VERSION "$Format:%h$"

NS_ :

BS_:

BU_: APB APP APS BCCEN BDY DAS DBG EAS EPAS EPAS2 EPAS3S EPB EPBM ESP GTW GTWU IBST IC MCU OCS PARK PARK3 RADAR RCM RT3000 SCCM SDM SEC TAS TAS2 TAS2DBG TOOL TPMS VCSEATD VCSEATP

BO_ 1860 VCSEATD_recallStatus: 1 VCSEATD
 SG_ VCSEATD_systemRecallStatus : 0|2@1+ (1,0) [0|3] "" GTW
 SG_ VCSEATD_seatRecallStatus : 2|2@1+ (1,0) [0|3] "" GTW

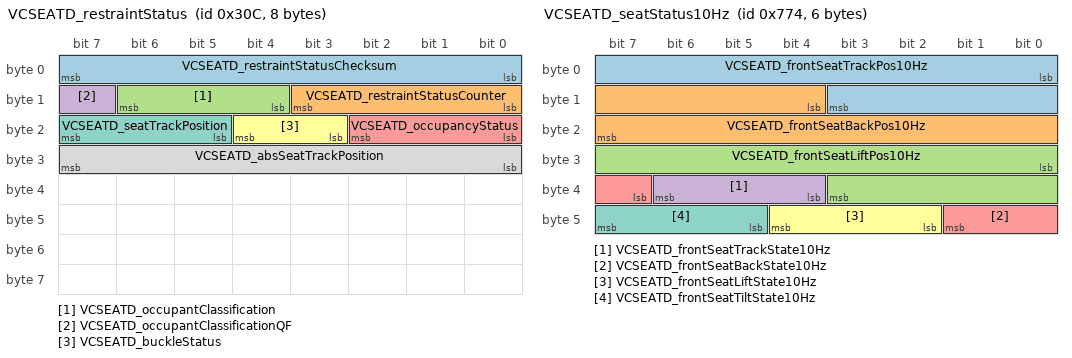
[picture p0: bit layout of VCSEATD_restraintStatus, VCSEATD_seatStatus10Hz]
BO_ 780 VCSEATD_restraintStatus: 8 VCSEATD
 SG_ VCSEATD_restraintStatusChecksum : 0|8@1+ (1,0) [0|255] "" Vector__XXX
 SG_ VCSEATD_restraintStatusCounter : 8|4@1+ (1,0) [0|15] "" Vector__XXX
 SG_ VCSEATD_occupantClassification : 12|3@1+ (1,0) [0|7] "" GTW
 SG_ VCSEATD_occupantClassificationQF : 15|1@1+ (1,0) [0|1] "" GTW
 SG_ VCSEATD_occupancyStatus : 16|3@1+ (1,0) [0|7] "" BCCEN,GTW
 SG_ VCSEATD_buckleStatus : 19|2@1+ (1,0) [0|3] "" APP,APS,GTW
 SG_ VCSEATD_seatTrackPosition : 21|3@1+ (1,0) [0|7] "" GTW
 SG_ VCSEATD_absSeatTrackPosition : 24|8@1+ (1,0) [0|254] "%" GTW

BO_ 1250 VCSEATD_seatStatus: 8 VCSEATD
 SG_ VCSEATD_seatStatusIndex M : 0|3@1+ (1,0) [0|5] "" GTW
 SG_ VCSEATD_frontSeatTrackPos m0 : 8|16@1- (1,0) [-32768|32767] "" GTW
 SG_ VCSEATD_frontSeatTrackCurrent m0 : 24|12@1- (0.01,0) [-20.48|20.47] "A" GTW
 SG_ VCSEATD_frontSeatTrackDuty m0 : 36|12@1- (0.1,0) [-204.8|204.7] "%" GTW
 SG_ VCSEATD_frontSeatTrackState m0 : 48|3@1+ (1,0) [0|5] "" GTW
 SG_ VCSEATD_frontSeatTrackCalibrated m0 : 51|1@1+ (1,0) [0|1] "" GTW
 SG_ VCSEATD_frontSeatTrackLog m0 : 52|1@1+ (1,0) [0|1] "" GTW
 SG_ VCSEATD_frontSeatBackPos m1 : 8|16@1- (1,0) [-32768|32767] "" GTW
 SG_ VCSEATD_frontSeatBackCurrent m1 : 24|12@1- (0.01,0) [-20.48|20.47] "A" GTW
 SG_ VCSEATD_frontSeatBackDuty m1 : 36|12@1- (0.1,0) [-204.8|204.7] "%" GTW
 SG_ VCSEATD_frontSeatBackState m1 : 48|3@1+ (1,0) [0|5] "" GTW
 SG_ VCSEATD_frontSeatBackCalibrated m1 : 51|1@1+ (1,0) [0|1] "" GTW
 SG_ VCSEATD_frontSeatBackLog m1 : 52|1@1+ (1,0) [0|1] "" GTW
 SG_ VCSEATD_frontSeatLiftPos m2 : 8|16@1- (1,0) [-32768|32767] "" GTW
 SG_ VCSEATD_frontSeatLiftCurrent m2 : 24|12@1- (0.01,0) [-20.48|20.47] "A" GTW
 SG_ VCSEATD_frontSeatLiftDuty m2 : 36|12@1- (0.1,0) [-204.8|204.7] "%" GTW
 SG_ VCSEATD_frontSeatLiftState m2 : 48|3@1+ (1,0) [0|5] "" GTW
 SG_ VCSEATD_frontSeatLiftCalibrated m2 : 51|1@1+ (1,0) [0|1] "" GTW
 SG_ VCSEATD_frontSeatLiftLog m2 : 52|1@1+ (1,0) [0|1] "" GTW
 SG_ VCSEATD_frontSeatTiltPos m3 : 8|16@1- (1,0) [-32768|32767] "" GTW
 SG_ VCSEATD_frontSeatTiltCurrent m3 : 24|12@1- (0.01,0) [-20.48|20.47] "A" GTW
 SG_ VCSEATD_frontSeatTiltDuty m3 : 36|12@1- (0.1,0) [-204.8|204.7] "%" GTW
 SG_ VCSEATD_frontSeatTiltState m3 : 48|3@1+ (1,0) [0|5] "" GTW
 SG_ VCSEATD_frontSeatTiltCalibrated m3 : 51|1@1+ (1,0) [0|1] "" GTW
 SG_ VCSEATD_frontSeatTiltLog m3 : 52|1@1+ (1,0) [0|1] "" GTW
 SG_ VCSEATD_lumbarAState m4 : 3|3@1+ (1,0) [0|5] "" GTW
 SG_ VCSEATD_lumbarBState m4 : 8|3@1+ (1,0) [0|5] "" GTW
 SG_ VCSEATD_lumbarAPressureHpa m4 : 16|16@1+ (1,0) [0|65535] "" GTW
 SG_ VCSEATD_lumbarBPressureHpa m4 : 32|16@1+ (1,0) [0|65535] "" GTW
 SG_ VCSEATD_lumbarActiveTooLongErr m4 : 48|1@1+ (1,0) [0|1] "" GTW
 SG_ VCSEATD_lumbarMaxPErr m4 : 49|1@1+ (1,0) [0|1] "" GTW
 SG_ VCSEATD_lumbarOvercurrentErr m4 : 50|1@1+ (1,0) [0|1] "" GTW
 SG_ VCSEATD_lumbarMaxOperatingPErr m4 : 51|1@1+ (1,0) [0|1] "" GTW
 SG_ VCSEATD_lumbarMinPErr m4 : 52|1@1+ (1,0) [0|1] "" GTW
 SG_ VCSEATD_lumbarGeneralErr m4 : 53|1@1+ (1,0) [0|1] "" GTW
 SG_ VCSEATD_lumbarDevMaxPumpPressA m4 : 54|1@1+ (1,0) [0|1] "" GTW
 SG_ VCSEATD_lumbarDevMaxPumpPressB m4 : 55|1@1+ (1,0) [0|1] "" GTW
 SG_ VCSEATD_frontSeatTrackPosReal m5 : 3|12@1- (1,0) [-2048|2047] "mm" GTW
 SG_ VCSEATD_frontSeatBackPosReal m5 : 16|12@1- (0.1,0) [-204.8|204.7] "deg" GTW
 SG_ VCSEATD_frontSeatLiftPosReal m5 : 28|12@1- (1,0) [-2048|2047] "mm" GTW
 SG_ VCSEATD_frontSeatTiltPosReal m5 : 40|12@1- (0.1,0) [-204.8|204.7] "deg" GTW

BO_ 1908 VCSEATD_seatStatus10Hz: 6 VCSEATD
 SG_ VCSEATD_frontSeatTrackPos10Hz : 0|12@1- (1,0) [-2048|2047] "" GTW
 SG_ VCSEATD_frontSeatBackPos10Hz : 12|12@1- (1,0) [-2048|2047] "" GTW
 SG_ VCSEATD_frontSeatLiftPos10Hz : 24|12@1- (1,0) [-2048|2047] "" GTW
 SG_ VCSEATD_frontSeatTrackState10Hz : 36|3@1+ (1,0) [0|5] "" GTW
 SG_ VCSEATD_frontSeatBackState10Hz : 39|3@1+ (1,0) [0|5] "" GTW
 SG_ VCSEATD_frontSeatLiftState10Hz : 42|3@1+ (1,0) [0|5] "" GTW
 SG_ VCSEATD_frontSeatTiltState10Hz : 45|3@1+ (1,0) [0|5] "" GTW

BO_ 738 VCSEATD_seatStatus2: 6 VCSEATD
 SG_ VCSEATD_seatStatus2Index M : 0|2@1+ (1,0) [0|3] "" Vector__XXX
 SG_ VCSEATD_frontSeatHeatCurrent m0 : 4|12@1+ (0.01,0) [0|40.95] "A" GTW
 SG_ VCSEATD_frontSeatHeatDuty m0 : 16|8@1+ (1,0) [0|255] "%" GTW
 SG_ VCSEATD_frontSeatHeatTmp m0 : 24|12@1- (0.05,0) [-40|80] "degC" GTW
 SG_ VCSEATD_frontSeatHeatTmpTarget m0 : 36|8@1- (0.5,0) [0|60] "degC" GTW
 SG_ VCSEATD_frontSeatHeatInhibited m0 : 44|1@1+ (1,0) [0|1] "" GTW
 SG_ VCSEATD_frontSeatHeatPowered m0 : 45|1@1+ (1,0) [0|1] "" Vector__XXX
 SG_ VCSEATD_frontSeatHeatTmpVoltage m1 : 4|10@1+ (0.01,0) [0|10.23] "V" Vector__XXX
 SG_ VCSEATD_frontOccupancyVoltage m2 : 4|10@1+ (0.01,0) [0|10.23] "V" GTW
 SG_ VCSEATD_frontBuckleVoltage m2 : 14|10@1+ (0.01,0) [0|10.23] "V" GTW
 SG_ VCSEATD_seatTrackPositionVoltage m2 : 24|10@1+ (0.01,0) [0|10.23] "V" Vector__XXX

BO_ 931 VCSEATD_status: 6 VCSEATD
 SG_ VCSEATD_statusIndex M : 0|1@1+ (1,0) [0|1] "" Vector__XXX
 SG_ VCSEATD_loadShedPriority m0 : 1|8@1+ (1,0) [0|255] "" Vector__XXX
 SG_ VCSEATD_vehiclePowerStateDBG m0 : 9|2@1+ (1,0) [0|3] "" GTW
 SG_ VCSEATD_OTAState m0 : 12|1@1+ (1,0) [0|1] "" GTW
 SG_ VCSEATD_5AVoltage m0 : 13|10@1+ (0.005443676098,0) [0|5.568880648254] "V" GTW
 SG_ VCSEATD_vbatProt m0 : 23|12@1+ (0.005443676098,0) [0|22.29185362131] "V" GTW
 SG_ VCSEATD_pcbaTemperature m0 : 35|11@1+ (0.125,-40) [-40|150] "degC" GTW

BO_ 964 VCSEATD_switchStatus: 7 VCSEATD
 SG_ VCSEATD_switchStatusIndex M : 0|2@1+ (1,0) [0|2] "" GTW
 SG_ VCSEATD_frontSeatTrackBack m0 : 8|2@1+ (1,0) [0|3] "" GTW
 SG_ VCSEATD_frontSeatTrackForward m0 : 10|2@1+ (1,0) [0|3] "" GTW
 SG_ VCSEATD_frontSeatTiltDown m0 : 12|2@1+ (1,0) [0|3] "" GTW
 SG_ VCSEATD_frontSeatTiltUp m0 : 14|2@1+ (1,0) [0|3] "" GTW
 SG_ VCSEATD_frontSeatLiftDown m0 : 16|2@1+ (1,0) [0|3] "" GTW
 SG_ VCSEATD_frontSeatLiftUp m0 : 18|2@1+ (1,0) [0|3] "" GTW
 SG_ VCSEATD_frontSeatBackrestBack m0 : 20|2@1+ (1,0) [0|3] "" GTW
 SG_ VCSEATD_frontSeatBackrestForward m0 : 22|2@1+ (1,0) [0|3] "" GTW
 SG_ VCSEATD_frontSeatLumbarDown m0 : 24|2@1+ (1,0) [0|3] "" GTW
 SG_ VCSEATD_frontSeatLumbarUp m0 : 26|2@1+ (1,0) [0|3] "" GTW
 SG_ VCSEATD_frontSeatLumbarIn m0 : 28|2@1+ (1,0) [0|3] "" GTW
 SG_ VCSEATD_frontSeatLumbarOut m0 : 30|2@1+ (1,0) [0|3] "" GTW
 SG_ VCSEATD_frontBuckleSwitch m0 : 48|2@1+ (1,0) [0|3] "" GTW
 SG_ VCSEATD_frontOccupancySwitch m0 : 50|2@1+ (1,0) [0|3] "" GTW

BO_ 1761 VCSEATD_udsResponse: 8 VCSEATD
 SG_ VCSEATD_udsResponseData_H : 7|32@0+ (1,0) [0|4294967295] "" GTW,GTWU
 SG_ VCSEATD_udsResponseData_L : 39|32@0+ (1,0) [0|4294967295] "" GTW,GTWU

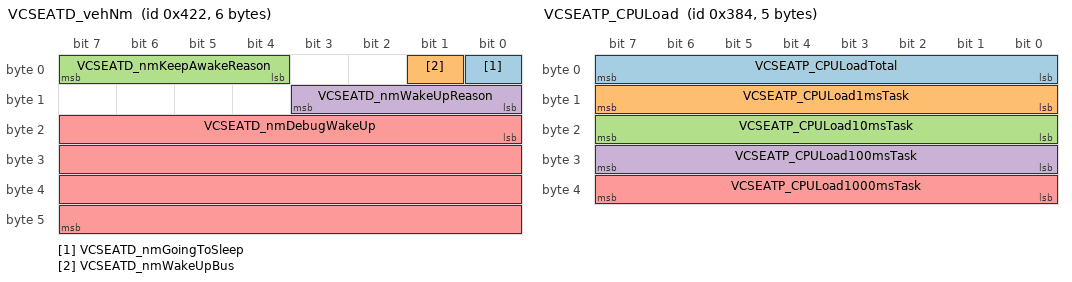
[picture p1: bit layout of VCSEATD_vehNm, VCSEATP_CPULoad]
BO_ 1058 VCSEATD_vehNm: 6 VCSEATD
 SG_ VCSEATD_nmGoingToSleep : 0|1@1+ (1,0) [0|1] "" Vector__XXX
 SG_ VCSEATD_nmWakeUpBus : 1|1@1+ (1,0) [0|1] "" Vector__XXX
 SG_ VCSEATD_nmKeepAwakeReason : 4|4@1+ (1,0) [0|15] "" GTW
 SG_ VCSEATD_nmWakeUpReason : 8|4@1+ (1,0) [0|15] "" GTW
 SG_ VCSEATD_nmDebugWakeUp : 16|32@1+ (1,0) [0|4294967295] "" GTW

BO_ 1890 VCSEATD_xcpResponse: 8 VCSEATD
 SG_ VCSEATD_xcpResponseData : 0|64@1+ (1,0) [0|1.84467440737096E+19] "" Vector__XXX

BO_ 900 VCSEATP_CPULoad: 5 VCSEATP
 SG_ VCSEATP_CPULoadTotal : 0|8@1+ (1,0) [0|255] "" Vector__XXX
 SG_ VCSEATP_CPULoad1msTask : 8|8@1+ (1,0) [0|255] "" Vector__XXX
 SG_ VCSEATP_CPULoad10msTask : 16|8@1+ (1,0) [0|255] "" Vector__XXX
 SG_ VCSEATP_CPULoad100msTask : 24|8@1+ (1,0) [0|255] "" Vector__XXX
 SG_ VCSEATP_CPULoad1000msTask : 32|8@1+ (1,0) [0|255] "" Vector__XXX

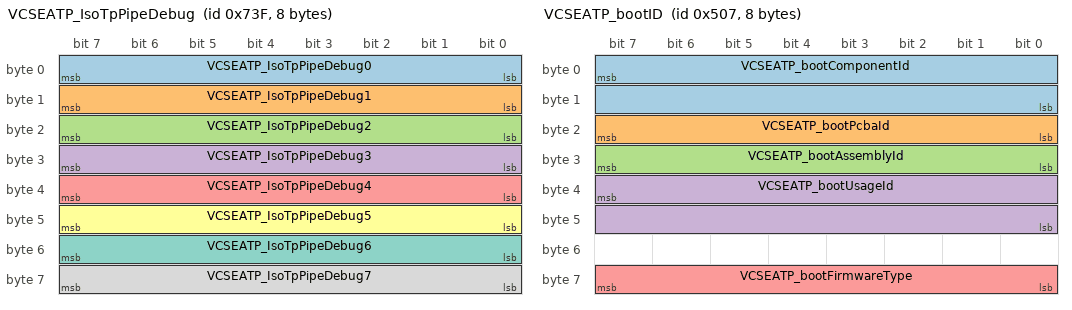
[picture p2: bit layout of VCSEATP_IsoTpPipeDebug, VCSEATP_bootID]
BO_ 1855 VCSEATP_IsoTpPipeDebug: 8 VCSEATP
 SG_ VCSEATP_IsoTpPipeDebug0 : 0|8@1+ (1,0) [0|255] "" Vector__XXX
 SG_ VCSEATP_IsoTpPipeDebug1 : 8|8@1+ (1,0) [0|255] "" Vector__XXX
 SG_ VCSEATP_IsoTpPipeDebug2 : 16|8@1+ (1,0) [0|255] "" Vector__XXX
 SG_ VCSEATP_IsoTpPipeDebug3 : 24|8@1+ (1,0) [0|255] "" Vector__XXX
 SG_ VCSEATP_IsoTpPipeDebug4 : 32|8@1+ (1,0) [0|255] "" Vector__XXX
 SG_ VCSEATP_IsoTpPipeDebug5 : 40|8@1+ (1,0) [0|255] "" Vector__XXX
 SG_ VCSEATP_IsoTpPipeDebug6 : 48|8@1+ (1,0) [0|255] "" Vector__XXX
 SG_ VCSEATP_IsoTpPipeDebug7 : 56|8@1+ (1,0) [0|255] "" Vector__XXX

BO_ 579 VCSEATP_LVPowerState: 1 VCSEATP
 SG_ VCSEATP_lumbarLVState : 0|2@1+ (1,0) [0|3] "" GTW

BO_ 1315 VCSEATP_alertCleared: 2 VCSEATP
 SG_ VCSEATP_alertClearedID : 0|15@1+ (1,0) [0|445] "" Vector__XXX

BO_ 1374 VCSEATP_alertLog: 8 VCSEATP
 SG_ VCSEATP_alertID M : 0|15@1+ (1,0) [0|445] "" GTW
 SG_ VCSEATP_alertType : 15|1@1+ (1,0) [0|1] "" GTW
 SG_ VCSEATP_a000_alertDataW0 m0 : 16|16@1+ (1,0) [0|65535] "" Vector__XXX
 SG_ VCSEATP_a000_alertDataW1 m0 : 32|16@1+ (1,0) [0|65535] "" Vector__XXX
 SG_ VCSEATP_a000_alertDataW2 m0 : 48|16@1+ (1,0) [0|65535] "" Vector__XXX
 SG_ VCSEATP_a001_InternalWatchdog m1 : 16|1@1+ (1,0) [0|1] "" GTW
 SG_ VCSEATP_a002_CPUUndervoltage m2 : 16|1@1+ (1,0) [0|1] "" GTW
 SG_ VCSEATP_a002_PowerOnReset m2 : 17|1@1+ (1,0) [0|1] "" GTW
 SG_ VCSEATP_a003_AssertID m3 : 16|16@1+ (1,0) [0|65535] "" GTW
 SG_ VCSEATP_a003_LineNumber m3 : 32|16@1+ (1,0) [0|65535] "" GTW
 SG_ VCSEATP_a003_Data m3 : 48|16@1+ (1,0) [0|65535] "" GTW
 SG_ VCSEATP_a005_busID0 m5 : 16|4@1+ (1,0) [0|15] "" GTW
 SG_ VCSEATP_a005_faults0 m5 : 20|12@1+ (1,0) [0|4095] "" GTW
 SG_ VCSEATP_a005_busID1 m5 : 32|4@1+ (1,0) [0|15] "" GTW
 SG_ VCSEATP_a005_faults1 m5 : 36|12@1+ (1,0) [0|4095] "" GTW
 SG_ VCSEATP_a010_UnderVoltDetected m10 : 16|1@1+ (1,0) [0|1] "" GTW
 SG_ VCSEATP_a010_UnderVoltTimeout m10 : 17|1@1+ (1,0) [0|1] "" GTW
 SG_ VCSEATP_a012_ClockError m12 : 16|1@1+ (1,0) [0|1] "" GTW
 SG_ VCSEATP_a012_FlashError m12 : 17|1@1+ (1,0) [0|1] "" GTW
 SG_ VCSEATP_a012_SoftwareReset m12 : 18|1@1+ (1,0) [0|1] "" GTW
 SG_ VCSEATP_a012_CheckstopReset m12 : 19|1@1+ (1,0) [0|1] "" GTW
 SG_ VCSEATP_a012_DebugReset m12 : 20|1@1+ (1,0) [0|1] "" GTW
 SG_ VCSEATP_a012_ExternalReset m12 : 21|1@1+ (1,0) [0|1] "" GTW
 SG_ VCSEATP_a013_LogQueueFull m13 : 16|1@1+ (1,0) [0|1] "" GTW
 SG_ VCSEATP_a013_ClearQueueFull m13 : 17|1@1+ (1,0) [0|1] "" GTW
 SG_ VCSEATP_a015_NVMMRecordNotFound m15 : 16|1@1+ (1,0) [0|1] "" GTW
 SG_ VCSEATP_a015_NVMMCRCMismatch m15 : 17|1@1+ (1,0) [0|1] "" GTW
 SG_ VCSEATP_a015_NVMMVersionMismatch m15 : 18|1@1+ (1,0) [0|1] "" GTW
 SG_ VCSEATP_a015_NVMMRecordUpgraded m15 : 19|1@1+ (1,0) [0|1] "" GTW
 SG_ VCSEATP_a015_NVMMMemOverflow m15 : 20|1@1+ (1,0) [0|1] "" GTW
 SG_ VCSEATP_a015_NVMMWriteFailed m15 : 21|1@1+ (1,0) [0|1] "" GTW
 SG_ VCSEATP_a021_Task1msLate m21 : 16|1@1+ (1,0) [0|1] "" GTW
 SG_ VCSEATP_a021_Task1msStarved m21 : 17|1@1+ (1,0) [0|1] "" GTW
 SG_ VCSEATP_a021_Task1msMissed m21 : 18|1@1+ (1,0) [0|1] "" GTW
 SG_ VCSEATP_a021_Task10msLate m21 : 19|1@1+ (1,0) [0|1] "" GTW
 SG_ VCSEATP_a021_Task10msStarved m21 : 20|1@1+ (1,0) [0|1] "" GTW
 SG_ VCSEATP_a021_Task10msMissed m21 : 21|1@1+ (1,0) [0|1] "" GTW
 SG_ VCSEATP_a021_Task100msLate m21 : 22|1@1+ (1,0) [0|1] "" GTW
 SG_ VCSEATP_a021_Task100msStarved m21 : 23|1@1+ (1,0) [0|1] "" GTW
 SG_ VCSEATP_a021_Task100msMissed m21 : 24|1@1+ (1,0) [0|1] "" GTW
 SG_ VCSEATP_a021_Task1000msLate m21 : 25|1@1+ (1,0) [0|1] "" GTW
 SG_ VCSEATP_a021_Task1000msStarved m21 : 26|1@1+ (1,0) [0|1] "" GTW
 SG_ VCSEATP_a021_Task1000msMissed m21 : 27|1@1+ (1,0) [0|1] "" GTW
 SG_ VCSEATP_a022_TaskInitErrorCount m22 : 16|8@1+ (1,0) [0|255] "" GTW
 SG_ VCSEATP_a022_TaskInitError0 m22 : 24|8@1+ (1,0) [0|255] "" GTW
 SG_ VCSEATP_a022_TaskInitError1 m22 : 32|8@1+ (1,0) [0|255] "" GTW
 SG_ VCSEATP_a022_TaskInitError2 m22 : 40|8@1+ (1,0) [0|255] "" GTW
 SG_ VCSEATP_a022_TaskInitError3 m22 : 48|8@1+ (1,0) [0|255] "" GTW
 SG_ VCSEATP_a022_TaskInitError4 m22 : 56|8@1+ (1,0) [0|255] "" GTW
 SG_ VCSEATP_a030_logId m30 : 16|4@1+ (1,0) [0|15] "" GTW
 SG_ VCSEATP_a031_uds_bytes_0 m31 : 16|8@1+ (1,0) [0|255] "" GTW
 SG_ VCSEATP_a031_uds_bytes_1 m31 : 24|8@1+ (1,0) [0|255] "" GTW
 SG_ VCSEATP_a031_uds_bytes_2 m31 : 32|8@1+ (1,0) [0|255] "" GTW
 SG_ VCSEATP_a031_uds_bytes_3 m31 : 40|8@1+ (1,0) [0|255] "" GTW
 SG_ VCSEATP_a031_uds_bytes_4 m31 : 48|8@1+ (1,0) [0|255] "" GTW
 SG_ VCSEATP_a031_uds_bytes_5 m31 : 56|8@1+ (1,0) [0|255] "" GTW
 SG_ VCSEATP_a041_CPULoadTotal m41 : 16|8@1+ (1,0) [0|255] "" GTW
 SG_ VCSEATP_a041_CPULoad1msTask m41 : 24|8@1+ (1,0) [0|255] "" GTW
 SG_ VCSEATP_a041_CPULoad10msTask m41 : 32|8@1+ (1,0) [0|255] "" GTW
 SG_ VCSEATP_a041_CPULoad100msTask m41 : 40|8@1+ (1,0) [0|255] "" GTW
 SG_ VCSEATP_a041_CPULoad1000msTask m41 : 48|8@1+ (1,0) [0|255] "" GTW
 SG_ VCSEATP_a041_CPULoadNVMMTask m41 : 56|8@1+ (1,0) [0|255] "" GTW
 SG_ VCSEATP_a042_Usage1msTask m42 : 16|8@1+ (1,0) [0|255] "" GTW
 SG_ VCSEATP_a042_Usage10msTask m42 : 24|8@1+ (1,0) [0|255] "" GTW
 SG_ VCSEATP_a042_Usage100msTask m42 : 32|8@1+ (1,0) [0|255] "" GTW
 SG_ VCSEATP_a042_Usage1000msTask m42 : 40|8@1+ (1,0) [0|255] "" GTW
 SG_ VCSEATP_a042_UsageUDSTask m42 : 48|8@1+ (1,0) [0|255] "" GTW
 SG_ VCSEATP_a042_UsageNVMMTask m42 : 56|8@1+ (1,0) [0|255] "" GTW
 SG_ VCSEATP_a043_CallTrace0 m43 : 16|24@1+ (1,0) [0|16777215] "" GTW
 SG_ VCSEATP_a043_CallTrace1 m43 : 40|24@1+ (1,0) [0|16777215] "" GTW
 SG_ VCSEATP_a044_CallTrace0 m44 : 16|24@1+ (1,0) [0|16777215] "" GTW
 SG_ VCSEATP_a044_CallTrace1 m44 : 40|24@1+ (1,0) [0|16777215] "" GTW
 SG_ VCSEATP_a045_CallTrace0 m45 : 16|24@1+ (1,0) [0|16777215] "" GTW
 SG_ VCSEATP_a045_CallTrace1 m45 : 40|24@1+ (1,0) [0|16777215] "" GTW
 SG_ VCSEATP_a046_CallTrace0 m46 : 16|24@1+ (1,0) [0|16777215] "" GTW
 SG_ VCSEATP_a046_CallTrace1 m46 : 40|24@1+ (1,0) [0|16777215] "" GTW
 SG_ VCSEATP_a058_voltageDrop m58 : 16|12@1+ (0.005443676098,0) [0|22.29185362131] "V" GTW
 SG_ VCSEATP_a058_current m58 : 28|11@1+ (0.1,0) [0|204.7] "A" GTW
 SG_ VCSEATP_a058_prevREstimate m58 : 39|12@1+ (0.00061,0) [0|2.49795] "Ohms" GTW
 SG_ VCSEATP_a058_newREstimate m58 : 51|12@1+ (0.00061,0) [0|2.49795] "Ohms" GTW
 SG_ VCSEATP_a058_faultReason m58 : 63|1@1+ (1,0) [0|1] "" GTW
 SG_ VCSEATP_a059_voltageDrop m59 : 16|12@1+ (0.005443676098,0) [0|22.29185362131] "V" GTW
 SG_ VCSEATP_a059_resistanceEstimate m59 : 28|12@1+ (0.00244,0) [0|9.9918] "Ohms" GTW
 SG_ VCSEATP_a059_current m59 : 40|12@1+ (0.05,0) [0|204.75] "A" GTW
 SG_ VCSEATP_a060_lockoutDisabled m60 : 16|1@1+ (1,0) [0|1] "" GTW
 SG_ VCSEATP_a060_resetUnlocked m60 : 17|1@1+ (1,0) [0|1] "" GTW
 SG_ VCSEATP_a063_switchChannel m63 : 16|8@1+ (1,0) [0|255] "" GTW
 SG_ VCSEATP_a063_switchType m63 : 24|8@1+ (1,0) [0|255] "" GTW
 SG_ VCSEATP_a063_ADCVoltage m63 : 32|8@1+ (0.025,0) [0|6.375] "V" GTW
 SG_ VCSEATP_a063_disconnected m63 : 40|1@1+ (1,0) [0|1] "" GTW
 SG_ VCSEATP_a063_indeterminate m63 : 41|1@1+ (1,0) [0|1] "" GTW
 SG_ VCSEATP_a063_stuckActive m63 : 42|1@1+ (1,0) [0|1] "" GTW
 SG_ VCSEATP_a063_faulted m63 : 43|1@1+ (1,0) [0|1] "" GTW
 SG_ VCSEATP_a064_busBitField m64 : 16|8@1+ (1,0) [0|255] "" GTW
 SG_ VCSEATP_a200_voltage m200 : 16|7@1+ (0.15,0) [0|19] "V" GTW
 SG_ VCSEATP_a200_motorChannels m200 : 23|16@1+ (1,0) [0|65535] "" GTW
 SG_ VCSEATP_a200_encoderVoltage m200 : 39|6@1+ (0.15,0) [0|9] "V" GTW
 SG_ VCSEATP_a200_encoder8vEn m200 : 45|1@1+ (1,0) [0|1] "" GTW
 SG_ VCSEATP_a200_motorPosition m200 : 46|7@1+ (20,0) [0|2540] "ticks" GTW
 SG_ VCSEATP_a200_phantomTicks m200 : 53|11@1- (1,0) [-1024|1023] "ticks" GTW
 SG_ VCSEATP_a201_voltage m201 : 16|7@1+ (0.15,0) [0|19] "V" GTW
 SG_ VCSEATP_a201_motorChannels m201 : 24|16@1+ (1,0) [0|65535] "" GTW
 SG_ VCSEATP_a218_motorChannels m218 : 16|16@1+ (1,0) [0|65535] "" GTW
 SG_ VCSEATP_a218_voltage m218 : 32|10@1+ (0.02,0) [0|19] "V" GTW
 SG_ VCSEATP_a218_motorCurrent m218 : 42|10@1- (0.04,0) [-20|20] "A" GTW
 SG_ VCSEATP_a218_motorDutyCycle m218 : 52|10@1+ (0.1,0) [0|100] "A" GTW
 SG_ VCSEATP_a219_motorChannels m219 : 16|16@1+ (1,0) [0|65535] "" GTW
 SG_ VCSEATP_a219_dropoutCount m219 : 32|12@1+ (1,0) [0|4095] "" GTW
 SG_ VCSEATP_a220_seatMotorCalibrated m220 : 16|1@1+ (1,0) [0|1] "" GTW
 SG_ VCSEATP_a220_seatMotorCurrent m220 : 17|12@1- (0.01,0) [-20.48|20.47] "A" GTW
 SG_ VCSEATP_a220_seatMotorPosReal m220 : 32|12@1- (1,0) [-2048|2047] "mm" GTW
 SG_ VCSEATP_a220_seatMotorState m220 : 44|3@1+ (1,0) [0|5] "" GTW
 SG_ VCSEATP_a220_seatSwitchBack m220 : 48|2@1+ (1,0) [0|3] "" GTW
 SG_ VCSEATP_a220_seatSwitchForward m220 : 50|2@1+ (1,0) [0|3] "" GTW
 SG_ VCSEATP_a221_seatMotorCalibrated m221 : 16|1@1+ (1,0) [0|1] "" GTW
 SG_ VCSEATP_a221_seatMotorCurrent m221 : 17|12@1- (0.01,0) [-20.48|20.47] "A" GTW
 SG_ VCSEATP_a221_seatMotorPosReal m221 : 32|12@1- (1,0) [-2048|2047] "mm" GTW
 SG_ VCSEATP_a221_seatMotorState m221 : 44|3@1+ (1,0) [0|5] "" GTW
 SG_ VCSEATP_a221_seatSwitchBack m221 : 48|2@1+ (1,0) [0|3] "" GTW
 SG_ VCSEATP_a221_seatSwitchForward m221 : 50|2@1+ (1,0) [0|3] "" GTW
 SG_ VCSEATP_a222_seatMotorCalibrated m222 : 16|1@1+ (1,0) [0|1] "" GTW
 SG_ VCSEATP_a222_seatMotorCurrent m222 : 17|12@1- (0.01,0) [-20.48|20.47] "A" GTW
 SG_ VCSEATP_a222_seatMotorPosReal m222 : 32|12@1- (1,0) [-2048|2047] "mm" GTW
 SG_ VCSEATP_a222_seatMotorState m222 : 44|3@1+ (1,0) [0|5] "" GTW
 SG_ VCSEATP_a222_seatSwitchBack m222 : 48|2@1+ (1,0) [0|3] "" GTW
 SG_ VCSEATP_a222_seatSwitchForward m222 : 50|2@1+ (1,0) [0|3] "" GTW
 SG_ VCSEATP_a223_seatMotorCalibrated m223 : 16|1@1+ (1,0) [0|1] "" GTW
 SG_ VCSEATP_a223_seatMotorCurrent m223 : 17|12@1- (0.01,0) [-20.48|20.47] "A" GTW
 SG_ VCSEATP_a223_seatMotorPosReal m223 : 32|12@1- (1,0) [-2048|2047] "mm" GTW
 SG_ VCSEATP_a223_seatMotorState m223 : 44|3@1+ (1,0) [0|5] "" GTW
 SG_ VCSEATP_a223_seatSwitchBack m223 : 48|2@1+ (1,0) [0|3] "" GTW
 SG_ VCSEATP_a223_seatSwitchForward m223 : 50|2@1+ (1,0) [0|3] "" GTW
 SG_ VCSEATP_a224_seatMotorCalibrated m224 : 16|1@1+ (1,0) [0|1] "" GTW
 SG_ VCSEATP_a224_seatMotorCurrent m224 : 17|12@1- (0.01,0) [-20.48|20.47] "A" GTW
 SG_ VCSEATP_a224_seatMotorState m224 : 29|3@1+ (1,0) [0|5] "" GTW
 SG_ VCSEATP_a224_seatSwitchBack m224 : 32|2@1+ (1,0) [0|3] "" GTW
 SG_ VCSEATP_a224_seatSwitchForward m224 : 34|2@1+ (1,0) [0|3] "" GTW
 SG_ VCSEATP_a225_seatMotorCalibrated m225 : 16|1@1+ (1,0) [0|1] "" GTW
 SG_ VCSEATP_a225_seatMotorCurrent m225 : 17|12@1- (0.01,0) [-20.48|20.47] "A" GTW
 SG_ VCSEATP_a225_seatMotorState m225 : 29|3@1+ (1,0) [0|5] "" GTW
 SG_ VCSEATP_a225_seatSwitchBack m225 : 32|2@1+ (1,0) [0|3] "" GTW
 SG_ VCSEATP_a225_seatSwitchForward m225 : 34|2@1+ (1,0) [0|3] "" GTW
 SG_ VCSEATP_a226_seatMotorCalibrated m226 : 16|1@1+ (1,0) [0|1] "" GTW
 SG_ VCSEATP_a226_seatMotorCurrent m226 : 17|12@1- (0.01,0) [-20.48|20.47] "A" GTW
 SG_ VCSEATP_a226_seatMotorState m226 : 29|3@1+ (1,0) [0|5] "" GTW
 SG_ VCSEATP_a226_seatSwitchBack m226 : 32|2@1+ (1,0) [0|3] "" GTW
 SG_ VCSEATP_a226_seatSwitchForward m226 : 34|2@1+ (1,0) [0|3] "" GTW
 SG_ VCSEATP_a227_seatMotorCalibrated m227 : 16|1@1+ (1,0) [0|1] "" GTW
 SG_ VCSEATP_a227_seatMotorCurrent m227 : 17|12@1- (0.01,0) [-20.48|20.47] "A" GTW
 SG_ VCSEATP_a227_seatMotorState m227 : 29|3@1+ (1,0) [0|5] "" GTW
 SG_ VCSEATP_a227_seatSwitchBack m227 : 32|2@1+ (1,0) [0|3] "" GTW
 SG_ VCSEATP_a227_seatSwitchForward m227 : 34|2@1+ (1,0) [0|3] "" GTW
 SG_ VCSEATP_a228_seatMotorCalibrated m228 : 16|1@1+ (1,0) [0|1] "" GTW
 SG_ VCSEATP_a228_seatMotorCurrent m228 : 17|12@1- (0.01,0) [-20.48|20.47] "A" GTW
 SG_ VCSEATP_a228_seatMotorPosReal m228 : 32|12@1- (1,0) [-2048|2047] "mm" GTW
 SG_ VCSEATP_a228_seatMotorState m228 : 44|3@1+ (1,0) [0|5] "" GTW
 SG_ VCSEATP_a228_seatSwitchBack m228 : 48|2@1+ (1,0) [0|3] "" GTW
 SG_ VCSEATP_a228_seatSwitchForward m228 : 50|2@1+ (1,0) [0|3] "" GTW
 SG_ VCSEATP_a229_seatMotorCalibrated m229 : 16|1@1+ (1,0) [0|1] "" GTW
 SG_ VCSEATP_a229_seatMotorCurrent m229 : 17|12@1- (0.01,0) [-20.48|20.47] "A" GTW
 SG_ VCSEATP_a229_seatMotorPosReal m229 : 32|12@1- (1,0) [-2048|2047] "mm" GTW
 SG_ VCSEATP_a229_seatMotorState m229 : 44|3@1+ (1,0) [0|5] "" GTW
 SG_ VCSEATP_a229_seatSwitchBack m229 : 48|2@1+ (1,0) [0|3] "" GTW
 SG_ VCSEATP_a229_seatSwitchForward m229 : 50|2@1+ (1,0) [0|3] "" GTW
 SG_ VCSEATP_a230_seatMotorCalibrated m230 : 16|1@1+ (1,0) [0|1] "" GTW
 SG_ VCSEATP_a230_seatMotorCurrent m230 : 17|12@1- (0.01,0) [-20.48|20.47] "A" GTW
 SG_ VCSEATP_a230_seatMotorPosReal m230 : 32|12@1- (1,0) [-2048|2047] "mm" GTW
 SG_ VCSEATP_a230_seatMotorState m230 : 44|3@1+ (1,0) [0|5] "" GTW
 SG_ VCSEATP_a230_seatSwitchBack m230 : 48|2@1+ (1,0) [0|3] "" GTW
 SG_ VCSEATP_a230_seatSwitchForward m230 : 50|2@1+ (1,0) [0|3] "" GTW
 SG_ VCSEATP_a231_seatMotorCalibrated m231 : 16|1@1+ (1,0) [0|1] "" GTW
 SG_ VCSEATP_a231_seatMotorCurrent m231 : 17|12@1- (0.01,0) [-20.48|20.47] "A" GTW
 SG_ VCSEATP_a231_seatMotorPosReal m231 : 32|12@1- (1,0) [-2048|2047] "mm" GTW
 SG_ VCSEATP_a231_seatMotorState m231 : 44|3@1+ (1,0) [0|5] "" GTW
 SG_ VCSEATP_a231_seatSwitchBack m231 : 48|2@1+ (1,0) [0|3] "" GTW
 SG_ VCSEATP_a231_seatSwitchForward m231 : 50|2@1+ (1,0) [0|3] "" GTW
 SG_ VCSEATP_a232_seatMotorCurrent m232 : 16|12@1- (0.01,0) [-20.48|20.47] "A" GTW
 SG_ VCSEATP_a232_seatMotorPosReal m232 : 28|12@1- (1,0) [-2048|2047] "mm" GTW
 SG_ VCSEATP_a232_seatMotorState m232 : 40|3@1+ (1,0) [0|5] "" GTW
 SG_ VCSEATP_a232_seatSwitchBack m232 : 43|2@1+ (1,0) [0|3] "" GTW
 SG_ VCSEATP_a232_seatSwitchForward m232 : 45|2@1+ (1,0) [0|3] "" GTW
 SG_ VCSEATP_a233_seatMotorCurrent m233 : 16|12@1- (0.01,0) [-20.48|20.47] "A" GTW
 SG_ VCSEATP_a233_seatMotorPosReal m233 : 28|12@1- (1,0) [-2048|2047] "mm" GTW
 SG_ VCSEATP_a233_seatMotorState m233 : 40|3@1+ (1,0) [0|5] "" GTW
 SG_ VCSEATP_a233_seatSwitchBack m233 : 43|2@1+ (1,0) [0|3] "" GTW
 SG_ VCSEATP_a233_seatSwitchForward m233 : 45|2@1+ (1,0) [0|3] "" GTW
 SG_ VCSEATP_a234_seatMotorCurrent m234 : 16|12@1- (0.01,0) [-20.48|20.47] "A" GTW
 SG_ VCSEATP_a234_seatMotorPosReal m234 : 28|12@1- (1,0) [-2048|2047] "mm" GTW
 SG_ VCSEATP_a234_seatMotorState m234 : 40|3@1+ (1,0) [0|5] "" GTW
 SG_ VCSEATP_a234_seatSwitchBack m234 : 43|2@1+ (1,0) [0|3] "" GTW
 SG_ VCSEATP_a234_seatSwitchForward m234 : 45|2@1+ (1,0) [0|3] "" GTW
 SG_ VCSEATP_a235_seatMotorCurrent m235 : 16|12@1- (0.01,0) [-20.48|20.47] "A" GTW
 SG_ VCSEATP_a235_seatMotorPosReal m235 : 28|12@1- (1,0) [-2048|2047] "mm" GTW
 SG_ VCSEATP_a235_seatMotorState m235 : 40|3@1+ (1,0) [0|5] "" GTW
 SG_ VCSEATP_a235_seatSwitchBack m235 : 43|2@1+ (1,0) [0|3] "" GTW
 SG_ VCSEATP_a235_seatSwitchForward m235 : 45|2@1+ (1,0) [0|3] "" GTW
 SG_ VCSEATP_a236_lumbarAPressureHpa m236 : 16|16@1+ (1,0) [0|65535] "" GTW
 SG_ VCSEATP_a236_lumbarBPressureHpa m236 : 32|16@1+ (1,0) [0|65535] "" GTW
 SG_ VCSEATP_a236_lumbarDiagStatus m236 : 48|1@1+ (1,0) [0|1] "" GTW
 SG_ VCSEATP_a236_lumbarAState m236 : 49|3@1+ (1,0) [0|5] "" GTW
 SG_ VCSEATP_a236_lumbarBState m236 : 52|3@1+ (1,0) [0|5] "" GTW
 SG_ VCSEATP_a237_lumbarAPressureHpa m237 : 16|16@1+ (1,0) [0|65535] "" GTW
 SG_ VCSEATP_a237_lumbarBPressureHpa m237 : 32|16@1+ (1,0) [0|65535] "" GTW
 SG_ VCSEATP_a237_lumbarDiagStatus m237 : 48|1@1+ (1,0) [0|1] "" GTW
 SG_ VCSEATP_a237_lumbarAState m237 : 49|3@1+ (1,0) [0|5] "" GTW
 SG_ VCSEATP_a237_lumbarBState m237 : 52|3@1+ (1,0) [0|5] "" GTW
 SG_ VCSEATP_a238_lumbarAPressureHpa m238 : 16|16@1+ (1,0) [0|65535] "" GTW
 SG_ VCSEATP_a238_lumbarBPressureHpa m238 : 32|16@1+ (1,0) [0|65535] "" GTW
 SG_ VCSEATP_a238_lumbarDiagStatus m238 : 48|1@1+ (1,0) [0|1] "" GTW
 SG_ VCSEATP_a238_lumbarAState m238 : 49|3@1+ (1,0) [0|5] "" GTW
 SG_ VCSEATP_a238_lumbarBState m238 : 52|3@1+ (1,0) [0|5] "" GTW
 SG_ VCSEATP_a239_seatHeatCurrent m239 : 16|12@1+ (0.01,0) [0|40.95] "A" GTW
 SG_ VCSEATP_a239_seatHeatTmp m239 : 28|12@1- (0.05,0) [-40|80] "degC" GTW
 SG_ VCSEATP_a239_seatHeatTmpTarget m239 : 40|8@1- (0.5,0) [0|60] "degC" GTW
 SG_ VCSEATP_a240_seatHeatCurrent m240 : 16|12@1+ (0.01,0) [0|40.95] "A" GTW
 SG_ VCSEATP_a240_seatHeatTmp m240 : 28|12@1- (0.05,0) [-40|80] "degC" GTW
 SG_ VCSEATP_a241_seatHeatTmp m241 : 16|12@1- (0.05,0) [-40|80] "degC" GTW
 SG_ VCSEATP_a241_seatHeatTmpTarget m241 : 32|8@1- (0.5,0) [0|60] "degC" GTW
 SG_ VCSEATP_a242_snsShortCircuit m242 : 16|1@1+ (1,0) [0|1] "" GTW
 SG_ VCSEATP_a242_snsDisconnect m242 : 17|1@1+ (1,0) [0|1] "" GTW
 SG_ VCSEATP_a242_snsRateChangeUp m242 : 18|1@1+ (1,0) [0|1] "" GTW
 SG_ VCSEATP_a242_snsRateChangeDown m242 : 19|1@1+ (1,0) [0|1] "" GTW
 SG_ VCSEATP_a251_seatMotorCurrent m251 : 16|12@1- (0.01,0) [-20.48|20.47] "A" GTW
 SG_ VCSEATP_a251_seatMotorPosReal m251 : 28|12@1- (1,0) [-2048|2047] "mm" GTW
 SG_ VCSEATP_a251_seatMotorState m251 : 40|3@1+ (1,0) [0|5] "" GTW
 SG_ VCSEATP_a251_seatSwitchBack m251 : 43|2@1+ (1,0) [0|3] "" GTW
 SG_ VCSEATP_a251_seatSwitchForward m251 : 45|2@1+ (1,0) [0|3] "" GTW
 SG_ VCSEATP_a252_seatMotorCurrent m252 : 16|12@1- (0.01,0) [-20.48|20.47] "A" GTW
 SG_ VCSEATP_a252_seatMotorPosReal m252 : 28|12@1- (1,0) [-2048|2047] "mm" GTW
 SG_ VCSEATP_a252_seatMotorState m252 : 40|3@1+ (1,0) [0|5] "" GTW
 SG_ VCSEATP_a252_seatSwitchBack m252 : 43|2@1+ (1,0) [0|3] "" GTW
 SG_ VCSEATP_a252_seatSwitchForward m252 : 45|2@1+ (1,0) [0|3] "" GTW
 SG_ VCSEATP_a253_seatMotorCurrent m253 : 16|12@1- (0.01,0) [-20.48|20.47] "A" GTW
 SG_ VCSEATP_a253_seatMotorPosReal m253 : 28|12@1- (1,0) [-2048|2047] "mm" GTW
 SG_ VCSEATP_a253_seatMotorState m253 : 40|3@1+ (1,0) [0|5] "" GTW
 SG_ VCSEATP_a253_seatSwitchBack m253 : 43|2@1+ (1,0) [0|3] "" GTW
 SG_ VCSEATP_a253_seatSwitchForward m253 : 45|2@1+ (1,0) [0|3] "" GTW
 SG_ VCSEATP_a254_seatMotorCurrent m254 : 16|12@1- (0.01,0) [-20.48|20.47] "A" GTW
 SG_ VCSEATP_a254_seatMotorPosReal m254 : 28|12@1- (1,0) [-2048|2047] "mm" GTW
 SG_ VCSEATP_a254_seatMotorState m254 : 40|3@1+ (1,0) [0|5] "" GTW
 SG_ VCSEATP_a254_seatSwitchBack m254 : 43|2@1+ (1,0) [0|3] "" GTW
 SG_ VCSEATP_a254_seatSwitchForward m254 : 45|2@1+ (1,0) [0|3] "" GTW
 SG_ VCSEATP_a263_seatMotorCurrent m263 : 16|12@1- (0.01,0) [-20.48|20.47] "A" GTW
 SG_ VCSEATP_a263_seatMotorDCurrent m263 : 28|12@1- (0.01,0) [-20.48|20.47] "A" GTW
 SG_ VCSEATP_a263_seatMotorPosReal m263 : 40|12@1- (1,0) [-2048|2047] "mm" GTW
 SG_ VCSEATP_a263_seatMotorState m263 : 52|3@1+ (1,0) [0|5] "" GTW
 SG_ VCSEATP_a264_seatMotorCurrent m264 : 16|12@1- (0.01,0) [-20.48|20.47] "A" GTW
 SG_ VCSEATP_a264_seatMotorDCurrent m264 : 28|12@1- (0.01,0) [-20.48|20.47] "A" GTW
 SG_ VCSEATP_a264_seatMotorPosReal m264 : 40|12@1- (1,0) [-2048|2047] "mm" GTW
 SG_ VCSEATP_a264_seatMotorState m264 : 52|3@1+ (1,0) [0|5] "" GTW
 SG_ VCSEATP_a265_seatMotorCurrent m265 : 16|12@1- (0.01,0) [-20.48|20.47] "A" GTW
 SG_ VCSEATP_a265_seatMotorDCurrent m265 : 28|12@1- (0.01,0) [-20.48|20.47] "A" GTW
 SG_ VCSEATP_a265_seatMotorPosReal m265 : 40|12@1- (1,0) [-2048|2047] "mm" GTW
 SG_ VCSEATP_a265_seatMotorState m265 : 52|3@1+ (1,0) [0|5] "" GTW
 SG_ VCSEATP_a266_seatMotorCurrent m266 : 16|12@1- (0.01,0) [-20.48|20.47] "A" GTW
 SG_ VCSEATP_a266_seatMotorDCurrent m266 : 28|12@1- (0.01,0) [-20.48|20.47] "A" GTW
 SG_ VCSEATP_a266_seatMotorPosReal m266 : 40|12@1- (1,0) [-2048|2047] "mm" GTW
 SG_ VCSEATP_a266_seatMotorState m266 : 52|3@1+ (1,0) [0|5] "" GTW
 SG_ VCSEATP_a267_seatMotorCurrent m267 : 16|12@1- (0.01,0) [-20.48|20.47] "A" GTW
 SG_ VCSEATP_a267_seatMotorDCurrent m267 : 28|12@1- (0.01,0) [-20.48|20.47] "A" GTW
 SG_ VCSEATP_a267_seatMotorPosReal m267 : 40|12@1- (1,0) [-2048|2047] "mm" GTW
 SG_ VCSEATP_a267_seatMotorState m267 : 52|3@1+ (1,0) [0|5] "" GTW
 SG_ VCSEATP_a268_seatMotorCurrent m268 : 16|12@1- (0.01,0) [-20.48|20.47] "A" GTW
 SG_ VCSEATP_a268_seatMotorDCurrent m268 : 28|12@1- (0.01,0) [-20.48|20.47] "A" GTW
 SG_ VCSEATP_a268_seatMotorPosReal m268 : 40|12@1- (1,0) [-2048|2047] "mm" GTW
 SG_ VCSEATP_a268_seatMotorState m268 : 52|3@1+ (1,0) [0|5] "" GTW
 SG_ VCSEATP_a269_seatMotorCurrent m269 : 16|12@1- (0.01,0) [-20.48|20.47] "A" GTW
 SG_ VCSEATP_a269_seatMotorDCurrent m269 : 28|12@1- (0.01,0) [-20.48|20.47] "A" GTW
 SG_ VCSEATP_a269_seatMotorPosReal m269 : 40|12@1- (1,0) [-2048|2047] "mm" GTW
 SG_ VCSEATP_a269_seatMotorState m269 : 52|3@1+ (1,0) [0|5] "" GTW
 SG_ VCSEATP_a270_seatMotorCurrent m270 : 16|12@1- (0.01,0) [-20.48|20.47] "A" GTW
 SG_ VCSEATP_a270_seatMotorDCurrent m270 : 28|12@1- (0.01,0) [-20.48|20.47] "A" GTW
 SG_ VCSEATP_a270_seatMotorPosReal m270 : 40|12@1- (1,0) [-2048|2047] "mm" GTW
 SG_ VCSEATP_a270_seatMotorState m270 : 52|3@1+ (1,0) [0|5] "" GTW
 SG_ VCSEATP_a290_occupancySensorV m290 : 16|12@1- (0.01,0) [-20.48|20.47] "V" GTW
 SG_ VCSEATP_a290_railVoltage m290 : 28|12@1- (0.01,0) [-20.48|20.47] "V" GTW
 SG_ VCSEATP_a291_buckleSensorVoltage m291 : 16|12@1+ (0.01,0) [0|40.95] "V" GTW
 SG_ VCSEATP_a291_railVoltage m291 : 28|12@1+ (0.01,0) [0|40.95] "V" GTW
 SG_ VCSEATP_a380_ocsCushionRaw m380 : 16|16@1+ (1,0) [0|65535] "" GTW
 SG_ VCSEATP_a380_ocsSpareRaw m380 : 32|16@1+ (1,0) [0|65535] "" GTW
 SG_ VCSEATP_a380_ocsTempRaw m380 : 48|9@1+ (0.5,-45) [-45|130] "degC" GTW
 SG_ VCSEATP_a380_ocsHumidityRaw m380 : 57|7@1+ (1,0) [0|100] "%" GTW
 SG_ VCSEATP_a381_ocsCushionRaw m381 : 16|16@1+ (1,0) [0|65535] "" GTW
 SG_ VCSEATP_a381_ocsSpareRaw m381 : 32|16@1+ (1,0) [0|65535] "" GTW
 SG_ VCSEATP_a381_ocsTempRaw m381 : 48|9@1+ (0.5,-45) [-45|130] "degC" GTW
 SG_ VCSEATP_a381_ocsHumidityRaw m381 : 57|7@1+ (1,0) [0|100] "%" GTW
 SG_ VCSEATP_a382_ocsCushionRaw m382 : 16|16@1+ (1,0) [0|65535] "" GTW
 SG_ VCSEATP_a382_ocsSpareRaw m382 : 32|16@1+ (1,0) [0|65535] "" GTW
 SG_ VCSEATP_a382_ocsTempRaw m382 : 48|9@1+ (0.5,-45) [-45|130] "degC" GTW
 SG_ VCSEATP_a382_ocsHumidityRaw m382 : 57|7@1+ (1,0) [0|100] "%" GTW
 SG_ VCSEATP_a386_ocsCushionRaw m386 : 16|16@1+ (1,0) [0|65535] "" GTW
 SG_ VCSEATP_a386_ocsSpareRaw m386 : 32|16@1+ (1,0) [0|65535] "" GTW
 SG_ VCSEATP_a386_ocsTempRaw m386 : 48|9@1+ (0.5,-45) [-45|130] "degC" GTW
 SG_ VCSEATP_a386_ocsHumidityRaw m386 : 57|7@1+ (1,0) [0|100] "%" GTW
 SG_ VCSEATP_a387_ocsCushionRaw m387 : 16|16@1+ (1,0) [0|65535] "" GTW
 SG_ VCSEATP_a387_ocsSpareRaw m387 : 32|16@1+ (1,0) [0|65535] "" GTW
 SG_ VCSEATP_a387_ocsTempRaw m387 : 48|9@1+ (0.5,-45) [-45|130] "degC" GTW
 SG_ VCSEATP_a387_ocsHumidityRaw m387 : 57|7@1+ (1,0) [0|100] "%" GTW
 SG_ VCSEATP_a388_ocsCushionRaw m388 : 16|16@1+ (1,0) [0|65535] "" GTW
 SG_ VCSEATP_a388_ocsSpareRaw m388 : 32|16@1+ (1,0) [0|65535] "" GTW
 SG_ VCSEATP_a388_ocsTempRaw m388 : 48|9@1+ (0.5,-45) [-45|130] "degC" GTW
 SG_ VCSEATP_a388_ocsHumidityRaw m388 : 57|7@1+ (1,0) [0|100] "%" GTW
 SG_ VCSEATP_a389_ocsTempRaw m389 : 16|16@1+ (0.002670328832,-45) [-45|130] "degC" GTW
 SG_ VCSEATP_a389_ocsHumidityRaw m389 : 32|16@1+ (0.00152590219,0) [0|100] "%" GTW
 SG_ VCSEATP_a394_ocsCushionCalib m394 : 16|16@1+ (1,0) [0|65535] "" GTW
 SG_ VCSEATP_a396_ocsSpareCalib m396 : 16|16@1+ (1,0) [0|65535] "" GTW
 SG_ VCSEATP_a397_ocsTempCalib m397 : 16|16@1+ (0.002670328832,-45) [-45|130] "degC" GTW
 SG_ VCSEATP_a397_ocsHumidityCalib m397 : 32|16@1+ (0.00152590219,0) [0|100] "%" GTW
 SG_ VCSEATP_a400_ocsCushionRaw m400 : 16|16@1+ (1,0) [0|65535] "" GTW
 SG_ VCSEATP_a401_ocsCushionRaw m401 : 16|13@1+ (1,23000) [23000|28000] "-" GTW
 SG_ VCSEATP_a401_ocsSpareRaw m401 : 32|13@1+ (1,23000) [23000|28000] "-" GTW
 SG_ VCSEATP_a401_ocsTempRaw m401 : 48|8@1+ (0.5,-40) [-40|85] "degC" GTW
 SG_ VCSEATP_a401_ocsHumidityRaw m401 : 56|6@1+ (2,0) [0|95] "%" GTW
 SG_ VCSEATP_a401_occupancySwitch m401 : 62|2@1+ (1,0) [0|3] "" GTW
 SG_ VCSEATP_a402_tosRelative m402 : 16|16@1- (1,0) [-32768|32767] "" GTW
 SG_ VCSEATP_a402_tosDeltaOffset m402 : 32|12@1- (1,0) [-2048|2047] "" GTW
 SG_ VCSEATP_a403_tosDeltaEmpty m403 : 16|16@1- (1,0) [-32768|32767] "" GTW
 SG_ VCSEATP_a403_tosDeltaOffset m403 : 32|12@1- (1,0) [-2048|2047] "" GTW
 SG_ VCSEATP_a404_tosDeltaCM m404 : 16|14@1- (1,0) [-8192|8191] "" GTW
 SG_ VCSEATP_a405_tosDeltaCM m405 : 16|14@1- (1,0) [-8192|8191] "" GTW
 SG_ VCSEATP_a406_tosDeltaCalibEmpty m406 : 16|16@1- (1,0) [-32768|32767] "" GTW
 SG_ VCSEATP_a406_tosDeltaCalibCM m406 : 32|16@1- (1,0) [-32768|32767] "" GTW
 SG_ VCSEATP_a408_tosDeltaEmpty m408 : 16|16@1- (1,0) [-32768|32767] "" GTW
 SG_ VCSEATP_a408_tosDeltaOffset m408 : 32|12@1- (1,0) [-2048|2047] "" GTW
 SG_ VCSEATP_a409_tosDeltaCM m409 : 16|16@1- (1,0) [-32768|32767] "" GTW
 SG_ VCSEATP_a410_tosDeltaEmpty m410 : 16|16@1- (1,0) [-32768|32767] "" GTW
 SG_ VCSEATP_a410_tosDeltaOffset m410 : 32|12@1- (1,0) [-2048|2047] "" GTW
 SG_ VCSEATP_a412_tosDeltaEmpty m412 : 16|16@1- (1,0) [-32768|32767] "" GTW
 SG_ VCSEATP_a412_tosDeltaOffset m412 : 32|12@1- (1,0) [-2048|2047] "" GTW
 SG_ VCSEATP_a413_sbrVoltage m413 : 16|10@1+ (0.01,0) [0|10.23] "V" GTW
 SG_ VCSEATP_a415_occupancyTimeMins m415 : 16|16@1+ (1,0) [0|65535] "" GTW
 SG_ VCSEATP_a444_channel m444 : 16|8@1+ (1,0) [0|255] "" GTW
 SG_ VCSEATP_a444_watchdog m444 : 24|1@1+ (1,0) [0|1] "" GTW
 SG_ VCSEATP_a444_gateDriver m444 : 25|1@1+ (1,0) [0|1] "" GTW
 SG_ VCSEATP_a444_overcurrent m444 : 26|1@1+ (1,0) [0|1] "" GTW
 SG_ VCSEATP_a444_supplyUndervoltage m444 : 27|1@1+ (1,0) [0|1] "" GTW
 SG_ VCSEATP_a444_cpUndervoltage m444 : 28|1@1+ (1,0) [0|1] "" GTW
 SG_ VCSEATP_a444_overTempShutdown m444 : 29|1@1+ (1,0) [0|1] "" GTW
 SG_ VCSEATP_a444_overTempWarning m444 : 30|1@1+ (1,0) [0|1] "" GTW
 SG_ VCSEATP_a444_highSide2GateDriver m444 : 31|1@1+ (1,0) [0|1] "" GTW
 SG_ VCSEATP_a444_lowSide2GateDriver m444 : 32|1@1+ (1,0) [0|1] "" GTW
 SG_ VCSEATP_a444_highSide1GateDriver m444 : 33|1@1+ (1,0) [0|1] "" GTW
 SG_ VCSEATP_a444_lowSide1GateDriver m444 : 34|1@1+ (1,0) [0|1] "" GTW
 SG_ VCSEATP_a444_highSide2OverCurent m444 : 35|1@1+ (1,0) [0|1] "" GTW
 SG_ VCSEATP_a444_lowSide2OverCurent m444 : 36|1@1+ (1,0) [0|1] "" GTW
 SG_ VCSEATP_a444_highSide1OverCurent m444 : 37|1@1+ (1,0) [0|1] "" GTW
 SG_ VCSEATP_a444_lowSide1OverCurent m444 : 38|1@1+ (1,0) [0|1] "" GTW
 SG_ VCSEATP_a444_spiInit m444 : 39|1@1+ (1,0) [0|1] "" GTW
 SG_ VCSEATP_a444_spiPeriodicCheck m444 : 40|1@1+ (1,0) [0|1] "" GTW
 SG_ VCSEATP_a444_spiFault m444 : 41|1@1+ (1,0) [0|1] "" GTW
 SG_ VCSEATP_a444_voltageMonitor m444 : 42|1@1+ (1,0) [0|1] "" GTW
 SG_ VCSEATP_a444_enableLow m444 : 43|1@1+ (1,0) [0|1] "" GTW
 SG_ VCSEATP_a445_checksFailedCount m445 : 16|2@1+ (1,0) [0|3] "" GTW
 SG_ VCSEATP_a445_SPIFaultCount m445 : 18|2@1+ (1,0) [0|3] "" GTW
 SG_ VCSEATP_a445_expectedMSB m445 : 24|8@1+ (1,0) [0|255] "" GTW
 SG_ VCSEATP_a445_expectedLSB m445 : 32|8@1+ (1,0) [0|255] "" GTW
 SG_ VCSEATP_a445_actualMSB m445 : 40|8@1+ (1,0) [0|255] "" GTW
 SG_ VCSEATP_a445_actualLSB m445 : 48|8@1+ (1,0) [0|255] "" GTW

BO_ 999 VCSEATP_alertMatrix: 8 VCSEATP
 SG_ VCSEATP_matrixIndex M : 0|4@1+ (1,0) [0|15] "" GTW
 SG_ VCSEATP_a001_WatchdogReset m0 : 4|1@1+ (1,0) [0|1] "" GTW
 SG_ VCSEATP_a002_PowerLossReset m0 : 5|1@1+ (1,0) [0|1] "" GTW
 SG_ VCSEATP_a003_SWAssertion m0 : 6|1@1+ (1,0) [0|1] "" GTW
 SG_ VCSEATP_a005_CANTXError m0 : 8|1@1+ (1,0) [0|1] "" GTW
 SG_ VCSEATP_a010_ExtSupplyVoltError m0 : 13|1@1+ (1,0) [0|1] "" GTW
 SG_ VCSEATP_a012_CPUReset m0 : 15|1@1+ (1,0) [0|1] "" GTW
 SG_ VCSEATP_a013_AlertManagerFault m0 : 16|1@1+ (1,0) [0|1] "" GTW
 SG_ VCSEATP_a015_NVMMAlert m0 : 18|1@1+ (1,0) [0|1] "" GTW
 SG_ VCSEATP_a021_TaskSchedulerError m0 : 24|1@1+ (1,0) [0|1] "" GTW
 SG_ VCSEATP_a022_TaskInitError m0 : 25|1@1+ (1,0) [0|1] "" GTW
 SG_ VCSEATP_a030_ECULogUploadRequest m0 : 33|1@1+ (1,0) [0|1] "" GTW
 SG_ VCSEATP_a031_UDSActive m0 : 34|1@1+ (1,0) [0|1] "" GTW
 SG_ VCSEATP_a041_HighCPULoad m0 : 44|1@1+ (1,0) [0|1] "" GTW
 SG_ VCSEATP_a042_HighStackUsage m0 : 45|1@1+ (1,0) [0|1] "" GTW
 SG_ VCSEATP_a043_Task1msError m0 : 46|1@1+ (1,0) [0|1] "" GTW
 SG_ VCSEATP_a044_Task10msError m0 : 47|1@1+ (1,0) [0|1] "" GTW
 SG_ VCSEATP_a045_Task100msError m0 : 48|1@1+ (1,0) [0|1] "" GTW
 SG_ VCSEATP_a046_Task1000msError m0 : 49|1@1+ (1,0) [0|1] "" GTW
 SG_ VCSEATP_a058_inputRHighSyncDebug m0 : 61|1@1+ (1,0) [0|1] "" GTW
 SG_ VCSEATP_a059_inputResistanceHigh m0 : 62|1@1+ (1,0) [0|1] "" GTW
 SG_ VCSEATP_a060_engineeringBuild m0 : 63|1@1+ (1,0) [0|1] "" GTW
 SG_ VCSEATP_a061_XCPConnected m1 : 4|1@1+ (1,0) [0|1] "" GTW
 SG_ VCSEATP_a062_XCPWasConnected m1 : 5|1@1+ (1,0) [0|1] "" GTW
 SG_ VCSEATP_a063_SwitchFault m1 : 6|1@1+ (1,0) [0|1] "" GTW
 SG_ VCSEATP_a064_busSleepReqTimeout m1 : 7|1@1+ (1,0) [0|1] "" GTW
 SG_ VCSEATP_a200_motorPhantomEncoder m3 : 23|1@1+ (1,0) [0|1] "" GTW
 SG_ VCSEATP_a201_motorDutyEncDisabl m3 : 24|1@1+ (1,0) [0|1] "" GTW
 SG_ VCSEATP_a218_motorDriverFault m3 : 41|1@1+ (1,0) [0|1] "" GTW
 SG_ VCSEATP_a219_motorCurrentDropout m3 : 42|1@1+ (1,0) [0|1] "" GTW
 SG_ VCSEATP_a220_seatCurrStallTrack m3 : 43|1@1+ (1,0) [0|1] "" GTW
 SG_ VCSEATP_a221_seatCurrStallBack m3 : 44|1@1+ (1,0) [0|1] "" GTW
 SG_ VCSEATP_a222_seatCurrStallTilt m3 : 45|1@1+ (1,0) [0|1] "" GTW
 SG_ VCSEATP_a223_seatCurrStallLift m3 : 46|1@1+ (1,0) [0|1] "" GTW
 SG_ VCSEATP_a224_seatEncStallTrack m3 : 47|1@1+ (1,0) [0|1] "" GTW
 SG_ VCSEATP_a225_seatEncStallBack m3 : 48|1@1+ (1,0) [0|1] "" GTW
 SG_ VCSEATP_a226_seatEncStallTilt m3 : 49|1@1+ (1,0) [0|1] "" GTW
 SG_ VCSEATP_a227_seatEncStallLift m3 : 50|1@1+ (1,0) [0|1] "" GTW
 SG_ VCSEATP_a228_seatEncOverTrack m3 : 51|1@1+ (1,0) [0|1] "" GTW
 SG_ VCSEATP_a229_seatEncOverBack m3 : 52|1@1+ (1,0) [0|1] "" GTW
 SG_ VCSEATP_a230_seatEncOverTilt m3 : 53|1@1+ (1,0) [0|1] "" GTW
 SG_ VCSEATP_a231_seatEncOverLift m3 : 54|1@1+ (1,0) [0|1] "" GTW
 SG_ VCSEATP_a232_seatCurrUnderTrack m3 : 55|1@1+ (1,0) [0|1] "" GTW
 SG_ VCSEATP_a233_seatCurrUnderBack m3 : 56|1@1+ (1,0) [0|1] "" GTW
 SG_ VCSEATP_a234_seatCurrUnderTilt m3 : 57|1@1+ (1,0) [0|1] "" GTW
 SG_ VCSEATP_a235_seatCurrUnderLift m3 : 58|1@1+ (1,0) [0|1] "" GTW
 SG_ VCSEATP_a236_lumbarOverPresA m3 : 59|1@1+ (1,0) [0|1] "" GTW
 SG_ VCSEATP_a237_lumbarOverPresB m3 : 60|1@1+ (1,0) [0|1] "" GTW
 SG_ VCSEATP_a238_lumbarValveMIA m3 : 61|1@1+ (1,0) [0|1] "" GTW
 SG_ VCSEATP_a239_seatHeatIFront m3 : 62|1@1+ (1,0) [0|1] "" GTW
 SG_ VCSEATP_a240_seatHeatShortFront m3 : 63|1@1+ (1,0) [0|1] "" GTW
 SG_ VCSEATP_a241_seatHeatMIAFront m4 : 4|1@1+ (1,0) [0|1] "" GTW
 SG_ VCSEATP_a242_seatHeatTmpFront m4 : 5|1@1+ (1,0) [0|1] "" GTW
 SG_ VCSEATP_a251_seatUncalTrack m4 : 14|1@1+ (1,0) [0|1] "" GTW
 SG_ VCSEATP_a252_seatUncalBack m4 : 15|1@1+ (1,0) [0|1] "" GTW
 SG_ VCSEATP_a253_seatUncalTilt m4 : 16|1@1+ (1,0) [0|1] "" GTW
 SG_ VCSEATP_a254_seatUncalLift m4 : 17|1@1+ (1,0) [0|1] "" GTW
 SG_ VCSEATP_a263_seatTrackStallDebug m4 : 26|1@1+ (1,0) [0|1] "" GTW
 SG_ VCSEATP_a264_seatBackStallDebug m4 : 27|1@1+ (1,0) [0|1] "" GTW
 SG_ VCSEATP_a265_seatTiltStallDebug m4 : 28|1@1+ (1,0) [0|1] "" GTW
 SG_ VCSEATP_a266_seatLiftStallDebug m4 : 29|1@1+ (1,0) [0|1] "" GTW
 SG_ VCSEATP_a267_seatTrackHCEncStl m4 : 30|1@1+ (1,0) [0|1] "" GTW
 SG_ VCSEATP_a268_seatBackHCEncStlDbg m4 : 31|1@1+ (1,0) [0|1] "" GTW
 SG_ VCSEATP_a269_seatTiltHCEncStlDbg m4 : 32|1@1+ (1,0) [0|1] "" GTW
 SG_ VCSEATP_a270_seatLiftHCEncStlDbg m4 : 33|1@1+ (1,0) [0|1] "" GTW
 SG_ VCSEATP_a290_occupancyFaultFront m4 : 53|1@1+ (1,0) [0|1] "" GTW
 SG_ VCSEATP_a291_buckleFaultedFront m4 : 54|1@1+ (1,0) [0|1] "" GTW
 SG_ VCSEATP_a380_ocsCushionHigh m6 : 23|1@1+ (1,0) [0|1] "" GTW
 SG_ VCSEATP_a381_ocsCushionLow m6 : 24|1@1+ (1,0) [0|1] "" GTW
 SG_ VCSEATP_a382_ocsCushionShort m6 : 25|1@1+ (1,0) [0|1] "" GTW
 SG_ VCSEATP_a386_ocsSpareHigh m6 : 29|1@1+ (1,0) [0|1] "" GTW
 SG_ VCSEATP_a387_ocsSpareLow m6 : 30|1@1+ (1,0) [0|1] "" GTW
 SG_ VCSEATP_a388_ocsSpareShort m6 : 31|1@1+ (1,0) [0|1] "" GTW
 SG_ VCSEATP_a389_ocsTHInvalid m6 : 32|1@1+ (1,0) [0|1] "" GTW
 SG_ VCSEATP_a390_ocsCushionNoCalib m6 : 33|1@1+ (1,0) [0|1] "" GTW
 SG_ VCSEATP_a392_ocsSpareNoCalib m6 : 35|1@1+ (1,0) [0|1] "" GTW
 SG_ VCSEATP_a393_ocsTHNoCalib m6 : 36|1@1+ (1,0) [0|1] "" GTW
 SG_ VCSEATP_a394_ocsCushionInvlCalib m6 : 37|1@1+ (1,0) [0|1] "" GTW
 SG_ VCSEATP_a396_ocsSpareInvalCalib m6 : 39|1@1+ (1,0) [0|1] "" GTW
 SG_ VCSEATP_a397_ocsTHInvalCalib m6 : 40|1@1+ (1,0) [0|1] "" GTW
 SG_ VCSEATP_a398_ocsTOSMIA m6 : 41|1@1+ (1,0) [0|1] "" GTW
 SG_ VCSEATP_a399_ocsTHMIA m6 : 42|1@1+ (1,0) [0|1] "" GTW
 SG_ VCSEATP_a400_ocsCushionMismatch m6 : 43|1@1+ (1,0) [0|1] "" GTW
 SG_ VCSEATP_a401_ocsDiagContext m6 : 44|1@1+ (1,0) [0|1] "" GTW
 SG_ VCSEATP_a402_ocsSensorLow m6 : 45|1@1+ (1,0) [0|1] "" GTW
 SG_ VCSEATP_a403_ocsSensorHigh m6 : 46|1@1+ (1,0) [0|1] "" GTW
 SG_ VCSEATP_a404_ocsBackDisconnect m6 : 47|1@1+ (1,0) [0|1] "" GTW
 SG_ VCSEATP_a405_ocsSensorDisconnect m6 : 48|1@1+ (1,0) [0|1] "" GTW
 SG_ VCSEATP_a406_ocsCalibMismatch m6 : 49|1@1+ (1,0) [0|1] "" GTW
 SG_ VCSEATP_a407_ocsManufactureInvld m6 : 50|1@1+ (1,0) [0|1] "" GTW
 SG_ VCSEATP_a408_ocsSensorDroop m6 : 51|1@1+ (1,0) [0|1] "" GTW
 SG_ VCSEATP_a409_ocsHeatPadNoConnect m6 : 52|1@1+ (1,0) [0|1] "" GTW
 SG_ VCSEATP_a410_ocsSlowDrift m6 : 53|1@1+ (1,0) [0|1] "" GTW
 SG_ VCSEATP_a411_ocsDataTimeout m6 : 54|1@1+ (1,0) [0|1] "" GTW
 SG_ VCSEATP_a412_ocsRebaselineDBG m6 : 55|1@1+ (1,0) [0|1] "" GTW
 SG_ VCSEATP_a413_ocsSBRFaulted m6 : 56|1@1+ (1,0) [0|1] "" GTW
 SG_ VCSEATP_a414_ocsMissedIngressDBG m6 : 57|1@1+ (1,0) [0|1] "" GTW
 SG_ VCSEATP_a415_ocsRebaseEgressDBG m6 : 58|1@1+ (1,0) [0|1] "" GTW
 SG_ VCSEATP_a444_drv8703Fault m7 : 27|1@1+ (1,0) [0|1] "" GTW
 SG_ VCSEATP_a445_drv8703SpiFaultDBG m7 : 28|1@1+ (1,0) [0|1] "" GTW

BO_ 1287 VCSEATP_bootID: 8 VCSEATP
 SG_ VCSEATP_bootComponentId : 7|16@0+ (1,0) [0|65535] "" Vector__XXX
 SG_ VCSEATP_bootPcbaId : 23|8@0+ (1,0) [0|255] "" Vector__XXX
 SG_ VCSEATP_bootAssemblyId : 31|8@0+ (1,0) [0|255] "" Vector__XXX
 SG_ VCSEATP_bootUsageId : 39|16@0+ (1,0) [0|65535] "" Vector__XXX
 SG_ VCSEATP_bootFirmwareType : 63|8@0+ (1,0) [0|255] "" Vector__XXX

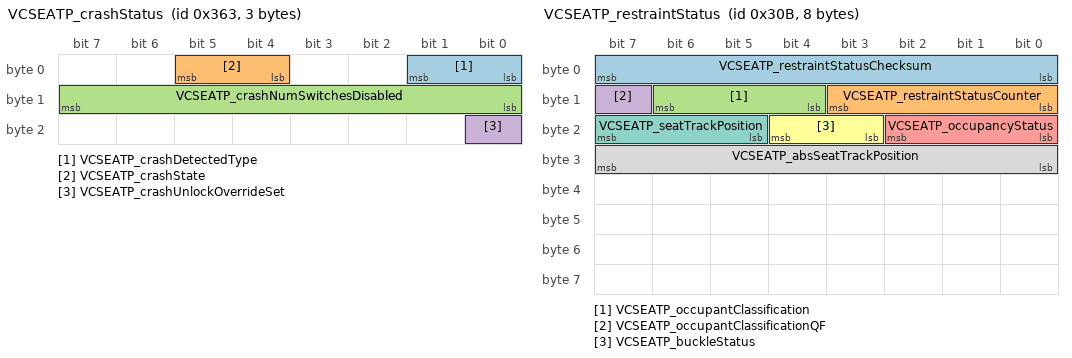
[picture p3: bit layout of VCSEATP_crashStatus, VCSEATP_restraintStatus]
BO_ 867 VCSEATP_crashStatus: 3 VCSEATP
 SG_ VCSEATP_crashDetectedType : 0|2@1+ (1,0) [0|3] "" GTW
 SG_ VCSEATP_crashState : 4|2@1+ (1,0) [0|3] "" GTW
 SG_ VCSEATP_crashNumSwitchesDisabled : 8|8@1+ (1,0) [0|255] "" GTW
 SG_ VCSEATP_crashUnlockOverrideSet : 16|1@1+ (1,0) [0|1] "" GTW

BO_ 773 VCSEATP_info: 8 VCSEATP
 SG_ VCSEATP_infoIndex M : 0|8@1+ (1,0) [0|255] "" GTW
 SG_ VCSEATP_infoBuildType m10 : 8|8@1+ (1,0) [0|4] "" GTW
 SG_ VCSEATP_infoBuildConfigId m10 : 16|16@1+ (1,0) [0|65535] "" GTW
 SG_ VCSEATP_infoHardwareId m10 : 32|16@1+ (1,0) [0|65535] "" Vector__XXX
 SG_ VCSEATP_infoComponentId m10 : 48|16@1+ (1,0) [0|65535] "" Vector__XXX
 SG_ VCSEATP_infoPcbaId m11 : 8|8@1+ (1,0) [0|255] "" Vector__XXX
 SG_ VCSEATP_infoAssemblyId m11 : 16|8@1+ (1,0) [0|255] "" Vector__XXX
 SG_ VCSEATP_infoUsageId m11 : 24|16@1+ (1,0) [0|65535] "" Vector__XXX
 SG_ VCSEATP_infoSubUsageId m11 : 40|16@1+ (1,0) [0|65535] "" Vector__XXX
 SG_ VCSEATP_infoAppCrc m13 : 32|32@1+ (1,0) [0|4294967295] "" GTW
 SG_ VCSEATP_infoSubcomponent1 m16 : 32|32@1+ (1,0) [0|4294967295] "" Vector__XXX
 SG_ VCSEATP_infoAppGitHash m17 : 8|56@1+ (1,0) [0|7.20575940379279E+16] "" Vector__XXX
 SG_ VCSEATP_infoBootGitHash m18 : 8|56@1+ (1,0) [0|7.20575940379279E+16] "" Vector__XXX
 SG_ VCSEATP_infoPlatformType m19 : 8|8@1+ (1,0) [0|255] "" GTW
 SG_ VCSEATP_infoBootUdsProtoVersion m20 : 8|16@1+ (1,0) [0|65535] "" Vector__XXX
 SG_ VCSEATP_infoBootCrc m20 : 24|32@1+ (1,0) [0|4294967295] "" Vector__XXX
 SG_ VCSEATP_infoSubcomponent2 m23 : 32|32@1+ (1,0) [0|4294967295] "" Vector__XXX
 SG_ VCSEATP_infoSubcomponent3 m24 : 32|32@1+ (1,0) [0|4294967295] "" Vector__XXX
 SG_ VCSEATP_infoSubcomponent4 m31 : 32|32@1+ (1,0) [0|4294967295] "" Vector__XXX
 SG_ VCSEATP_infoSubcomponent5 m32 : 32|32@1+ (1,0) [0|4294967295] "" Vector__XXX
 SG_ VCSEATP_infoSubcomponent6 m33 : 32|32@1+ (1,0) [0|4294967295] "" Vector__XXX

BO_ 1842 VCSEATP_ocsSensorStatus: 8 VCSEATP
 SG_ VCSEATP_ocsSensorStatusIndex M : 0|4@1+ (1,0) [0|6] "" Vector__XXX
 SG_ VCSEATP_tosRawCushion m0 : 8|16@1+ (1,0) [0|65535] "" GTW
 SG_ VCSEATP_tosRawSeatback m0 : 24|16@1+ (1,0) [0|65535] "" Vector__XXX
 SG_ VCSEATP_tosRawSpare m0 : 40|16@1+ (1,0) [0|65535] "" GTW
 SG_ VCSEATP_tosCountCushion m0 : 56|4@1+ (1,0) [0|15] "" Vector__XXX
 SG_ VCSEATP_tosCountSpare m0 : 60|4@1+ (1,0) [0|15] "" Vector__XXX
 SG_ VCSEATP_ocsTemperature m1 : 8|16@1+ (0.002670328832,-45) [-45|130] "degC" GTW
 SG_ VCSEATP_ocsHumidity m1 : 24|16@1+ (0.00152590219,0) [0|100] "%" GTW
 SG_ VCSEATP_tosFilteredCushion m2 : 4|16@1+ (1,0) [0|65535] "" GTW
 SG_ VCSEATP_tosFilteredSpare m2 : 20|16@1+ (1,0) [0|65535] "" GTW
 SG_ VCSEATP_tosDeltaDisconnected m2 : 50|14@1- (1,0) [-8192|8191] "" GTW
 SG_ VCSEATP_tosDeltaOffset m3 : 4|14@1- (1,0) [-8192|8191] "" GTW
 SG_ VCSEATP_tosDeltaEmpty m3 : 18|14@1- (1,0) [-8192|8191] "" GTW
 SG_ VCSEATP_tosRelative m3 : 32|14@1- (1,0) [-8192|8191] "" GTW
 SG_ VCSEATP_tosDeltaStable m3 : 46|1@1+ (1,0) [0|1] "" Vector__XXX
 SG_ VCSEATP_classificationLocked m3 : 47|1@1+ (1,0) [0|1] "" GTW
 SG_ VCSEATP_classificationRaw m3 : 48|3@1+ (1,0) [0|7] "" GTW
 SG_ VCSEATP_sandwichRawA1 m4 : 4|12@1- (1,0) [-2048|2047] "" Vector__XXX
 SG_ VCSEATP_sandwichRawA2_F m4 : 16|12@1- (1,0) [-2048|2047] "" Vector__XXX
 SG_ VCSEATP_sandwichRawA2_B m4 : 28|12@1- (1,0) [-2048|2047] "" Vector__XXX
 SG_ VCSEATP_sandwichRawB1 m4 : 40|12@1- (1,0) [-2048|2047] "" Vector__XXX
 SG_ VCSEATP_sandwichRawB2_F m4 : 52|12@1- (1,0) [-2048|2047] "" Vector__XXX
 SG_ VCSEATP_sandwichRawB2_B m5 : 4|12@1- (1,0) [-2048|2047] "" Vector__XXX
 SG_ VCSEATP_sandwichRawC2_F m5 : 16|12@1- (1,0) [-2048|2047] "" Vector__XXX
 SG_ VCSEATP_sandwichRawC2_B m5 : 28|12@1- (1,0) [-2048|2047] "" Vector__XXX

BO_ 1844 VCSEATP_ocsSensorStatus2: 8 VCSEATP
 SG_ VCSEATP_ocsSensorStatus2Index M : 0|4@1+ (1,0) [0|3] "" Vector__XXX
 SG_ VCSEATP_ocsCalibCushionEmpty m0 : 4|16@1+ (1,0) [0|65535] "" GTW
 SG_ VCSEATP_ocsCalibSpareEmpty m0 : 20|16@1+ (1,0) [0|65535] "" GTW
 SG_ VCSEATP_ocsCalibTempEmpty m0 : 36|16@1+ (0.002670328832,-45) [-45|130] "degC" GTW
 SG_ VCSEATP_ocsFieldCalibrated m0 : 52|1@1+ (1,0) [0|1] "" GTW
 SG_ VCSEATP_ocsCalibHumidityEmpty m1 : 4|16@1+ (0.00152590219,0) [0|100] "%" GTW
 SG_ VCSEATP_ocsCalibCushionDisc m1 : 20|16@1+ (1,0) [0|65535] "" GTW
 SG_ VCSEATP_ocsCalibSpareDisc m1 : 36|16@1+ (1,0) [0|65535] "" GTW
 SG_ VCSEATP_ocsCalibTempDisc m2 : 4|16@1+ (0.002670328832,-45) [-45|130] "degC" GTW
 SG_ VCSEATP_ocsCalibHumidityDisc m2 : 20|16@1+ (0.00152590219,0) [0|100] "%" GTW

BO_ 1861 VCSEATP_recallStatus: 1 VCSEATP
 SG_ VCSEATP_systemRecallStatus : 0|2@1+ (1,0) [0|3] "" GTW
 SG_ VCSEATP_seatRecallStatus : 2|2@1+ (1,0) [0|3] "" GTW

BO_ 779 VCSEATP_restraintStatus: 8 VCSEATP
 SG_ VCSEATP_restraintStatusChecksum : 0|8@1+ (1,0) [0|255] "" Vector__XXX
 SG_ VCSEATP_restraintStatusCounter : 8|4@1+ (1,0) [0|15] "" Vector__XXX
 SG_ VCSEATP_occupantClassification : 12|3@1+ (1,0) [0|7] "" GTW
 SG_ VCSEATP_occupantClassificationQF : 15|1@1+ (1,0) [0|1] "" GTW
 SG_ VCSEATP_occupancyStatus : 16|3@1+ (1,0) [0|7] "" APP,GTW
 SG_ VCSEATP_buckleStatus : 19|2@1+ (1,0) [0|3] "" APP,GTW
 SG_ VCSEATP_seatTrackPosition : 21|3@1+ (1,0) [0|7] "" GTW
 SG_ VCSEATP_absSeatTrackPosition : 24|8@1+ (1,0) [0|254] "%" GTW

BO_ 1251 VCSEATP_seatStatus: 8 VCSEATP
 SG_ VCSEATP_seatStatusIndex M : 0|3@1+ (1,0) [0|5] "" GTW
 SG_ VCSEATP_frontSeatTrackPos m0 : 8|16@1- (1,0) [-32768|32767] "" GTW
 SG_ VCSEATP_frontSeatTrackCurrent m0 : 24|12@1- (0.01,0) [-20.48|20.47] "A" GTW
 SG_ VCSEATP_frontSeatTrackDuty m0 : 36|12@1- (0.1,0) [-204.8|204.7] "%" GTW
 SG_ VCSEATP_frontSeatTrackState m0 : 48|3@1+ (1,0) [0|5] "" GTW
 SG_ VCSEATP_frontSeatTrackCalibrated m0 : 51|1@1+ (1,0) [0|1] "" GTW
 SG_ VCSEATP_frontSeatTrackLog m0 : 52|1@1+ (1,0) [0|1] "" GTW
 SG_ VCSEATP_frontSeatBackPos m1 : 8|16@1- (1,0) [-32768|32767] "" GTW
 SG_ VCSEATP_frontSeatBackCurrent m1 : 24|12@1- (0.01,0) [-20.48|20.47] "A" GTW
 SG_ VCSEATP_frontSeatBackDuty m1 : 36|12@1- (0.1,0) [-204.8|204.7] "%" GTW
 SG_ VCSEATP_frontSeatBackState m1 : 48|3@1+ (1,0) [0|5] "" GTW
 SG_ VCSEATP_frontSeatBackCalibrated m1 : 51|1@1+ (1,0) [0|1] "" GTW
 SG_ VCSEATP_frontSeatBackLog m1 : 52|1@1+ (1,0) [0|1] "" GTW
 SG_ VCSEATP_frontSeatLiftPos m2 : 8|16@1- (1,0) [-32768|32767] "" GTW
 SG_ VCSEATP_frontSeatLiftCurrent m2 : 24|12@1- (0.01,0) [-20.48|20.47] "A" GTW
 SG_ VCSEATP_frontSeatLiftDuty m2 : 36|12@1- (0.1,0) [-204.8|204.7] "%" GTW
 SG_ VCSEATP_frontSeatLiftState m2 : 48|3@1+ (1,0) [0|5] "" GTW
 SG_ VCSEATP_frontSeatLiftCalibrated m2 : 51|1@1+ (1,0) [0|1] "" GTW
 SG_ VCSEATP_frontSeatLiftLog m2 : 52|1@1+ (1,0) [0|1] "" GTW
 SG_ VCSEATP_frontSeatTiltPos m3 : 8|16@1- (1,0) [-32768|32767] "" GTW
 SG_ VCSEATP_frontSeatTiltCurrent m3 : 24|12@1- (0.01,0) [-20.48|20.47] "A" GTW
 SG_ VCSEATP_frontSeatTiltDuty m3 : 36|12@1- (0.1,0) [-204.8|204.7] "%" GTW
 SG_ VCSEATP_frontSeatTiltState m3 : 48|3@1+ (1,0) [0|5] "" GTW
 SG_ VCSEATP_frontSeatTiltCalibrated m3 : 51|1@1+ (1,0) [0|1] "" GTW
 SG_ VCSEATP_frontSeatTiltLog m3 : 52|1@1+ (1,0) [0|1] "" GTW
 SG_ VCSEATP_lumbarAState m4 : 3|3@1+ (1,0) [0|5] "" GTW
 SG_ VCSEATP_lumbarBState m4 : 8|3@1+ (1,0) [0|5] "" GTW
 SG_ VCSEATP_lumbarAPressureHpa m4 : 16|16@1+ (1,0) [0|65535] "" GTW
 SG_ VCSEATP_lumbarBPressureHpa m4 : 32|16@1+ (1,0) [0|65535] "" GTW
 SG_ VCSEATP_lumbarActiveTooLongErr m4 : 48|1@1+ (1,0) [0|1] "" GTW
 SG_ VCSEATP_lumbarMaxPErr m4 : 49|1@1+ (1,0) [0|1] "" GTW
 SG_ VCSEATP_lumbarOvercurrentErr m4 : 50|1@1+ (1,0) [0|1] "" GTW
 SG_ VCSEATP_lumbarMaxOperatingPErr m4 : 51|1@1+ (1,0) [0|1] "" GTW
 SG_ VCSEATP_lumbarMinPErr m4 : 52|1@1+ (1,0) [0|1] "" GTW
 SG_ VCSEATP_lumbarGeneralErr m4 : 53|1@1+ (1,0) [0|1] "" GTW
 SG_ VCSEATP_lumbarDevMaxPumpPressA m4 : 54|1@1+ (1,0) [0|1] "" GTW
 SG_ VCSEATP_lumbarDevMaxPumpPressB m4 : 55|1@1+ (1,0) [0|1] "" GTW
 SG_ VCSEATP_frontSeatTrackPosReal m5 : 3|12@1- (1,0) [-2048|2047] "mm" GTW
 SG_ VCSEATP_frontSeatBackPosReal m5 : 16|12@1- (0.1,0) [-204.8|204.7] "deg" GTW
 SG_ VCSEATP_frontSeatLiftPosReal m5 : 28|12@1- (1,0) [-2048|2047] "mm" GTW
 SG_ VCSEATP_frontSeatTiltPosReal m5 : 40|12@1- (0.1,0) [-204.8|204.7] "deg" GTW

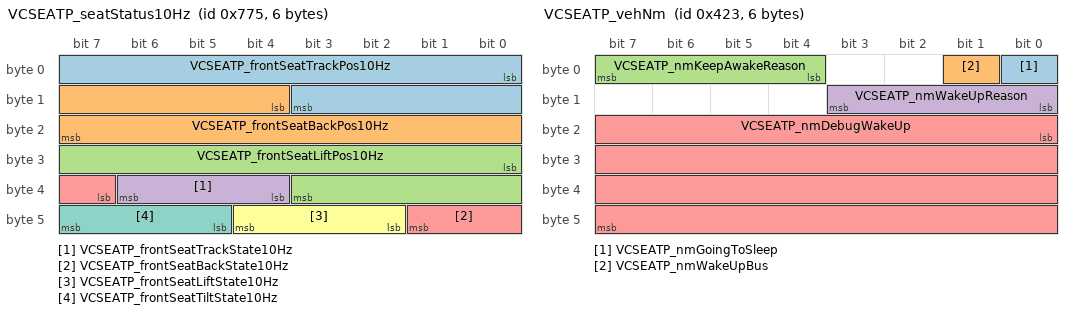
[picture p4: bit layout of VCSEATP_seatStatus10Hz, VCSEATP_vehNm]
BO_ 1909 VCSEATP_seatStatus10Hz: 6 VCSEATP
 SG_ VCSEATP_frontSeatTrackPos10Hz : 0|12@1- (1,0) [-2048|2047] "" GTW
 SG_ VCSEATP_frontSeatBackPos10Hz : 12|12@1- (1,0) [-2048|2047] "" GTW
 SG_ VCSEATP_frontSeatLiftPos10Hz : 24|12@1- (1,0) [-2048|2047] "" GTW
 SG_ VCSEATP_frontSeatTrackState10Hz : 36|3@1+ (1,0) [0|5] "" GTW
 SG_ VCSEATP_frontSeatBackState10Hz : 39|3@1+ (1,0) [0|5] "" GTW
 SG_ VCSEATP_frontSeatLiftState10Hz : 42|3@1+ (1,0) [0|5] "" GTW
 SG_ VCSEATP_frontSeatTiltState10Hz : 45|3@1+ (1,0) [0|5] "" GTW

BO_ 740 VCSEATP_seatStatus2: 6 VCSEATP
 SG_ VCSEATP_seatStatus2Index M : 0|2@1+ (1,0) [0|3] "" Vector__XXX
 SG_ VCSEATP_frontSeatHeatCurrent m0 : 4|12@1+ (0.01,0) [0|40.95] "A" GTW
 SG_ VCSEATP_frontSeatHeatDuty m0 : 16|8@1+ (1,0) [0|255] "%" GTW
 SG_ VCSEATP_frontSeatHeatTmp m0 : 24|12@1- (0.05,0) [-40|80] "degC" GTW
 SG_ VCSEATP_frontSeatHeatTmpTarget m0 : 36|8@1- (0.5,0) [0|60] "degC" GTW
 SG_ VCSEATP_frontSeatHeatInhibited m0 : 44|1@1+ (1,0) [0|1] "" GTW
 SG_ VCSEATP_frontSeatHeatPowered m0 : 45|1@1+ (1,0) [0|1] "" Vector__XXX
 SG_ VCSEATP_frontSeatHeatTmpVoltage m1 : 4|10@1+ (0.01,0) [0|10.23] "V" Vector__XXX
 SG_ VCSEATP_frontOccupancyVoltage m2 : 4|10@1+ (0.01,0) [0|10.23] "V" GTW
 SG_ VCSEATP_frontBuckleVoltage m2 : 14|10@1+ (0.01,0) [0|10.23] "V" GTW
 SG_ VCSEATP_seatTrackPositionVoltage m2 : 24|10@1+ (0.01,0) [0|10.23] "V" Vector__XXX

BO_ 932 VCSEATP_status: 6 VCSEATP
 SG_ VCSEATP_statusIndex M : 0|1@1+ (1,0) [0|1] "" Vector__XXX
 SG_ VCSEATP_loadShedPriority m0 : 1|8@1+ (1,0) [0|255] "" Vector__XXX
 SG_ VCSEATP_vehiclePowerStateDBG m0 : 9|2@1+ (1,0) [0|3] "" GTW
 SG_ VCSEATP_OTAState m0 : 12|1@1+ (1,0) [0|1] "" GTW
 SG_ VCSEATP_5AVoltage m0 : 13|10@1+ (0.005443676098,0) [0|5.568880648254] "V" GTW
 SG_ VCSEATP_vbatProt m0 : 23|12@1+ (0.005443676098,0) [0|22.29185362131] "V" GTW
 SG_ VCSEATP_pcbaTemperature m0 : 35|11@1+ (0.125,-40) [-40|150] "degC" GTW

BO_ 965 VCSEATP_switchStatus: 7 VCSEATP
 SG_ VCSEATP_switchStatusIndex M : 0|2@1+ (1,0) [0|2] "" GTW
 SG_ VCSEATP_frontSeatTrackBack m0 : 8|2@1+ (1,0) [0|3] "" GTW
 SG_ VCSEATP_frontSeatTrackForward m0 : 10|2@1+ (1,0) [0|3] "" GTW
 SG_ VCSEATP_frontSeatTiltDown m0 : 12|2@1+ (1,0) [0|3] "" GTW
 SG_ VCSEATP_frontSeatTiltUp m0 : 14|2@1+ (1,0) [0|3] "" GTW
 SG_ VCSEATP_frontSeatLiftDown m0 : 16|2@1+ (1,0) [0|3] "" GTW
 SG_ VCSEATP_frontSeatLiftUp m0 : 18|2@1+ (1,0) [0|3] "" GTW
 SG_ VCSEATP_frontSeatBackrestBack m0 : 20|2@1+ (1,0) [0|3] "" GTW
 SG_ VCSEATP_frontSeatBackrestForward m0 : 22|2@1+ (1,0) [0|3] "" GTW
 SG_ VCSEATP_frontSeatLumbarDown m0 : 24|2@1+ (1,0) [0|3] "" GTW
 SG_ VCSEATP_frontSeatLumbarUp m0 : 26|2@1+ (1,0) [0|3] "" GTW
 SG_ VCSEATP_frontSeatLumbarIn m0 : 28|2@1+ (1,0) [0|3] "" GTW
 SG_ VCSEATP_frontSeatLumbarOut m0 : 30|2@1+ (1,0) [0|3] "" GTW
 SG_ VCSEATP_frontBuckleSwitch m0 : 48|2@1+ (1,0) [0|3] "" GTW
 SG_ VCSEATP_frontOccupancySwitch m0 : 50|2@1+ (1,0) [0|3] "" GTW

BO_ 1763 VCSEATP_udsResponse: 8 VCSEATP
 SG_ VCSEATP_udsResponseData_H : 7|32@0+ (1,0) [0|4294967295] "" GTW,GTWU
 SG_ VCSEATP_udsResponseData_L : 39|32@0+ (1,0) [0|4294967295] "" GTW,GTWU

BO_ 1059 VCSEATP_vehNm: 6 VCSEATP
 SG_ VCSEATP_nmGoingToSleep : 0|1@1+ (1,0) [0|1] "" Vector__XXX
 SG_ VCSEATP_nmWakeUpBus : 1|1@1+ (1,0) [0|1] "" Vector__XXX
 SG_ VCSEATP_nmKeepAwakeReason : 4|4@1+ (1,0) [0|15] "" GTW
 SG_ VCSEATP_nmWakeUpReason : 8|4@1+ (1,0) [0|15] "" GTW
 SG_ VCSEATP_nmDebugWakeUp : 16|32@1+ (1,0) [0|4294967295] "" GTW

BO_ 1891 VCSEATP_xcpResponse: 8 VCSEATP
 SG_ VCSEATP_xcpResponseData : 0|64@1+ (1,0) [0|1.84467440737096E+19] "" Vector__XXX

BO_ 1816 VIN: 8 GTW
 SG_ CH_GTW_vinDataBytesIndex : 7|8@0+ (1,0) [0|0] "" APP,TAS2
 SG_ CH_GTW_vinPartData : 15|56@0+ (1,0) [0|0] "" TAS2

BO_ 1029 VIP_405HS: 8 GTW
 SG_ EPASParamMux M : 7|8@0+ (1,0) [0|255] "" DAS,SDM,PARK,ESP,RCM,APS
 SG_ EPASGlobalTime m1 : 23|32@0+ (0.1,0) [0|429496729.5] "" Vector__XXX
 SG_ EPASSignalConfigID m1 : 55|16@0+ (1,0) [0|65535] "" Vector__XXX
 SG_ EPASInCarTemp m2 : 23|8@0+ (1,-40) [-40|215] "" Vector__XXX
 SG_ EPASOutdoorTemp m2 : 31|8@0+ (1,-40) [-40|215] "" Vector__XXX
 SG_ EPASMainECUVoltage m2 : 39|8@0+ (0.25,0) [0|63.75] "" Vector__XXX
 SG_ EPASTotalDistance m2 : 47|24@0+ (1,0) [0|16777215] "" Vector__XXX
 SG_ EPASVin_h m16 : 47|24@0+ (1,0) [0|16777215] "" RADAR,SDM,PARK,ESP,RCM,APS,APP
 SG_ EPASVin_m m17 : 15|56@0+ (1,0) [0|7.2057594038E+16] "" RADAR,SDM,PARK,ESP,RCM,APS,APP
 SG_ EPASVin_l m18 : 15|56@0+ (1,0) [0|7.2057594038E+16] "" RADAR,SDM,PARK,ESP,RCM,APS,APP

BO_ 1835 XCP_tasRequest: 8 DBG
 SG_ XCP_tasRequest : 7|64@0+ (1,0) [0|1.84467440737096E+19] "" TAS

BO_ 1878 XCP_vcseatdRequest: 8 DBG
 SG_ XCP_vcseatdRequestData : 7|64@0+ (1,0) [0|1.84467440737096E+19] "" VCSEATD

BO_ 1879 XCP_vcseatpRequest: 8 DBG
 SG_ XCP_vcseatpRequestData : 7|64@0+ (1,0) [0|1.84467440737096E+19] "" VCSEATP

CM_ BO_ 1860 "lets UI know when to cease sending the recall signal";
CM_ BO_ 780 "Restraint status message, sent to RCM";
CM_ BO_ 1890 "XCP protocol response message";
CM_ BO_ 579 "Power State of systems controlled by VCSEATD";
CM_ BO_ 999 "VCSEATP alert matrix";
CM_ BO_ 1861 "lets UI know when to cease sending the recall signal";
CM_ BO_ 779 "Restraint status message, sent to RCM";
CM_ BO_ 1891 "XCP protocol response message";
CM_ BO_ 1835 "XCP protocol request message";
CM_ BO_ 1878 "XCP protocol request message";
CM_ BO_ 1879 "XCP protocol request message";
CM_ SG_ 780 VCSEATD_restraintStatusChecksum "Restraint statu message checksum";
CM_ SG_ 780 VCSEATD_restraintStatusCounter "Restraint statu message counter";
CM_ SG_ 780 VCSEATD_occupantClassification "Occupant classification determined by a combination of sensors";
CM_ SG_ 780 VCSEATD_occupantClassificationQF "Occupant Classification quality factor";
CM_ SG_ 780 VCSEATD_occupancyStatus "Fused occupancy status of the seat";
CM_ SG_ 780 VCSEATD_buckleStatus "Seat belt buckle status of the seat";
CM_ SG_ 780 VCSEATD_seatTrackPosition "Binary seat track position sensor, denoting seat foreward or back";
CM_ SG_ 780 VCSEATD_absSeatTrackPosition "Absolute seat track position sensor, in percentage of range of motion";
CM_ SG_ 738 VCSEATD_frontSeatHeatTmpVoltage "Raw voltage of seat heater thermistor";
CM_ SG_ 738 VCSEATD_seatTrackPositionVoltage "Raw voltage of seat track position sensor";
CM_ SG_ 1890 VCSEATD_xcpResponseData "VCSEAT Xcp protocol response data";
CM_ SG_ 1374 VCSEATP_alertID "Numeric ID that identifies the alert.";
CM_ SG_ 1374 VCSEATP_alertType "VCSEATP alert state (set or cleared)";
CM_ SG_ 1374 VCSEATP_a000_alertDataW0 "Generic word access to alert data W0.";
CM_ SG_ 1374 VCSEATP_a000_alertDataW1 "Generic word access to alert data W1.";
CM_ SG_ 1374 VCSEATP_a000_alertDataW2 "Generic word access to alert data W2.";
CM_ SG_ 1374 VCSEATP_a030_logId "Log Identifier";
CM_ SG_ 1374 VCSEATP_a242_snsShortCircuit "Indicates that front seat heater temp sensor has a short circuit";
CM_ SG_ 1374 VCSEATP_a242_snsDisconnect "Indicates that front seat heater temp sensor is disconnected";
CM_ SG_ 1374 VCSEATP_a242_snsRateChangeUp "Indicates that front seat heater temp sensor rising rate of change was too high";
CM_ SG_ 1374 VCSEATP_a242_snsRateChangeDown "Indicates that front seat heater temp sensor falling rate of change was too high";
CM_ SG_ 999 VCSEATP_matrixIndex "Alert Matrix multiplexer index";
CM_ SG_ 999 VCSEATP_a001_WatchdogReset "Warns if the processor has experienced a reset due to watchdog reset.";
CM_ SG_ 999 VCSEATP_a002_PowerLossReset "Warns if the processor has experienced a reset due to power loss.";
CM_ SG_ 999 VCSEATP_a003_SWAssertion "An internal software assertion has failed.";
CM_ SG_ 999 VCSEATP_a005_CANTXError "An error has been detected with CAN transmission. Used by engineering to debug.";
CM_ SG_ 999 VCSEATP_a010_ExtSupplyVoltError "The external 12V supply voltage from the vehicle is out of range.";
CM_ SG_ 999 VCSEATP_a012_CPUReset "CPU detected a reset.";
CM_ SG_ 999 VCSEATP_a013_AlertManagerFault "Alert Manager encountered an internal processing error.";
CM_ SG_ 999 VCSEATP_a015_NVMMAlert "An issue is indicated from the non-volatile memory manager.";
CM_ SG_ 999 VCSEATP_a021_TaskSchedulerError "If a task was not able to run at the appropriate time.";
CM_ SG_ 999 VCSEATP_a022_TaskInitError "If a task failed to initialize.";
CM_ SG_ 999 VCSEATP_a030_ECULogUploadRequest "Triggers on board diagnostics service to upload log buffer.";
CM_ SG_ 999 VCSEATP_a031_UDSActive "A unified diagnostics services (UDS) request was made";
CM_ SG_ 999 VCSEATP_a041_HighCPULoad "CPU under heavy load.";
CM_ SG_ 999 VCSEATP_a042_HighStackUsage "High stack memory usage was detected";
CM_ SG_ 999 VCSEATP_a043_Task1msError "Debug information for 1ms task errors.";
CM_ SG_ 999 VCSEATP_a044_Task10msError "Debug information for 10ms task errors";
CM_ SG_ 999 VCSEATP_a045_Task100msError "Debug information for 100ms task errors.";
CM_ SG_ 999 VCSEATP_a046_Task1000msError "Debug information for 1000ms task errors.";
CM_ SG_ 999 VCSEATP_a058_inputRHighSyncDebug "Voltage drop on input power is high";
CM_ SG_ 999 VCSEATP_a059_inputResistanceHigh "Voltage drop on input power is high";
CM_ SG_ 999 VCSEATP_a060_engineeringBuild "The firmware on this car is for engineering use only";
CM_ SG_ 999 VCSEATP_a061_XCPConnected "Indicates an active connection to the universal measurement and calibration protocol state machine";
CM_ SG_ 999 VCSEATP_a062_XCPWasConnected "Indicates there was an active connection to the universal measurement and calibration protocol state machine";
CM_ SG_ 999 VCSEATP_a063_SwitchFault "An issue with a switch has been detected.";
CM_ SG_ 999 VCSEATP_a064_busSleepReqTimeout "Indicates if a bus has timed out of a sleep request from the network manager";
CM_ SG_ 999 VCSEATP_a200_motorPhantomEncoder "Motor encoders are moving without motor being driven";
CM_ SG_ 999 VCSEATP_a201_motorDutyEncDisabl "Motor is being driven, but encoders are locked";
CM_ SG_ 999 VCSEATP_a218_motorDriverFault "DRV8702 bridge driver has pulled its nFault pin low";
CM_ SG_ 999 VCSEATP_a219_motorCurrentDropout "Some motor current readings are unreliable";
CM_ SG_ 999 VCSEATP_a220_seatCurrStallTrack "The motor has unexpectedly stalled";
CM_ SG_ 999 VCSEATP_a221_seatCurrStallBack "The motor has unexpectedly stalled";
CM_ SG_ 999 VCSEATP_a222_seatCurrStallTilt "The motor has unexpectedly stalled";
CM_ SG_ 999 VCSEATP_a223_seatCurrStallLift "The motor has unexpectedly stalled";
CM_ SG_ 999 VCSEATP_a224_seatEncStallTrack "The motor isn't providing encoder feedback";
CM_ SG_ 999 VCSEATP_a225_seatEncStallBack "The motor isn't providing encoder feedback";
CM_ SG_ 999 VCSEATP_a226_seatEncStallTilt "The motor isn't providing encoder feedback";
CM_ SG_ 999 VCSEATP_a227_seatEncStallLift "The motor isn't providing encoder feedback";
CM_ SG_ 999 VCSEATP_a228_seatEncOverTrack "The motor has traveled beyond the expected range";
CM_ SG_ 999 VCSEATP_a229_seatEncOverBack "The motor has traveled beyond the expected range";
CM_ SG_ 999 VCSEATP_a230_seatEncOverTilt "The motor has traveled beyond the expected range";
CM_ SG_ 999 VCSEATP_a231_seatEncOverLift "The motor has traveled beyond the expected range";
CM_ SG_ 999 VCSEATP_a232_seatCurrUnderTrack "The motor isn't responding";
CM_ SG_ 999 VCSEATP_a233_seatCurrUnderBack "The motor isn't responding";
CM_ SG_ 999 VCSEATP_a234_seatCurrUnderTilt "The motor isn't responding";
CM_ SG_ 999 VCSEATP_a235_seatCurrUnderLift "The motor isn't responding";
CM_ SG_ 999 VCSEATP_a236_lumbarOverPresA "The bladder A has exceeded pressure limits";
CM_ SG_ 999 VCSEATP_a237_lumbarOverPresB "The bladder B has exceeded pressure limits";
CM_ SG_ 999 VCSEATP_a238_lumbarValveMIA "The valveblock isn't inflating or deflating when commanded";
CM_ SG_ 999 VCSEATP_a239_seatHeatIFront "The seat heater has had unusually high current draw";
CM_ SG_ 999 VCSEATP_a240_seatHeatShortFront "HSD for seat heater has shorted";
CM_ SG_ 999 VCSEATP_a241_seatHeatMIAFront "seat heater isn't drawing any current";
CM_ SG_ 999 VCSEATP_a242_seatHeatTmpFront "The front seat heater temperature sensor has an electrical fault. This sensor is used for fault management of the airbag system";
CM_ SG_ 999 VCSEATP_a251_seatUncalTrack "The track motor is uncalibrated";
CM_ SG_ 999 VCSEATP_a252_seatUncalBack "The backrest motor is uncalibrated";
CM_ SG_ 999 VCSEATP_a253_seatUncalTilt "The tilt motor is uncalibrated";
CM_ SG_ 999 VCSEATP_a254_seatUncalLift "The lift motor is uncalibrated";
CM_ SG_ 999 VCSEATP_a263_seatTrackStallDebug "The track motor has unexpectedly stalled";
CM_ SG_ 999 VCSEATP_a264_seatBackStallDebug "The backrest motor has unexpectedly stalled";
CM_ SG_ 999 VCSEATP_a265_seatTiltStallDebug "The tilt motor has unexpectedly stalled";
CM_ SG_ 999 VCSEATP_a266_seatLiftStallDebug "The lift motor has unexpectedly stalled";
CM_ SG_ 999 VCSEATP_a267_seatTrackHCEncStl "The track motor encoder has unexpectedly stalled";
CM_ SG_ 999 VCSEATP_a268_seatBackHCEncStlDbg "The backrest motor encoder has unexpectedly stalled";
CM_ SG_ 999 VCSEATP_a269_seatTiltHCEncStlDbg "The tilt motor encoder has unexpectedly stalled";
CM_ SG_ 999 VCSEATP_a270_seatLiftHCEncStlDbg "The lift motor encoder has unexpectedly stalled";
CM_ SG_ 999 VCSEATP_a290_occupancyFaultFront "The front seat occupancy sensor is faulted";
CM_ SG_ 999 VCSEATP_a291_buckleFaultedFront "The front seat buckle sensor is faulted";
CM_ SG_ 999 VCSEATP_a380_ocsCushionHigh "The Cushion occupancy sensor reads a high value";
CM_ SG_ 999 VCSEATP_a381_ocsCushionLow "The Cushion occupancy sensor reads a low value";
CM_ SG_ 999 VCSEATP_a382_ocsCushionShort "The Cushion occupancy sensor reads as shorted to ground";
CM_ SG_ 999 VCSEATP_a386_ocsSpareHigh "The Spare occupancy sensor reads a high value";
CM_ SG_ 999 VCSEATP_a387_ocsSpareLow "The Spare occupancy sensor reads a low value";
CM_ SG_ 999 VCSEATP_a388_ocsSpareShort "The Spare occupancy sensor reads as shorted to ground";
CM_ SG_ 999 VCSEATP_a389_ocsTHInvalid "The Temp Humidity occupancy sensor reads invalid value";
CM_ SG_ 999 VCSEATP_a390_ocsCushionNoCalib "The Cushion occupancy sensor calibration is missing";
CM_ SG_ 999 VCSEATP_a392_ocsSpareNoCalib "The Spare occupancy sensor calibration is missing";
CM_ SG_ 999 VCSEATP_a393_ocsTHNoCalib "The Temp Humidity occupancy sensor calibration is missing";
CM_ SG_ 999 VCSEATP_a394_ocsCushionInvlCalib "The Cushion occupancy sensor calibration is present, but invalid";
CM_ SG_ 999 VCSEATP_a396_ocsSpareInvalCalib "The Spare occupancy sensor calibration is present, but invalid";
CM_ SG_ 999 VCSEATP_a397_ocsTHInvalCalib "The Temp Humidity occupancy sensor calibration is present, but invalid";
CM_ SG_ 999 VCSEATP_a398_ocsTOSMIA "The TOS communication failed";
CM_ SG_ 999 VCSEATP_a399_ocsTHMIA "The Temp Humidity occupancy sensor communication failed";
CM_ SG_ 999 VCSEATP_a400_ocsCushionMismatch "The Cushion occupancy sensor reading does not match other occupancy sensors";
CM_ SG_ 999 VCSEATP_a401_ocsDiagContext "Alert that provides metadata context to other alerts. Does not mean anything on its own.";
CM_ SG_ 999 VCSEATP_a402_ocsSensorLow "OCS Sensor reading is lower than expected";
CM_ SG_ 999 VCSEATP_a403_ocsSensorHigh "OCS Sensor reading is higher than expected";
CM_ SG_ 999 VCSEATP_a404_ocsBackDisconnect "OCS Seatback is likely disconnected";
CM_ SG_ 999 VCSEATP_a405_ocsSensorDisconnect "OCS both seatback and cushion likely disconnected";
CM_ SG_ 999 VCSEATP_a406_ocsCalibMismatch "OCS empty seat calibration is mismatched with calibration programmed at board manufacturing";
CM_ SG_ 999 VCSEATP_a407_ocsManufactureInvld "OCS has been incorrectly calibrated by the manufacturer";
CM_ SG_ 999 VCSEATP_a408_ocsSensorDroop "OCS Sensor reading is lower than expected";
CM_ SG_ 999 VCSEATP_a409_ocsHeatPadNoConnect "OCS cushion or heat pad has been disconnected";
CM_ SG_ 999 VCSEATP_a410_ocsSlowDrift "OCS capacitance reading has drifted over 24 hourly(not necessarily consecutive) samples. This is a silent alert";
CM_ SG_ 999 VCSEATP_a411_ocsDataTimeout "TOS sensor data not received on startup";
CM_ SG_ 999 VCSEATP_a412_ocsRebaselineDBG "OCS baseline was reset to zero out seat. Debug only";
CM_ SG_ 999 VCSEATP_a413_ocsSBRFaulted "The seat occupancy switch is faulted";
CM_ SG_ 999 VCSEATP_a414_ocsMissedIngressDBG "On wakeup, OCS missed an occupant ingress. Occupant switch was pressed on startup. Debug only";
CM_ SG_ 999 VCSEATP_a415_ocsRebaseEgressDBG "On egress, OCS decided to rebaseline after missing ingress. Debug only";
CM_ SG_ 999 VCSEATP_a444_drv8703Fault "DRV8703 bridge driver faulted";
CM_ SG_ 999 VCSEATP_a445_drv8703SpiFaultDBG "DRV8703 bridge driver SPI data is unexpected";
CM_ SG_ 773 VCSEATP_infoBuildConfigId "SW-243974";
CM_ SG_ 1842 VCSEATP_classificationRaw "Occupant classification, ignoring classification lock";
CM_ SG_ 1844 VCSEATP_ocsFieldCalibrated "The currently stored OCS calibration did not come from 901 Page, instead it was calibrated afterwards, by UDS routine";
CM_ SG_ 779 VCSEATP_restraintStatusChecksum "Restraint statu message checksum";
CM_ SG_ 779 VCSEATP_restraintStatusCounter "Restraint statu message counter";
CM_ SG_ 779 VCSEATP_occupantClassification "Occupant classification determined by a combination of sensors";
CM_ SG_ 779 VCSEATP_occupantClassificationQF "Occupant Classification quality factor";
CM_ SG_ 779 VCSEATP_occupancyStatus "Fused occupancy status of the seat";
CM_ SG_ 779 VCSEATP_buckleStatus "Seat belt buckle status of the seat";
CM_ SG_ 779 VCSEATP_seatTrackPosition "Binary seat track position sensor, denoting seat foreward or back";
CM_ SG_ 779 VCSEATP_absSeatTrackPosition "Absolute seat track position sensor, in percentage of range of motion";
CM_ SG_ 740 VCSEATP_frontSeatHeatTmpVoltage "Raw voltage of seat heater thermistor";
CM_ SG_ 740 VCSEATP_seatTrackPositionVoltage "Raw voltage of seat track position sensor";
CM_ SG_ 1891 VCSEATP_xcpResponseData "VCSEAT Xcp protocol response data";
CM_ SG_ 1816 CH_GTW_vinDataBytesIndex "VIN message part";
CM_ SG_ 1816 CH_GTW_vinPartData "VIN digits (8 bit ascii encoded)";
CM_ SG_ 1029 EPASSignalConfigID "Tells EPAS it has the correct CANDB";
CM_ SG_ 1029 EPASVin_h "Last 3-bytes of vehicles VIN.";
CM_ SG_ 1029 EPASVin_m "Middle 7-bytes of vehicle VIN.";
CM_ SG_ 1029 EPASVin_l "First 7-bytes of vehicle VIN";
BA_DEF_ BO_ "AlertLogSubSystemId" INT 0 0;
BA_DEF_ BO_ "AlertType" INT 0 4;
BA_DEF_ BO_ "AppBotschaft" ENUM "nein","ja";
BA_DEF_ BO_ "DiagRequest" ENUM "No","Yes";
BA_DEF_ BO_ "DiagResponse" ENUM "No","Yes";
BA_DEF_ BO_ "ETHGatewayMessageSendType" ENUM "UseGenMsgSendType","onWrite","noAutoCode";
BA_DEF_ BO_ "ETHId" STRING ;
BA_DEF_ BO_ "GatewayHandlerEnum" ENUM "noHandler","uds","alertLog","messageLogOnReception","udsClient";
BA_DEF_ BO_ "GatewayMessageAtomic" ENUM "No","Yes";
BA_DEF_ BO_ "GatewayMessageSendType" ENUM "UseGenMsgSendType","onWrite","noAutoCode";
BA_DEF_ BO_ "GenMsgCycleTime" INT 0 0;
BA_DEF_ BO_ "GenMsgCycleTimeFast" INT 0 0;
BA_DEF_ BO_ "GenMsgDelayTime" INT 0 0;
BA_DEF_ BO_ "GenMsgForceMiaCheck" ENUM "No","Yes";
BA_DEF_ BO_ "GenMsgGatewayNotification" STRING ;
BA_DEF_ BO_ "GenMsgILSupport" ENUM "No","Yes";
BA_DEF_ BO_ "GenMsgSaltingFunction" ENUM "No","Yes";
BA_DEF_ BO_ "GenMsgSendType" ENUM "Cyclic","NotUsed","NotUsed","NotUsed","NotUsed","NotUsed","NotUsed","IfActive","NoMsgSendType","Sporadic";
BA_DEF_ BO_ "GenMsgStartValue" STRING ;
BA_DEF_ BO_ "GenMsgTimeOut" INT 0 0;
BA_DEF_ BO_ "MessageIdType" ENUM "normal","udsRequest","udsResponse","udsReserved","udsFunctionalRequest","networkManagement","bootloader","xcp","dtc","diagnostic","vendorExempt";
BA_DEF_ BO_ "NWMBotschaft" ENUM "nein","ja";
BA_DEF_ BO_ "NmMessage" ENUM "No","Yes";
BA_DEF_ BO_ "SubSystemId" INT 0 256;
BA_DEF_ BO_ "UsesChecksum" ENUM "No","Yes";
BA_DEF_ SG_ "FieldType" STRING ;
BA_DEF_ SG_ "FlexKomComment" STRING ;
BA_DEF_ SG_ "FlexKomIsMotorola" ENUM "nein","ja";
BA_DEF_ SG_ "FlexKomSID" INT 0 2147483647;
BA_DEF_ SG_ "FlexKomSigLaenge" INT 0 64;
BA_DEF_ SG_ "FlexKomSigName" STRING ;
BA_DEF_ SG_ "FlexKomSigStartPos" INT 0 63;
BA_DEF_ SG_ "FlexKomSigStartValue" STRING ;
BA_DEF_ SG_ "Gatewaysignal" INT 0 1;
BA_DEF_ SG_ "GenSigCycleTime" INT 0 0;
BA_DEF_ SG_ "GenSigCycleTimeActive" INT 0 0;
BA_DEF_ SG_ "GenSigPersistent" ENUM "No","Yes";
BA_DEF_ SG_ "GenSigSNA" STRING ;
BA_DEF_ SG_ "GenSigSendType" ENUM "Cyclic","OnWrite","OnWriteWithRepetition","OnChange","OnChangeWithRepetition","IfActive","IfActiveWithRepetition","NoSigSendType","NotUsed","NotUsed","NotUsed","NotUsed","NotUsed";
BA_DEF_ SG_ "GenSigStartValue" INT 0 0;
BA_DEF_ SG_ "GenSigTimeout_CGW" INT 0 65535;
BA_DEF_ SG_ "GenSigTimeout_DRVU" INT 0 65535;
BA_DEF_ SG_ "GenSigTimeout_ECM" INT 0 65535;
BA_DEF_ SG_ "GenSigTimeout_EIS" INT 0 65535;
BA_DEF_ SG_ "GenSigTimeout_EPS" INT 0 65535;
BA_DEF_ SG_ "GenSigTimeout_ESP_ABR" INT 0 65535;
BA_DEF_ SG_ "GenSigTimeout_IC" INT 0 65535;
BA_DEF_ SG_ "GenSigTimeout_MPC" INT 0 65535;
BA_DEF_ SG_ "GenSigTimeout_NV" INT 0 65535;
BA_DEF_ SG_ "GenSigTimeout_ORC" INT 0 65535;
BA_DEF_ SG_ "GenSigTimeout_PTS" INT 0 65535;
BA_DEF_ SG_ "GenSigTimeout_RBTM_FL" INT 0 65535;
BA_DEF_ SG_ "GenSigTimeout_RBTM_FR" INT 0 65535;
BA_DEF_ SG_ "GenSigTimeout_RDU" INT 0 65535;
BA_DEF_ SG_ "GenSigTimeout_SCCM" INT 0 65535;
BA_DEF_ SG_ "GenSigTimeout_SPC" INT 0 65535;
BA_DEF_ SG_ "GenSigTimeout_TPM" INT 0 65535;
BA_DEF_ SG_ "LogSignal" STRING ;
BA_DEF_ SG_ "PektronUpdateBitType" ENUM "Not used","Has update bit","Is update bit";
BA_DEF_REL_ BU_SG_REL_ "GenSigTimeoutTime" INT 0 0;

BA_DEF_DEF_ "AlertLogSubSystemId" 0;
BA_DEF_DEF_ "AlertType" 4;
BA_DEF_DEF_ "AppBotschaft" "nein";
BA_DEF_DEF_ "DiagRequest" "No";
BA_DEF_DEF_ "DiagResponse" "No";
BA_DEF_DEF_ "ETHGatewayMessageSendType" "UseGenMsgSendType";
BA_DEF_DEF_ "ETHId" "";
BA_DEF_DEF_ "FieldType" "";
BA_DEF_DEF_ "FlexKomComment" "";
BA_DEF_DEF_ "FlexKomIsMotorola" "";
BA_DEF_DEF_ "FlexKomSID" 0;
BA_DEF_DEF_ "FlexKomSigLaenge" 0;
BA_DEF_DEF_ "FlexKomSigName" "";
BA_DEF_DEF_ "FlexKomSigStartPos" 0;
BA_DEF_DEF_ "FlexKomSigStartValue" "";
BA_DEF_DEF_ "GatewayHandlerEnum" "noHandler";
BA_DEF_DEF_ "GatewayMessageAtomic" "No";
BA_DEF_DEF_ "GatewayMessageSendType" "UseGenMsgSendType";
BA_DEF_DEF_ "Gatewaysignal" 0;
BA_DEF_DEF_ "GenMsgCycleTime" 0;
BA_DEF_DEF_ "GenMsgCycleTimeFast" 0;
BA_DEF_DEF_ "GenMsgDelayTime" 0;
BA_DEF_DEF_ "GenMsgForceMiaCheck" "No";
BA_DEF_DEF_ "GenMsgGatewayNotification" "";
BA_DEF_DEF_ "GenMsgILSupport" "Yes";
BA_DEF_DEF_ "GenMsgSaltingFunction" "No";
BA_DEF_DEF_ "GenMsgSendType" "Cyclic";
BA_DEF_DEF_ "GenMsgStartValue" "";
BA_DEF_DEF_ "GenMsgTimeOut" 0;
BA_DEF_DEF_ "GenSigCycleTime" 0;
BA_DEF_DEF_ "GenSigCycleTimeActive" 0;
BA_DEF_DEF_ "GenSigPersistent" "No";
BA_DEF_DEF_ "GenSigSNA" "";
BA_DEF_DEF_ "GenSigSendType" "Cyclic";
BA_DEF_DEF_ "GenSigStartValue" 0;
BA_DEF_DEF_ "GenSigTimeout_CGW" 0;
BA_DEF_DEF_ "GenSigTimeout_DRVU" 0;
BA_DEF_DEF_ "GenSigTimeout_ECM" 0;
BA_DEF_DEF_ "GenSigTimeout_EIS" 0;
BA_DEF_DEF_ "GenSigTimeout_EPS" 0;
BA_DEF_DEF_ "GenSigTimeout_ESP_ABR" 0;
BA_DEF_DEF_ "GenSigTimeout_IC" 0;
BA_DEF_DEF_ "GenSigTimeout_MPC" 0;
BA_DEF_DEF_ "GenSigTimeout_NV" 0;
BA_DEF_DEF_ "GenSigTimeout_ORC" 0;
BA_DEF_DEF_ "GenSigTimeout_PTS" 0;
BA_DEF_DEF_ "GenSigTimeout_RBTM_FL" 0;
BA_DEF_DEF_ "GenSigTimeout_RBTM_FR" 0;
BA_DEF_DEF_ "GenSigTimeout_RDU" 0;
BA_DEF_DEF_ "GenSigTimeout_SCCM" 0;
BA_DEF_DEF_ "GenSigTimeout_SPC" 0;
BA_DEF_DEF_ "GenSigTimeout_TPM" 0;
BA_DEF_DEF_ "LogSignal" "";
BA_DEF_DEF_ "MessageIdType" "normal";
BA_DEF_DEF_ "NWMBotschaft" "nein";
BA_DEF_DEF_ "NmMessage" "No";
BA_DEF_DEF_ "PektronUpdateBitType" "Not used";
BA_DEF_DEF_ "SubSystemId" 0;
BA_DEF_DEF_ "UsesChecksum" "No";
BA_DEF_DEF_REL_ "GenSigTimeoutTime" 0;
BA_ "GatewayMessageSendType" BO_ 1860 1;
BA_ "GenMsgCycleTime" BO_ 1860 1000;
BA_ "GenMsgCycleTime" BO_ 780 50;
BA_ "GatewayMessageSendType" BO_ 1250 1;
BA_ "GenMsgCycleTime" BO_ 1250 100;
BA_ "GenMsgCycleTime" BO_ 1908 100;
BA_ "GenMsgCycleTime" BO_ 738 200;
BA_ "GenMsgCycleTime" BO_ 931 50;
BA_ "GenMsgForceMiaCheck" BO_ 931 1;
BA_ "GatewayMessageSendType" BO_ 964 1;
BA_ "GenMsgCycleTime" BO_ 964 50;
BA_ "GatewayHandlerEnum" BO_ 1761 4;
BA_ "GenMsgSendType" BO_ 1761 7;
BA_ "GenMsgCycleTime" BO_ 1058 100;
BA_ "GenMsgCycleTime" BO_ 900 1000;
BA_ "GenMsgSendType" BO_ 1855 7;
BA_ "GenMsgCycleTime" BO_ 579 100;
BA_ "AlertLogSubSystemId" BO_ 1374 285;
BA_ "GatewayHandlerEnum" BO_ 1374 2;
BA_ "GatewayMessageSendType" BO_ 999 1;
BA_ "GenMsgCycleTime" BO_ 999 100;
BA_ "GenMsgCycleTime" BO_ 867 1000;
BA_ "GenMsgCycleTime" BO_ 773 1000;
BA_ "GenMsgCycleTime" BO_ 1842 40;
BA_ "GenMsgCycleTime" BO_ 1844 10000;
BA_ "GatewayMessageSendType" BO_ 1861 1;
BA_ "GenMsgCycleTime" BO_ 1861 1000;
BA_ "GenMsgCycleTime" BO_ 779 50;
BA_ "GatewayMessageSendType" BO_ 1251 1;
BA_ "GenMsgCycleTime" BO_ 1251 100;
BA_ "GenMsgCycleTime" BO_ 1909 100;
BA_ "GenMsgCycleTime" BO_ 740 200;
BA_ "GenMsgCycleTime" BO_ 932 50;
BA_ "GenMsgForceMiaCheck" BO_ 932 1;
BA_ "GatewayMessageSendType" BO_ 965 1;
BA_ "GenMsgCycleTime" BO_ 965 50;
BA_ "GatewayHandlerEnum" BO_ 1763 4;
BA_ "GenMsgSendType" BO_ 1763 7;
BA_ "GenMsgCycleTime" BO_ 1059 100;
BA_ "GenMsgCycleTime" BO_ 1816 60000;
BA_ "GenMsgSaltingFunction" BO_ 1816 1;
BA_ "GenMsgStartValue" BO_ 1816 "0300000000000000h";
BA_ "GenMsgCycleTime" BO_ 1029 250;
BA_ "GenMsgSaltingFunction" BO_ 1029 1;
BA_ "GenMsgSendType" BO_ 1835 7;
BA_ "GenMsgSendType" BO_ 1878 1;
BA_ "GenMsgSendType" BO_ 1879 1;
BA_ "FieldType" SG_ 1860 VCSEATD_systemRecallStatus "recallStatus";
BA_ "GenSigSNA" SG_ 1860 VCSEATD_systemRecallStatus "0";
BA_ "LogSignal" SG_ 1860 VCSEATD_systemRecallStatus "onChange";
BA_ "FieldType" SG_ 1860 VCSEATD_seatRecallStatus "recallStatus";
BA_ "GenSigSNA" SG_ 1860 VCSEATD_seatRecallStatus "0";
BA_ "LogSignal" SG_ 1860 VCSEATD_seatRecallStatus "onChange";
BA_ "FieldType" SG_ 780 VCSEATD_occupantClassification "SEAT_occupantClassification";
BA_ "GenSigSNA" SG_ 780 VCSEATD_occupantClassification "7";
BA_ "LogSignal" SG_ 780 VCSEATD_occupantClassification "onChange";
BA_ "FieldType" SG_ 780 VCSEATD_occupantClassificationQF "SEAT_occupantClassificationQF";
BA_ "LogSignal" SG_ 780 VCSEATD_occupantClassificationQF "onChange";
BA_ "FieldType" SG_ 780 VCSEATD_occupancyStatus "VCSEAT1_occupancyStatus";
BA_ "GenSigSNA" SG_ 780 VCSEATD_occupancyStatus "7";
BA_ "LogSignal" SG_ 780 VCSEATD_occupancyStatus "onChange";
BA_ "FieldType" SG_ 780 VCSEATD_buckleStatus "VCSEAT1_buckleStatus";
BA_ "GenSigSNA" SG_ 780 VCSEATD_buckleStatus "3";
BA_ "LogSignal" SG_ 780 VCSEATD_buckleStatus "onChange";
BA_ "FieldType" SG_ 780 VCSEATD_seatTrackPosition "SEAT_seatTrackPosition";
BA_ "GenSigSNA" SG_ 780 VCSEATD_seatTrackPosition "7";
BA_ "LogSignal" SG_ 780 VCSEATD_seatTrackPosition "periodic ONE_MINUTE Any";
BA_ "GenSigSNA" SG_ 780 VCSEATD_absSeatTrackPosition "255";
BA_ "GenSigStartValue" SG_ 780 VCSEATD_absSeatTrackPosition 255;
BA_ "LogSignal" SG_ 780 VCSEATD_absSeatTrackPosition "periodic ONE_MINUTE Any";
BA_ "FieldType" SG_ 1250 VCSEATD_seatStatusIndex "SEAT_seatStatusIndex";
BA_ "LogSignal" SG_ 1250 VCSEATD_frontSeatTrackPos "onChange";
BA_ "LogSignal" SG_ 1250 VCSEATD_frontSeatTrackCurrent "periodic ONE_DAY Any";
BA_ "LogSignal" SG_ 1250 VCSEATD_frontSeatTrackDuty "onChange";
BA_ "FieldType" SG_ 1250 VCSEATD_frontSeatTrackState "SEAT_seatState";
BA_ "LogSignal" SG_ 1250 VCSEATD_frontSeatTrackState "onChange";
BA_ "LogSignal" SG_ 1250 VCSEATD_frontSeatTrackCalibrated "periodic ONE_DAY Any";
BA_ "LogSignal" SG_ 1250 VCSEATD_frontSeatTrackLog "onChange";
BA_ "LogSignal" SG_ 1250 VCSEATD_frontSeatBackPos "onChange";
BA_ "LogSignal" SG_ 1250 VCSEATD_frontSeatBackCurrent "periodic ONE_DAY Any";
BA_ "LogSignal" SG_ 1250 VCSEATD_frontSeatBackDuty "onChange";
BA_ "FieldType" SG_ 1250 VCSEATD_frontSeatBackState "SEAT_seatState";
BA_ "LogSignal" SG_ 1250 VCSEATD_frontSeatBackState "onChange";
BA_ "LogSignal" SG_ 1250 VCSEATD_frontSeatBackCalibrated "periodic ONE_DAY Any";
BA_ "LogSignal" SG_ 1250 VCSEATD_frontSeatBackLog "onChange";
BA_ "LogSignal" SG_ 1250 VCSEATD_frontSeatLiftPos "onChange";
BA_ "LogSignal" SG_ 1250 VCSEATD_frontSeatLiftCurrent "periodic ONE_DAY Any";
BA_ "LogSignal" SG_ 1250 VCSEATD_frontSeatLiftDuty "onChange";
BA_ "FieldType" SG_ 1250 VCSEATD_frontSeatLiftState "SEAT_seatState";
BA_ "LogSignal" SG_ 1250 VCSEATD_frontSeatLiftState "onChange";
BA_ "LogSignal" SG_ 1250 VCSEATD_frontSeatLiftCalibrated "periodic ONE_DAY Any";
BA_ "LogSignal" SG_ 1250 VCSEATD_frontSeatLiftLog "onChange";
BA_ "LogSignal" SG_ 1250 VCSEATD_frontSeatTiltPos "onChange";
BA_ "LogSignal" SG_ 1250 VCSEATD_frontSeatTiltCurrent "periodic ONE_DAY Any";
BA_ "LogSignal" SG_ 1250 VCSEATD_frontSeatTiltDuty "onChange";
BA_ "FieldType" SG_ 1250 VCSEATD_frontSeatTiltState "SEAT_seatState";
BA_ "LogSignal" SG_ 1250 VCSEATD_frontSeatTiltState "onChange";
BA_ "LogSignal" SG_ 1250 VCSEATD_frontSeatTiltCalibrated "periodic ONE_DAY Any";
BA_ "LogSignal" SG_ 1250 VCSEATD_frontSeatTiltLog "onChange";
BA_ "FieldType" SG_ 1250 VCSEATD_lumbarAState "SEAT_seatState";
BA_ "LogSignal" SG_ 1250 VCSEATD_lumbarAState "onChange";
BA_ "FieldType" SG_ 1250 VCSEATD_lumbarBState "SEAT_seatState";
BA_ "LogSignal" SG_ 1250 VCSEATD_lumbarBState "onChange";
BA_ "LogSignal" SG_ 1250 VCSEATD_lumbarAPressureHpa "periodic TEN_SECONDS Any";
BA_ "LogSignal" SG_ 1250 VCSEATD_lumbarBPressureHpa "periodic TEN_SECONDS Any";
BA_ "LogSignal" SG_ 1250 VCSEATD_lumbarActiveTooLongErr "onChange";
BA_ "LogSignal" SG_ 1250 VCSEATD_lumbarMaxPErr "onChange";
BA_ "LogSignal" SG_ 1250 VCSEATD_lumbarOvercurrentErr "onChange";
BA_ "LogSignal" SG_ 1250 VCSEATD_lumbarMaxOperatingPErr "onChange";
BA_ "LogSignal" SG_ 1250 VCSEATD_lumbarMinPErr "onChange";
BA_ "LogSignal" SG_ 1250 VCSEATD_lumbarGeneralErr "onChange";
BA_ "LogSignal" SG_ 1250 VCSEATD_lumbarDevMaxPumpPressA "onChange";
BA_ "LogSignal" SG_ 1250 VCSEATD_lumbarDevMaxPumpPressB "onChange";
BA_ "LogSignal" SG_ 1250 VCSEATD_frontSeatTrackPosReal "onChange";
BA_ "LogSignal" SG_ 1250 VCSEATD_frontSeatBackPosReal "onChange";
BA_ "LogSignal" SG_ 1250 VCSEATD_frontSeatLiftPosReal "onChange";
BA_ "LogSignal" SG_ 1250 VCSEATD_frontSeatTiltPosReal "onChange";
BA_ "LogSignal" SG_ 1908 VCSEATD_frontSeatTrackPos10Hz "onChange";
BA_ "LogSignal" SG_ 1908 VCSEATD_frontSeatBackPos10Hz "onChange";
BA_ "LogSignal" SG_ 1908 VCSEATD_frontSeatLiftPos10Hz "onChange";
BA_ "FieldType" SG_ 1908 VCSEATD_frontSeatTrackState10Hz "SEAT_seatState";
BA_ "LogSignal" SG_ 1908 VCSEATD_frontSeatTrackState10Hz "onChange";
BA_ "FieldType" SG_ 1908 VCSEATD_frontSeatBackState10Hz "SEAT_seatState";
BA_ "LogSignal" SG_ 1908 VCSEATD_frontSeatBackState10Hz "onChange";
BA_ "FieldType" SG_ 1908 VCSEATD_frontSeatLiftState10Hz "SEAT_seatState";
BA_ "LogSignal" SG_ 1908 VCSEATD_frontSeatLiftState10Hz "onChange";
BA_ "FieldType" SG_ 1908 VCSEATD_frontSeatTiltState10Hz "SEAT_seatState";
BA_ "LogSignal" SG_ 1908 VCSEATD_frontSeatTiltState10Hz "onChange";
BA_ "FieldType" SG_ 738 VCSEATD_seatStatus2Index "VCSEAT1_seatStatus2Index";
BA_ "LogSignal" SG_ 738 VCSEATD_frontSeatHeatCurrent "periodic ONE_MINUTE Any";
BA_ "LogSignal" SG_ 738 VCSEATD_frontSeatHeatDuty "periodic ONE_MINUTE Any";
BA_ "LogSignal" SG_ 738 VCSEATD_frontSeatHeatTmp "periodic ONE_MINUTE Any";
BA_ "LogSignal" SG_ 738 VCSEATD_frontSeatHeatTmpTarget "periodic FIVE_MINUTES Any";
BA_ "LogSignal" SG_ 738 VCSEATD_frontSeatHeatInhibited "periodic FIVE_MINUTES Any";
BA_ "LogSignal" SG_ 738 VCSEATD_frontOccupancyVoltage "periodic ONE_MINUTE Any";
BA_ "LogSignal" SG_ 738 VCSEATD_frontBuckleVoltage "periodic ONE_MINUTE Any";
BA_ "FieldType" SG_ 931 VCSEATD_vehiclePowerStateDBG "vehiclePowerState";
BA_ "LogSignal" SG_ 931 VCSEATD_vehiclePowerStateDBG "onChange";
BA_ "LogSignal" SG_ 931 VCSEATD_OTAState "onChange";
BA_ "LogSignal" SG_ 931 VCSEATD_5AVoltage "periodic TEN_SECONDS Any";
BA_ "LogSignal" SG_ 931 VCSEATD_vbatProt "periodic TEN_SECONDS Any";
BA_ "LogSignal" SG_ 931 VCSEATD_pcbaTemperature "periodic FIVE_MINUTES Any";
BA_ "FieldType" SG_ 964 VCSEATD_switchStatusIndex "VCSEAT1_switchStatusIndex";
BA_ "FieldType" SG_ 964 VCSEATD_frontSeatTrackBack "switchStatus";
BA_ "GenSigSNA" SG_ 964 VCSEATD_frontSeatTrackBack "3";
BA_ "LogSignal" SG_ 964 VCSEATD_frontSeatTrackBack "onChange";
BA_ "FieldType" SG_ 964 VCSEATD_frontSeatTrackForward "switchStatus";
BA_ "GenSigSNA" SG_ 964 VCSEATD_frontSeatTrackForward "3";
BA_ "LogSignal" SG_ 964 VCSEATD_frontSeatTrackForward "onChange";
BA_ "FieldType" SG_ 964 VCSEATD_frontSeatTiltDown "switchStatus";
BA_ "GenSigSNA" SG_ 964 VCSEATD_frontSeatTiltDown "3";
BA_ "LogSignal" SG_ 964 VCSEATD_frontSeatTiltDown "onChange";
BA_ "FieldType" SG_ 964 VCSEATD_frontSeatTiltUp "switchStatus";
BA_ "GenSigSNA" SG_ 964 VCSEATD_frontSeatTiltUp "3";
BA_ "LogSignal" SG_ 964 VCSEATD_frontSeatTiltUp "onChange";
BA_ "FieldType" SG_ 964 VCSEATD_frontSeatLiftDown "switchStatus";
BA_ "GenSigSNA" SG_ 964 VCSEATD_frontSeatLiftDown "3";
BA_ "LogSignal" SG_ 964 VCSEATD_frontSeatLiftDown "onChange";
BA_ "FieldType" SG_ 964 VCSEATD_frontSeatLiftUp "switchStatus";
BA_ "GenSigSNA" SG_ 964 VCSEATD_frontSeatLiftUp "3";
BA_ "LogSignal" SG_ 964 VCSEATD_frontSeatLiftUp "onChange";
BA_ "FieldType" SG_ 964 VCSEATD_frontSeatBackrestBack "switchStatus";
BA_ "GenSigSNA" SG_ 964 VCSEATD_frontSeatBackrestBack "3";
BA_ "LogSignal" SG_ 964 VCSEATD_frontSeatBackrestBack "onChange";
BA_ "FieldType" SG_ 964 VCSEATD_frontSeatBackrestForward "switchStatus";
BA_ "GenSigSNA" SG_ 964 VCSEATD_frontSeatBackrestForward "3";
BA_ "LogSignal" SG_ 964 VCSEATD_frontSeatBackrestForward "onChange";
BA_ "FieldType" SG_ 964 VCSEATD_frontSeatLumbarDown "switchStatus";
BA_ "GenSigSNA" SG_ 964 VCSEATD_frontSeatLumbarDown "3";
BA_ "LogSignal" SG_ 964 VCSEATD_frontSeatLumbarDown "onChange";
BA_ "FieldType" SG_ 964 VCSEATD_frontSeatLumbarUp "switchStatus";
BA_ "GenSigSNA" SG_ 964 VCSEATD_frontSeatLumbarUp "3";
BA_ "LogSignal" SG_ 964 VCSEATD_frontSeatLumbarUp "onChange";
BA_ "FieldType" SG_ 964 VCSEATD_frontSeatLumbarIn "switchStatus";
BA_ "GenSigSNA" SG_ 964 VCSEATD_frontSeatLumbarIn "3";
BA_ "LogSignal" SG_ 964 VCSEATD_frontSeatLumbarIn "onChange";
BA_ "FieldType" SG_ 964 VCSEATD_frontSeatLumbarOut "switchStatus";
BA_ "GenSigSNA" SG_ 964 VCSEATD_frontSeatLumbarOut "3";
BA_ "LogSignal" SG_ 964 VCSEATD_frontSeatLumbarOut "onChange";
BA_ "FieldType" SG_ 964 VCSEATD_frontBuckleSwitch "switchStatus";
BA_ "GenSigSNA" SG_ 964 VCSEATD_frontBuckleSwitch "3";
BA_ "LogSignal" SG_ 964 VCSEATD_frontBuckleSwitch "onChange";
BA_ "FieldType" SG_ 964 VCSEATD_frontOccupancySwitch "switchStatus";
BA_ "GenSigSNA" SG_ 964 VCSEATD_frontOccupancySwitch "3";
BA_ "LogSignal" SG_ 964 VCSEATD_frontOccupancySwitch "onChange";
BA_ "GenSigSendType" SG_ 1761 VCSEATD_udsResponseData_H 1;
BA_ "GenSigSendType" SG_ 1761 VCSEATD_udsResponseData_L 1;
BA_ "FieldType" SG_ 1058 VCSEATD_nmKeepAwakeReason "VCSEAT1_nmKeepAwakeReason";
BA_ "GenSigSNA" SG_ 1058 VCSEATD_nmKeepAwakeReason "0";
BA_ "LogSignal" SG_ 1058 VCSEATD_nmKeepAwakeReason "onChange";
BA_ "FieldType" SG_ 1058 VCSEATD_nmWakeUpReason "VCSEAT1_nmWakeUpReason";
BA_ "LogSignal" SG_ 1058 VCSEATD_nmWakeUpReason "onChange";
BA_ "LogSignal" SG_ 1058 VCSEATD_nmDebugWakeUp "onChange";
BA_ "GenSigSNA" SG_ 900 VCSEATP_CPULoadTotal "255";
BA_ "GenSigSNA" SG_ 900 VCSEATP_CPULoad1msTask "255";
BA_ "GenSigSNA" SG_ 900 VCSEATP_CPULoad10msTask "255";
BA_ "GenSigSNA" SG_ 900 VCSEATP_CPULoad100msTask "255";
BA_ "GenSigSNA" SG_ 900 VCSEATP_CPULoad1000msTask "255";
BA_ "FieldType" SG_ 579 VCSEATP_lumbarLVState "LVPowerState";
BA_ "LogSignal" SG_ 579 VCSEATP_lumbarLVState "onChange";
BA_ "FieldType" SG_ 1374 VCSEATP_alertID "VCSEATP_alerts";
BA_ "FieldType" SG_ 1374 VCSEATP_alertType "alertState";
BA_ "FieldType" SG_ 1374 VCSEATP_a220_seatMotorState "SEAT_seatState";
BA_ "FieldType" SG_ 1374 VCSEATP_a220_seatSwitchBack "switchStatus";
BA_ "GenSigSNA" SG_ 1374 VCSEATP_a220_seatSwitchBack "3";
BA_ "FieldType" SG_ 1374 VCSEATP_a220_seatSwitchForward "switchStatus";
BA_ "GenSigSNA" SG_ 1374 VCSEATP_a220_seatSwitchForward "3";
BA_ "FieldType" SG_ 1374 VCSEATP_a221_seatMotorState "SEAT_seatState";
BA_ "FieldType" SG_ 1374 VCSEATP_a221_seatSwitchBack "switchStatus";
BA_ "GenSigSNA" SG_ 1374 VCSEATP_a221_seatSwitchBack "3";
BA_ "FieldType" SG_ 1374 VCSEATP_a221_seatSwitchForward "switchStatus";
BA_ "GenSigSNA" SG_ 1374 VCSEATP_a221_seatSwitchForward "3";
BA_ "FieldType" SG_ 1374 VCSEATP_a222_seatMotorState "SEAT_seatState";
BA_ "FieldType" SG_ 1374 VCSEATP_a222_seatSwitchBack "switchStatus";
BA_ "GenSigSNA" SG_ 1374 VCSEATP_a222_seatSwitchBack "3";
BA_ "FieldType" SG_ 1374 VCSEATP_a222_seatSwitchForward "switchStatus";
BA_ "GenSigSNA" SG_ 1374 VCSEATP_a222_seatSwitchForward "3";
BA_ "FieldType" SG_ 1374 VCSEATP_a223_seatMotorState "SEAT_seatState";
BA_ "FieldType" SG_ 1374 VCSEATP_a223_seatSwitchBack "switchStatus";
BA_ "GenSigSNA" SG_ 1374 VCSEATP_a223_seatSwitchBack "3";
BA_ "FieldType" SG_ 1374 VCSEATP_a223_seatSwitchForward "switchStatus";
BA_ "GenSigSNA" SG_ 1374 VCSEATP_a223_seatSwitchForward "3";
BA_ "FieldType" SG_ 1374 VCSEATP_a224_seatMotorState "SEAT_seatState";
BA_ "FieldType" SG_ 1374 VCSEATP_a224_seatSwitchBack "switchStatus";
BA_ "GenSigSNA" SG_ 1374 VCSEATP_a224_seatSwitchBack "3";
BA_ "FieldType" SG_ 1374 VCSEATP_a224_seatSwitchForward "switchStatus";
BA_ "GenSigSNA" SG_ 1374 VCSEATP_a224_seatSwitchForward "3";
BA_ "FieldType" SG_ 1374 VCSEATP_a225_seatMotorState "SEAT_seatState";
BA_ "FieldType" SG_ 1374 VCSEATP_a225_seatSwitchBack "switchStatus";
BA_ "GenSigSNA" SG_ 1374 VCSEATP_a225_seatSwitchBack "3";
BA_ "FieldType" SG_ 1374 VCSEATP_a225_seatSwitchForward "switchStatus";
BA_ "GenSigSNA" SG_ 1374 VCSEATP_a225_seatSwitchForward "3";
BA_ "FieldType" SG_ 1374 VCSEATP_a226_seatMotorState "SEAT_seatState";
BA_ "FieldType" SG_ 1374 VCSEATP_a226_seatSwitchBack "switchStatus";
BA_ "GenSigSNA" SG_ 1374 VCSEATP_a226_seatSwitchBack "3";
BA_ "FieldType" SG_ 1374 VCSEATP_a226_seatSwitchForward "switchStatus";
BA_ "GenSigSNA" SG_ 1374 VCSEATP_a226_seatSwitchForward "3";
BA_ "FieldType" SG_ 1374 VCSEATP_a227_seatMotorState "SEAT_seatState";
BA_ "FieldType" SG_ 1374 VCSEATP_a227_seatSwitchBack "switchStatus";
BA_ "GenSigSNA" SG_ 1374 VCSEATP_a227_seatSwitchBack "3";
BA_ "FieldType" SG_ 1374 VCSEATP_a227_seatSwitchForward "switchStatus";
BA_ "GenSigSNA" SG_ 1374 VCSEATP_a227_seatSwitchForward "3";
BA_ "FieldType" SG_ 1374 VCSEATP_a228_seatMotorState "SEAT_seatState";
BA_ "FieldType" SG_ 1374 VCSEATP_a228_seatSwitchBack "switchStatus";
BA_ "GenSigSNA" SG_ 1374 VCSEATP_a228_seatSwitchBack "3";
BA_ "FieldType" SG_ 1374 VCSEATP_a228_seatSwitchForward "switchStatus";
BA_ "GenSigSNA" SG_ 1374 VCSEATP_a228_seatSwitchForward "3";
BA_ "FieldType" SG_ 1374 VCSEATP_a229_seatMotorState "SEAT_seatState";
BA_ "FieldType" SG_ 1374 VCSEATP_a229_seatSwitchBack "switchStatus";
BA_ "GenSigSNA" SG_ 1374 VCSEATP_a229_seatSwitchBack "3";
BA_ "FieldType" SG_ 1374 VCSEATP_a229_seatSwitchForward "switchStatus";
BA_ "GenSigSNA" SG_ 1374 VCSEATP_a229_seatSwitchForward "3";
BA_ "FieldType" SG_ 1374 VCSEATP_a230_seatMotorState "SEAT_seatState";
BA_ "FieldType" SG_ 1374 VCSEATP_a230_seatSwitchBack "switchStatus";
BA_ "GenSigSNA" SG_ 1374 VCSEATP_a230_seatSwitchBack "3";
BA_ "FieldType" SG_ 1374 VCSEATP_a230_seatSwitchForward "switchStatus";
BA_ "GenSigSNA" SG_ 1374 VCSEATP_a230_seatSwitchForward "3";
BA_ "FieldType" SG_ 1374 VCSEATP_a231_seatMotorState "SEAT_seatState";
BA_ "FieldType" SG_ 1374 VCSEATP_a231_seatSwitchBack "switchStatus";
BA_ "GenSigSNA" SG_ 1374 VCSEATP_a231_seatSwitchBack "3";
BA_ "FieldType" SG_ 1374 VCSEATP_a231_seatSwitchForward "switchStatus";
BA_ "GenSigSNA" SG_ 1374 VCSEATP_a231_seatSwitchForward "3";
BA_ "FieldType" SG_ 1374 VCSEATP_a232_seatMotorState "SEAT_seatState";
BA_ "FieldType" SG_ 1374 VCSEATP_a232_seatSwitchBack "switchStatus";
BA_ "GenSigSNA" SG_ 1374 VCSEATP_a232_seatSwitchBack "3";
BA_ "FieldType" SG_ 1374 VCSEATP_a232_seatSwitchForward "switchStatus";
BA_ "GenSigSNA" SG_ 1374 VCSEATP_a232_seatSwitchForward "3";
BA_ "FieldType" SG_ 1374 VCSEATP_a233_seatMotorState "SEAT_seatState";
BA_ "FieldType" SG_ 1374 VCSEATP_a233_seatSwitchBack "switchStatus";
BA_ "GenSigSNA" SG_ 1374 VCSEATP_a233_seatSwitchBack "3";
BA_ "FieldType" SG_ 1374 VCSEATP_a233_seatSwitchForward "switchStatus";
BA_ "GenSigSNA" SG_ 1374 VCSEATP_a233_seatSwitchForward "3";
BA_ "FieldType" SG_ 1374 VCSEATP_a234_seatMotorState "SEAT_seatState";
BA_ "FieldType" SG_ 1374 VCSEATP_a234_seatSwitchBack "switchStatus";
BA_ "GenSigSNA" SG_ 1374 VCSEATP_a234_seatSwitchBack "3";
BA_ "FieldType" SG_ 1374 VCSEATP_a234_seatSwitchForward "switchStatus";
BA_ "GenSigSNA" SG_ 1374 VCSEATP_a234_seatSwitchForward "3";
BA_ "FieldType" SG_ 1374 VCSEATP_a235_seatMotorState "SEAT_seatState";
BA_ "FieldType" SG_ 1374 VCSEATP_a235_seatSwitchBack "switchStatus";
BA_ "GenSigSNA" SG_ 1374 VCSEATP_a235_seatSwitchBack "3";
BA_ "FieldType" SG_ 1374 VCSEATP_a235_seatSwitchForward "switchStatus";
BA_ "GenSigSNA" SG_ 1374 VCSEATP_a235_seatSwitchForward "3";
BA_ "FieldType" SG_ 1374 VCSEATP_a236_lumbarAState "SEAT_seatState";
BA_ "FieldType" SG_ 1374 VCSEATP_a236_lumbarBState "SEAT_seatState";
BA_ "FieldType" SG_ 1374 VCSEATP_a237_lumbarAState "SEAT_seatState";
BA_ "FieldType" SG_ 1374 VCSEATP_a237_lumbarBState "SEAT_seatState";
BA_ "FieldType" SG_ 1374 VCSEATP_a238_lumbarAState "SEAT_seatState";
BA_ "FieldType" SG_ 1374 VCSEATP_a238_lumbarBState "SEAT_seatState";
BA_ "FieldType" SG_ 1374 VCSEATP_a251_seatMotorState "SEAT_seatState";
BA_ "FieldType" SG_ 1374 VCSEATP_a251_seatSwitchBack "switchStatus";
BA_ "GenSigSNA" SG_ 1374 VCSEATP_a251_seatSwitchBack "3";
BA_ "FieldType" SG_ 1374 VCSEATP_a251_seatSwitchForward "switchStatus";
BA_ "GenSigSNA" SG_ 1374 VCSEATP_a251_seatSwitchForward "3";
BA_ "FieldType" SG_ 1374 VCSEATP_a252_seatMotorState "SEAT_seatState";
BA_ "FieldType" SG_ 1374 VCSEATP_a252_seatSwitchBack "switchStatus";
BA_ "GenSigSNA" SG_ 1374 VCSEATP_a252_seatSwitchBack "3";
BA_ "FieldType" SG_ 1374 VCSEATP_a252_seatSwitchForward "switchStatus";
BA_ "GenSigSNA" SG_ 1374 VCSEATP_a252_seatSwitchForward "3";
BA_ "FieldType" SG_ 1374 VCSEATP_a253_seatMotorState "SEAT_seatState";
BA_ "FieldType" SG_ 1374 VCSEATP_a253_seatSwitchBack "switchStatus";
BA_ "GenSigSNA" SG_ 1374 VCSEATP_a253_seatSwitchBack "3";
BA_ "FieldType" SG_ 1374 VCSEATP_a253_seatSwitchForward "switchStatus";
BA_ "GenSigSNA" SG_ 1374 VCSEATP_a253_seatSwitchForward "3";
BA_ "FieldType" SG_ 1374 VCSEATP_a254_seatMotorState "SEAT_seatState";
BA_ "FieldType" SG_ 1374 VCSEATP_a254_seatSwitchBack "switchStatus";
BA_ "GenSigSNA" SG_ 1374 VCSEATP_a254_seatSwitchBack "3";
BA_ "FieldType" SG_ 1374 VCSEATP_a254_seatSwitchForward "switchStatus";
BA_ "GenSigSNA" SG_ 1374 VCSEATP_a254_seatSwitchForward "3";
BA_ "FieldType" SG_ 1374 VCSEATP_a263_seatMotorState "SEAT_seatState";
BA_ "FieldType" SG_ 1374 VCSEATP_a264_seatMotorState "SEAT_seatState";
BA_ "FieldType" SG_ 1374 VCSEATP_a265_seatMotorState "SEAT_seatState";
BA_ "FieldType" SG_ 1374 VCSEATP_a266_seatMotorState "SEAT_seatState";
BA_ "FieldType" SG_ 1374 VCSEATP_a267_seatMotorState "SEAT_seatState";
BA_ "FieldType" SG_ 1374 VCSEATP_a268_seatMotorState "SEAT_seatState";
BA_ "FieldType" SG_ 1374 VCSEATP_a269_seatMotorState "SEAT_seatState";
BA_ "FieldType" SG_ 1374 VCSEATP_a270_seatMotorState "SEAT_seatState";
BA_ "GenSigStartValue" SG_ 1374 VCSEATP_a380_ocsTempRaw 90;
BA_ "GenSigStartValue" SG_ 1374 VCSEATP_a381_ocsTempRaw 90;
BA_ "GenSigStartValue" SG_ 1374 VCSEATP_a382_ocsTempRaw 90;
BA_ "GenSigStartValue" SG_ 1374 VCSEATP_a386_ocsTempRaw 90;
BA_ "GenSigStartValue" SG_ 1374 VCSEATP_a387_ocsTempRaw 90;
BA_ "GenSigStartValue" SG_ 1374 VCSEATP_a388_ocsTempRaw 90;
BA_ "GenSigStartValue" SG_ 1374 VCSEATP_a389_ocsTempRaw 16852;
BA_ "GenSigStartValue" SG_ 1374 VCSEATP_a397_ocsTempCalib 16852;
BA_ "GenSigStartValue" SG_ 1374 VCSEATP_a401_ocsCushionRaw -23000;
BA_ "GenSigStartValue" SG_ 1374 VCSEATP_a401_ocsSpareRaw -23000;
BA_ "GenSigStartValue" SG_ 1374 VCSEATP_a401_ocsTempRaw 80;
BA_ "FieldType" SG_ 1374 VCSEATP_a401_occupancySwitch "switchStatus";
BA_ "GenSigSNA" SG_ 1374 VCSEATP_a401_occupancySwitch "3";
BA_ "GenSigSNA" SG_ 1374 VCSEATP_a415_occupancyTimeMins "65535";
BA_ "FieldType" SG_ 999 VCSEATP_matrixIndex "VCSEATP_AlertMatrixIndex";
BA_ "FieldType" SG_ 867 VCSEATP_crashDetectedType "crashDetectedType";
BA_ "LogSignal" SG_ 867 VCSEATP_crashDetectedType "onChange";
BA_ "FieldType" SG_ 867 VCSEATP_crashState "crashState";
BA_ "LogSignal" SG_ 867 VCSEATP_crashState "onChange";
BA_ "LogSignal" SG_ 867 VCSEATP_crashNumSwitchesDisabled "onChange";
BA_ "LogSignal" SG_ 867 VCSEATP_crashUnlockOverrideSet "onChange";
BA_ "FieldType" SG_ 773 VCSEATP_infoIndex "bcInfoIndex";
BA_ "FieldType" SG_ 773 VCSEATP_infoBuildType "buildType";
BA_ "LogSignal" SG_ 773 VCSEATP_infoBuildConfigId "periodic ONE_DAY Any";
BA_ "FieldType" SG_ 773 VCSEATP_infoAssemblyId "infoAssemblyID";
BA_ "GenSigSNA" SG_ 773 VCSEATP_infoAssemblyId "255";
BA_ "GenSigStartValue" SG_ 773 VCSEATP_infoAppCrc 4294967295;
BA_ "GenSigStartValue" SG_ 773 VCSEATP_infoPlatformType 255;
BA_ "FieldType" SG_ 1842 VCSEATP_ocsSensorStatusIndex "SEAT_ocsSensorStatusIndex";
BA_ "LogSignal" SG_ 1842 VCSEATP_tosRawCushion "periodic ONE_MINUTE Any";
BA_ "LogSignal" SG_ 1842 VCSEATP_tosRawSpare "periodic ONE_MINUTE Any";
BA_ "GenSigStartValue" SG_ 1842 VCSEATP_ocsTemperature 16852;
BA_ "LogSignal" SG_ 1842 VCSEATP_ocsTemperature "periodic ONE_MINUTE Any";
BA_ "LogSignal" SG_ 1842 VCSEATP_ocsHumidity "periodic ONE_MINUTE Any";
BA_ "LogSignal" SG_ 1842 VCSEATP_tosFilteredCushion "periodic ONE_MINUTE Any";
BA_ "LogSignal" SG_ 1842 VCSEATP_tosFilteredSpare "periodic ONE_MINUTE Any";
BA_ "LogSignal" SG_ 1842 VCSEATP_tosDeltaDisconnected "periodic ONE_MINUTE Any";
BA_ "LogSignal" SG_ 1842 VCSEATP_tosDeltaOffset "onChange";
BA_ "LogSignal" SG_ 1842 VCSEATP_tosDeltaEmpty "periodic ONE_MINUTE Any";
BA_ "LogSignal" SG_ 1842 VCSEATP_tosRelative "periodic ONE_MINUTE Any";
BA_ "LogSignal" SG_ 1842 VCSEATP_classificationLocked "onChange";
BA_ "FieldType" SG_ 1842 VCSEATP_classificationRaw "SEAT_occupantClassification";
BA_ "GenSigSNA" SG_ 1842 VCSEATP_classificationRaw "7";
BA_ "LogSignal" SG_ 1842 VCSEATP_classificationRaw "onChange";
BA_ "FieldType" SG_ 1844 VCSEATP_ocsSensorStatus2Index "SEAT_ocsSensorStatus2Index";
BA_ "LogSignal" SG_ 1844 VCSEATP_ocsCalibCushionEmpty "periodic ONE_DAY Any";
BA_ "LogSignal" SG_ 1844 VCSEATP_ocsCalibSpareEmpty "periodic ONE_DAY Any";
BA_ "GenSigStartValue" SG_ 1844 VCSEATP_ocsCalibTempEmpty 16852;
BA_ "LogSignal" SG_ 1844 VCSEATP_ocsCalibTempEmpty "periodic ONE_DAY Any";
BA_ "LogSignal" SG_ 1844 VCSEATP_ocsFieldCalibrated "periodic ONE_DAY Any";
BA_ "LogSignal" SG_ 1844 VCSEATP_ocsCalibHumidityEmpty "periodic ONE_DAY Any";
BA_ "LogSignal" SG_ 1844 VCSEATP_ocsCalibCushionDisc "periodic ONE_DAY Any";
BA_ "LogSignal" SG_ 1844 VCSEATP_ocsCalibSpareDisc "periodic ONE_DAY Any";
BA_ "GenSigStartValue" SG_ 1844 VCSEATP_ocsCalibTempDisc 16852;
BA_ "LogSignal" SG_ 1844 VCSEATP_ocsCalibTempDisc "periodic ONE_DAY Any";
BA_ "LogSignal" SG_ 1844 VCSEATP_ocsCalibHumidityDisc "periodic ONE_DAY Any";
BA_ "FieldType" SG_ 1861 VCSEATP_systemRecallStatus "recallStatus";
BA_ "GenSigSNA" SG_ 1861 VCSEATP_systemRecallStatus "0";
BA_ "LogSignal" SG_ 1861 VCSEATP_systemRecallStatus "onChange";
BA_ "FieldType" SG_ 1861 VCSEATP_seatRecallStatus "recallStatus";
BA_ "GenSigSNA" SG_ 1861 VCSEATP_seatRecallStatus "0";
BA_ "LogSignal" SG_ 1861 VCSEATP_seatRecallStatus "onChange";
BA_ "FieldType" SG_ 779 VCSEATP_occupantClassification "SEAT_occupantClassification";
BA_ "GenSigSNA" SG_ 779 VCSEATP_occupantClassification "7";
BA_ "LogSignal" SG_ 779 VCSEATP_occupantClassification "onChange";
BA_ "FieldType" SG_ 779 VCSEATP_occupantClassificationQF "SEAT_occupantClassificationQF";
BA_ "LogSignal" SG_ 779 VCSEATP_occupantClassificationQF "onChange";
BA_ "FieldType" SG_ 779 VCSEATP_occupancyStatus "VCSEAT1_occupancyStatus";
BA_ "GenSigSNA" SG_ 779 VCSEATP_occupancyStatus "7";
BA_ "LogSignal" SG_ 779 VCSEATP_occupancyStatus "onChange";
BA_ "FieldType" SG_ 779 VCSEATP_buckleStatus "VCSEAT1_buckleStatus";
BA_ "GenSigSNA" SG_ 779 VCSEATP_buckleStatus "3";
BA_ "LogSignal" SG_ 779 VCSEATP_buckleStatus "onChange";
BA_ "FieldType" SG_ 779 VCSEATP_seatTrackPosition "SEAT_seatTrackPosition";
BA_ "GenSigSNA" SG_ 779 VCSEATP_seatTrackPosition "7";
BA_ "LogSignal" SG_ 779 VCSEATP_seatTrackPosition "periodic ONE_MINUTE Any";
BA_ "GenSigSNA" SG_ 779 VCSEATP_absSeatTrackPosition "255";
BA_ "GenSigStartValue" SG_ 779 VCSEATP_absSeatTrackPosition 255;
BA_ "LogSignal" SG_ 779 VCSEATP_absSeatTrackPosition "periodic ONE_MINUTE Any";
BA_ "FieldType" SG_ 1251 VCSEATP_seatStatusIndex "SEAT_seatStatusIndex";
BA_ "LogSignal" SG_ 1251 VCSEATP_frontSeatTrackPos "onChange";
BA_ "LogSignal" SG_ 1251 VCSEATP_frontSeatTrackCurrent "periodic ONE_DAY Any";
BA_ "LogSignal" SG_ 1251 VCSEATP_frontSeatTrackDuty "onChange";
BA_ "FieldType" SG_ 1251 VCSEATP_frontSeatTrackState "SEAT_seatState";
BA_ "LogSignal" SG_ 1251 VCSEATP_frontSeatTrackState "onChange";
BA_ "LogSignal" SG_ 1251 VCSEATP_frontSeatTrackCalibrated "periodic ONE_DAY Any";
BA_ "LogSignal" SG_ 1251 VCSEATP_frontSeatTrackLog "onChange";
BA_ "LogSignal" SG_ 1251 VCSEATP_frontSeatBackPos "onChange";
BA_ "LogSignal" SG_ 1251 VCSEATP_frontSeatBackCurrent "periodic ONE_DAY Any";
BA_ "LogSignal" SG_ 1251 VCSEATP_frontSeatBackDuty "onChange";
BA_ "FieldType" SG_ 1251 VCSEATP_frontSeatBackState "SEAT_seatState";
BA_ "LogSignal" SG_ 1251 VCSEATP_frontSeatBackState "onChange";
BA_ "LogSignal" SG_ 1251 VCSEATP_frontSeatBackCalibrated "periodic ONE_DAY Any";
BA_ "LogSignal" SG_ 1251 VCSEATP_frontSeatBackLog "onChange";
BA_ "LogSignal" SG_ 1251 VCSEATP_frontSeatLiftPos "onChange";
BA_ "LogSignal" SG_ 1251 VCSEATP_frontSeatLiftCurrent "periodic ONE_DAY Any";
BA_ "LogSignal" SG_ 1251 VCSEATP_frontSeatLiftDuty "onChange";
BA_ "FieldType" SG_ 1251 VCSEATP_frontSeatLiftState "SEAT_seatState";
BA_ "LogSignal" SG_ 1251 VCSEATP_frontSeatLiftState "onChange";
BA_ "LogSignal" SG_ 1251 VCSEATP_frontSeatLiftCalibrated "periodic ONE_DAY Any";
BA_ "LogSignal" SG_ 1251 VCSEATP_frontSeatLiftLog "onChange";
BA_ "LogSignal" SG_ 1251 VCSEATP_frontSeatTiltPos "onChange";
BA_ "LogSignal" SG_ 1251 VCSEATP_frontSeatTiltCurrent "periodic ONE_DAY Any";
BA_ "LogSignal" SG_ 1251 VCSEATP_frontSeatTiltDuty "onChange";
BA_ "FieldType" SG_ 1251 VCSEATP_frontSeatTiltState "SEAT_seatState";
BA_ "LogSignal" SG_ 1251 VCSEATP_frontSeatTiltState "onChange";
BA_ "LogSignal" SG_ 1251 VCSEATP_frontSeatTiltCalibrated "periodic ONE_DAY Any";
BA_ "LogSignal" SG_ 1251 VCSEATP_frontSeatTiltLog "onChange";
BA_ "FieldType" SG_ 1251 VCSEATP_lumbarAState "SEAT_seatState";
BA_ "LogSignal" SG_ 1251 VCSEATP_lumbarAState "onChange";
BA_ "FieldType" SG_ 1251 VCSEATP_lumbarBState "SEAT_seatState";
BA_ "LogSignal" SG_ 1251 VCSEATP_lumbarBState "onChange";
BA_ "LogSignal" SG_ 1251 VCSEATP_lumbarAPressureHpa "periodic TEN_SECONDS Any";
BA_ "LogSignal" SG_ 1251 VCSEATP_lumbarBPressureHpa "periodic TEN_SECONDS Any";
BA_ "LogSignal" SG_ 1251 VCSEATP_lumbarActiveTooLongErr "onChange";
BA_ "LogSignal" SG_ 1251 VCSEATP_lumbarMaxPErr "onChange";
BA_ "LogSignal" SG_ 1251 VCSEATP_lumbarOvercurrentErr "onChange";
BA_ "LogSignal" SG_ 1251 VCSEATP_lumbarMaxOperatingPErr "onChange";
BA_ "LogSignal" SG_ 1251 VCSEATP_lumbarMinPErr "onChange";
BA_ "LogSignal" SG_ 1251 VCSEATP_lumbarGeneralErr "onChange";
BA_ "LogSignal" SG_ 1251 VCSEATP_lumbarDevMaxPumpPressA "onChange";
BA_ "LogSignal" SG_ 1251 VCSEATP_lumbarDevMaxPumpPressB "onChange";
BA_ "LogSignal" SG_ 1251 VCSEATP_frontSeatTrackPosReal "onChange";
BA_ "LogSignal" SG_ 1251 VCSEATP_frontSeatBackPosReal "onChange";
BA_ "LogSignal" SG_ 1251 VCSEATP_frontSeatLiftPosReal "onChange";
BA_ "LogSignal" SG_ 1251 VCSEATP_frontSeatTiltPosReal "onChange";
BA_ "LogSignal" SG_ 1909 VCSEATP_frontSeatTrackPos10Hz "onChange";
BA_ "LogSignal" SG_ 1909 VCSEATP_frontSeatBackPos10Hz "onChange";
BA_ "LogSignal" SG_ 1909 VCSEATP_frontSeatLiftPos10Hz "onChange";
BA_ "FieldType" SG_ 1909 VCSEATP_frontSeatTrackState10Hz "SEAT_seatState";
BA_ "LogSignal" SG_ 1909 VCSEATP_frontSeatTrackState10Hz "onChange";
BA_ "FieldType" SG_ 1909 VCSEATP_frontSeatBackState10Hz "SEAT_seatState";
BA_ "LogSignal" SG_ 1909 VCSEATP_frontSeatBackState10Hz "onChange";
BA_ "FieldType" SG_ 1909 VCSEATP_frontSeatLiftState10Hz "SEAT_seatState";
BA_ "LogSignal" SG_ 1909 VCSEATP_frontSeatLiftState10Hz "onChange";
BA_ "FieldType" SG_ 1909 VCSEATP_frontSeatTiltState10Hz "SEAT_seatState";
BA_ "LogSignal" SG_ 1909 VCSEATP_frontSeatTiltState10Hz "onChange";
BA_ "FieldType" SG_ 740 VCSEATP_seatStatus2Index "VCSEAT1_seatStatus2Index";
BA_ "LogSignal" SG_ 740 VCSEATP_frontSeatHeatCurrent "periodic ONE_MINUTE Any";
BA_ "LogSignal" SG_ 740 VCSEATP_frontSeatHeatDuty "periodic ONE_MINUTE Any";
BA_ "LogSignal" SG_ 740 VCSEATP_frontSeatHeatTmp "periodic ONE_MINUTE Any";
BA_ "LogSignal" SG_ 740 VCSEATP_frontSeatHeatTmpTarget "periodic FIVE_MINUTES Any";
BA_ "LogSignal" SG_ 740 VCSEATP_frontSeatHeatInhibited "periodic FIVE_MINUTES Any";
BA_ "LogSignal" SG_ 740 VCSEATP_frontOccupancyVoltage "periodic ONE_MINUTE Any";
BA_ "LogSignal" SG_ 740 VCSEATP_frontBuckleVoltage "periodic ONE_MINUTE Any";
BA_ "FieldType" SG_ 932 VCSEATP_vehiclePowerStateDBG "vehiclePowerState";
BA_ "LogSignal" SG_ 932 VCSEATP_vehiclePowerStateDBG "onChange";
BA_ "LogSignal" SG_ 932 VCSEATP_OTAState "onChange";
BA_ "LogSignal" SG_ 932 VCSEATP_5AVoltage "periodic TEN_SECONDS Any";
BA_ "LogSignal" SG_ 932 VCSEATP_vbatProt "periodic TEN_SECONDS Any";
BA_ "LogSignal" SG_ 932 VCSEATP_pcbaTemperature "periodic FIVE_MINUTES Any";
BA_ "FieldType" SG_ 965 VCSEATP_switchStatusIndex "VCSEAT1_switchStatusIndex";
BA_ "FieldType" SG_ 965 VCSEATP_frontSeatTrackBack "switchStatus";
BA_ "GenSigSNA" SG_ 965 VCSEATP_frontSeatTrackBack "3";
BA_ "LogSignal" SG_ 965 VCSEATP_frontSeatTrackBack "onChange";
BA_ "FieldType" SG_ 965 VCSEATP_frontSeatTrackForward "switchStatus";
BA_ "GenSigSNA" SG_ 965 VCSEATP_frontSeatTrackForward "3";
BA_ "LogSignal" SG_ 965 VCSEATP_frontSeatTrackForward "onChange";
BA_ "FieldType" SG_ 965 VCSEATP_frontSeatTiltDown "switchStatus";
BA_ "GenSigSNA" SG_ 965 VCSEATP_frontSeatTiltDown "3";
BA_ "LogSignal" SG_ 965 VCSEATP_frontSeatTiltDown "onChange";
BA_ "FieldType" SG_ 965 VCSEATP_frontSeatTiltUp "switchStatus";
BA_ "GenSigSNA" SG_ 965 VCSEATP_frontSeatTiltUp "3";
BA_ "LogSignal" SG_ 965 VCSEATP_frontSeatTiltUp "onChange";
BA_ "FieldType" SG_ 965 VCSEATP_frontSeatLiftDown "switchStatus";
BA_ "GenSigSNA" SG_ 965 VCSEATP_frontSeatLiftDown "3";
BA_ "LogSignal" SG_ 965 VCSEATP_frontSeatLiftDown "onChange";
BA_ "FieldType" SG_ 965 VCSEATP_frontSeatLiftUp "switchStatus";
BA_ "GenSigSNA" SG_ 965 VCSEATP_frontSeatLiftUp "3";
BA_ "LogSignal" SG_ 965 VCSEATP_frontSeatLiftUp "onChange";
BA_ "FieldType" SG_ 965 VCSEATP_frontSeatBackrestBack "switchStatus";
BA_ "GenSigSNA" SG_ 965 VCSEATP_frontSeatBackrestBack "3";
BA_ "LogSignal" SG_ 965 VCSEATP_frontSeatBackrestBack "onChange";
BA_ "FieldType" SG_ 965 VCSEATP_frontSeatBackrestForward "switchStatus";
BA_ "GenSigSNA" SG_ 965 VCSEATP_frontSeatBackrestForward "3";
BA_ "LogSignal" SG_ 965 VCSEATP_frontSeatBackrestForward "onChange";
BA_ "FieldType" SG_ 965 VCSEATP_frontSeatLumbarDown "switchStatus";
BA_ "GenSigSNA" SG_ 965 VCSEATP_frontSeatLumbarDown "3";
BA_ "LogSignal" SG_ 965 VCSEATP_frontSeatLumbarDown "onChange";
BA_ "FieldType" SG_ 965 VCSEATP_frontSeatLumbarUp "switchStatus";
BA_ "GenSigSNA" SG_ 965 VCSEATP_frontSeatLumbarUp "3";
BA_ "LogSignal" SG_ 965 VCSEATP_frontSeatLumbarUp "onChange";
BA_ "FieldType" SG_ 965 VCSEATP_frontSeatLumbarIn "switchStatus";
BA_ "GenSigSNA" SG_ 965 VCSEATP_frontSeatLumbarIn "3";
BA_ "LogSignal" SG_ 965 VCSEATP_frontSeatLumbarIn "onChange";
BA_ "FieldType" SG_ 965 VCSEATP_frontSeatLumbarOut "switchStatus";
BA_ "GenSigSNA" SG_ 965 VCSEATP_frontSeatLumbarOut "3";
BA_ "LogSignal" SG_ 965 VCSEATP_frontSeatLumbarOut "onChange";
BA_ "FieldType" SG_ 965 VCSEATP_frontBuckleSwitch "switchStatus";
BA_ "GenSigSNA" SG_ 965 VCSEATP_frontBuckleSwitch "3";
BA_ "LogSignal" SG_ 965 VCSEATP_frontBuckleSwitch "onChange";
BA_ "FieldType" SG_ 965 VCSEATP_frontOccupancySwitch "switchStatus";
BA_ "GenSigSNA" SG_ 965 VCSEATP_frontOccupancySwitch "3";
BA_ "LogSignal" SG_ 965 VCSEATP_frontOccupancySwitch "onChange";
BA_ "GenSigSendType" SG_ 1763 VCSEATP_udsResponseData_H 1;
BA_ "GenSigSendType" SG_ 1763 VCSEATP_udsResponseData_L 1;
BA_ "FieldType" SG_ 1059 VCSEATP_nmKeepAwakeReason "VCSEAT1_nmKeepAwakeReason";
BA_ "GenSigSNA" SG_ 1059 VCSEATP_nmKeepAwakeReason "0";
BA_ "LogSignal" SG_ 1059 VCSEATP_nmKeepAwakeReason "onChange";
BA_ "FieldType" SG_ 1059 VCSEATP_nmWakeUpReason "VCSEAT1_nmWakeUpReason";
BA_ "LogSignal" SG_ 1059 VCSEATP_nmWakeUpReason "onChange";
BA_ "LogSignal" SG_ 1059 VCSEATP_nmDebugWakeUp "onChange";
BA_ "FlexKomComment" SG_ 1816 CH_GTW_vinDataBytesIndex "Vehicle identification number";
BA_ "FlexKomIsMotorola" SG_ 1816 CH_GTW_vinDataBytesIndex 1;
BA_ "FlexKomSID" SG_ 1816 CH_GTW_vinDataBytesIndex 117440594;
BA_ "FlexKomSigLaenge" SG_ 1816 CH_GTW_vinDataBytesIndex 64;
BA_ "FlexKomSigName" SG_ 1816 CH_GTW_vinDataBytesIndex "VehIdNum";
BA_ "FlexKomSigStartPos" SG_ 1816 CH_GTW_vinDataBytesIndex 7;
BA_ "FlexKomSigStartValue" SG_ 1816 CH_GTW_vinDataBytesIndex "0300000000000000h";
BA_ "GenSigSNA" SG_ 1816 CH_GTW_vinDataBytesIndex "3";
BA_ "GenSigSendType" SG_ 1816 CH_GTW_vinDataBytesIndex 1;
BA_ "GenSigStartValue" SG_ 1816 CH_GTW_vinDataBytesIndex 3;
BA_ "GenSigTimeout_SCCM" SG_ 1816 CH_GTW_vinDataBytesIndex 10500;
BA_ "GenSigTimeout_SPC" SG_ 1816 CH_GTW_vinDataBytesIndex 10500;
BA_ "FlexKomComment" SG_ 1816 CH_GTW_vinPartData "Vehicle identification number";
BA_ "FlexKomIsMotorola" SG_ 1816 CH_GTW_vinPartData 1;
BA_ "FlexKomSID" SG_ 1816 CH_GTW_vinPartData 117440594;
BA_ "FlexKomSigLaenge" SG_ 1816 CH_GTW_vinPartData 64;
BA_ "FlexKomSigName" SG_ 1816 CH_GTW_vinPartData "VehIdNum";
BA_ "FlexKomSigStartPos" SG_ 1816 CH_GTW_vinPartData 7;
BA_ "FlexKomSigStartValue" SG_ 1816 CH_GTW_vinPartData "0300000000000000h";
BA_ "GenSigSendType" SG_ 1816 CH_GTW_vinPartData 1;
BA_ "GenSigTimeout_SCCM" SG_ 1816 CH_GTW_vinPartData 10500;
BA_ "GenSigTimeout_SPC" SG_ 1816 CH_GTW_vinPartData 10500;
BA_ "GenSigCycleTime" SG_ 1029 EPASParamMux 100;
BA_ "GenSigCycleTimeActive" SG_ 1029 EPASParamMux 100;
BA_ "GenSigCycleTime" SG_ 1029 EPASGlobalTime 100;
BA_ "GenSigCycleTimeActive" SG_ 1029 EPASGlobalTime 100;
BA_ "GenSigCycleTime" SG_ 1029 EPASSignalConfigID 100;
BA_ "GenSigCycleTimeActive" SG_ 1029 EPASSignalConfigID 100;
BA_ "GenSigStartValue" SG_ 1029 EPASSignalConfigID 24864;
BA_ "GenSigCycleTime" SG_ 1029 EPASInCarTemp 100;
BA_ "GenSigCycleTimeActive" SG_ 1029 EPASInCarTemp 100;
BA_ "GenSigStartValue" SG_ 1029 EPASInCarTemp 40;
BA_ "GenSigCycleTime" SG_ 1029 EPASOutdoorTemp 100;
BA_ "GenSigCycleTimeActive" SG_ 1029 EPASOutdoorTemp 100;
BA_ "GenSigStartValue" SG_ 1029 EPASOutdoorTemp 40;
BA_ "GenSigCycleTime" SG_ 1029 EPASMainECUVoltage 100;
BA_ "GenSigCycleTimeActive" SG_ 1029 EPASMainECUVoltage 100;
BA_ "GenSigCycleTime" SG_ 1029 EPASTotalDistance 100;
BA_ "GenSigCycleTimeActive" SG_ 1029 EPASTotalDistance 100;
BA_ "GenSigCycleTime" SG_ 1029 EPASVin_h 100;
BA_ "GenSigCycleTimeActive" SG_ 1029 EPASVin_h 100;
BA_ "GenSigStartValue" SG_ 1029 EPASVin_h 32;
BA_ "GenSigCycleTime" SG_ 1029 EPASVin_m 100;
BA_ "GenSigCycleTimeActive" SG_ 1029 EPASVin_m 100;
BA_ "GenSigStartValue" SG_ 1029 EPASVin_m 32;
BA_ "GenSigCycleTime" SG_ 1029 EPASVin_l 100;
BA_ "GenSigCycleTimeActive" SG_ 1029 EPASVin_l 100;
BA_ "GenSigSendType" SG_ 1835 XCP_tasRequest 7;
BA_ "GenSigSendType" SG_ 1878 XCP_vcseatdRequestData 7;
BA_ "GenSigSendType" SG_ 1879 XCP_vcseatpRequestData 7;
VAL_ 1860 VCSEATD_systemRecallStatus 3 "RECALL_INTERRUPTED" 2 "RECALL_COMPLETE" 1 "RECALL_IN_PROGRESS" 0 "RECALL_SNA" ;
VAL_ 1860 VCSEATD_seatRecallStatus 3 "RECALL_INTERRUPTED" 2 "RECALL_COMPLETE" 1 "RECALL_IN_PROGRESS" 0 "RECALL_SNA" ;
VAL_ 780 VCSEATD_occupantClassification 7 "SEAT_OCCUPANT_CLASSIFICATON_SNA" 5 "SEAT_OCCUPANT_CLASSIFICATON_NOT_CONFIGURED" 4 "SEAT_OCCUPANT_CLASSIFICATON_INIT" 3 "SEAT_OCCUPANT_CLASSIFICATON_LARGE" 2 "SEAT_OCCUPANT_CLASSIFICATON_SMALL" 1 "SEAT_OCCUPANT_CLASSIFICATON_INHIBIT" 0 "SEAT_OCCUPANT_CLASSIFICATON_EMPTY" ;
VAL_ 780 VCSEATD_occupantClassificationQF 1 "SEAT_OCCUPANT_CLASSIFICATON_NOT_FAULTED" 0 "SEAT_OCCUPANT_CLASSIFICATON_FAULTED" ;
VAL_ 780 VCSEATD_occupancyStatus 7 "VCSEAT_OCCUPANCY_SNA" 3 "VCSEAT_NOT_CONFIGURED" 2 "VCSEAT_OCCUPANCY_FAULTED" 1 "VCSEAT_OCCUPIED" 0 "VCSEAT_UNOCCUPIED" ;
VAL_ 780 VCSEATD_buckleStatus 3 "VCSEAT_BELT_BUCKLE_STATUS_SNA" 2 "VCSEAT_BELT_BUCKLE_STATUS_FAULTED" 1 "VCSEAT_BELT_BUCKLE_STATUS_LATCHED" 0 "VCSEAT_BELT_BUCKLE_STATUS_UNLATCHED" ;
VAL_ 780 VCSEATD_seatTrackPosition 7 "SEAT_TRACK_POSITION_SNA" 3 "SEAT_TRACK_POSITION_FAULTED" 2 "SEAT_TRACK_POSITION_NOT_CONFIGURED" 1 "SEAT_TRACK_POSITION_REARWARD" 0 "SEAT_TRACK_POSITION_FORWARD" ;
VAL_ 780 VCSEATD_absSeatTrackPosition 255 "ABS_SEAT_TRACK_POSITION_SNA" 254 "ABS_SEAT_TRACK_POSITION_NOT_CONFIGURED" ;
VAL_ 1250 VCSEATD_seatStatusIndex 5 "SEAT_STATUS_INDEX_POSITION" 4 "SEAT_STATUS_INDEX_LUMBAR" 3 "SEAT_STATUS_INDEX_TILT" 2 "SEAT_STATUS_INDEX_LIFT" 1 "SEAT_STATUS_INDEX_BACK" 0 "SEAT_STATUS_INDEX_TRACK" ;
VAL_ 1250 VCSEATD_frontSeatTrackState 5 "SEAT_STATE_UNDEFINED" 4 "SEAT_STATE_CALIBRATING" 3 "SEAT_STATE_RECALLING" 2 "SEAT_STATE_MOVING_DOWN" 1 "SEAT_STATE_MOVING_UP" 0 "SEAT_STATE_STOPPED" ;
VAL_ 1250 VCSEATD_frontSeatBackState 5 "SEAT_STATE_UNDEFINED" 4 "SEAT_STATE_CALIBRATING" 3 "SEAT_STATE_RECALLING" 2 "SEAT_STATE_MOVING_DOWN" 1 "SEAT_STATE_MOVING_UP" 0 "SEAT_STATE_STOPPED" ;
VAL_ 1250 VCSEATD_frontSeatLiftState 5 "SEAT_STATE_UNDEFINED" 4 "SEAT_STATE_CALIBRATING" 3 "SEAT_STATE_RECALLING" 2 "SEAT_STATE_MOVING_DOWN" 1 "SEAT_STATE_MOVING_UP" 0 "SEAT_STATE_STOPPED" ;
VAL_ 1250 VCSEATD_frontSeatTiltState 5 "SEAT_STATE_UNDEFINED" 4 "SEAT_STATE_CALIBRATING" 3 "SEAT_STATE_RECALLING" 2 "SEAT_STATE_MOVING_DOWN" 1 "SEAT_STATE_MOVING_UP" 0 "SEAT_STATE_STOPPED" ;
VAL_ 1250 VCSEATD_lumbarAState 5 "SEAT_STATE_UNDEFINED" 4 "SEAT_STATE_CALIBRATING" 3 "SEAT_STATE_RECALLING" 2 "SEAT_STATE_MOVING_DOWN" 1 "SEAT_STATE_MOVING_UP" 0 "SEAT_STATE_STOPPED" ;
VAL_ 1250 VCSEATD_lumbarBState 5 "SEAT_STATE_UNDEFINED" 4 "SEAT_STATE_CALIBRATING" 3 "SEAT_STATE_RECALLING" 2 "SEAT_STATE_MOVING_DOWN" 1 "SEAT_STATE_MOVING_UP" 0 "SEAT_STATE_STOPPED" ;
VAL_ 1908 VCSEATD_frontSeatTrackState10Hz 5 "SEAT_STATE_UNDEFINED" 4 "SEAT_STATE_CALIBRATING" 3 "SEAT_STATE_RECALLING" 2 "SEAT_STATE_MOVING_DOWN" 1 "SEAT_STATE_MOVING_UP" 0 "SEAT_STATE_STOPPED" ;
VAL_ 1908 VCSEATD_frontSeatBackState10Hz 5 "SEAT_STATE_UNDEFINED" 4 "SEAT_STATE_CALIBRATING" 3 "SEAT_STATE_RECALLING" 2 "SEAT_STATE_MOVING_DOWN" 1 "SEAT_STATE_MOVING_UP" 0 "SEAT_STATE_STOPPED" ;
VAL_ 1908 VCSEATD_frontSeatLiftState10Hz 5 "SEAT_STATE_UNDEFINED" 4 "SEAT_STATE_CALIBRATING" 3 "SEAT_STATE_RECALLING" 2 "SEAT_STATE_MOVING_DOWN" 1 "SEAT_STATE_MOVING_UP" 0 "SEAT_STATE_STOPPED" ;
VAL_ 1908 VCSEATD_frontSeatTiltState10Hz 5 "SEAT_STATE_UNDEFINED" 4 "SEAT_STATE_CALIBRATING" 3 "SEAT_STATE_RECALLING" 2 "SEAT_STATE_MOVING_DOWN" 1 "SEAT_STATE_MOVING_UP" 0 "SEAT_STATE_STOPPED" ;
VAL_ 738 VCSEATD_seatStatus2Index 3 "VCSEAT1_SEAT_STATUS_2_INDEX_COUNT" 2 "VCSEAT1_OCCUPANCY" 1 "VCSEAT1_SEAT_VOLTAGES" 0 "VCSEAT1_SEAT_HEAT_FRONT" ;
VAL_ 931 VCSEATD_statusIndex 1 "MUX1" 0 "MUX0" ;
VAL_ 931 VCSEATD_vehiclePowerStateDBG 3 "VEHICLE_POWER_STATE_DRIVE" 2 "VEHICLE_POWER_STATE_ACCESSORY" 1 "VEHICLE_POWER_STATE_CONDITIONING" 0 "VEHICLE_POWER_STATE_OFF" ;
VAL_ 964 VCSEATD_switchStatusIndex 2 "VCSEAT1_SWITCH_STATUS_INDEX_INVALID" 1 "VCSEAT1_SWITCH_STATUS_INDEX_1" 0 "VCSEAT1_SWITCH_STATUS_INDEX_0" ;
VAL_ 964 VCSEATD_frontSeatTrackBack 3 "SWITCH_SNA" 2 "SWITCH_FAULT" 1 "SWITCH_ON" 0 "SWITCH_OFF" ;
VAL_ 964 VCSEATD_frontSeatTrackForward 3 "SWITCH_SNA" 2 "SWITCH_FAULT" 1 "SWITCH_ON" 0 "SWITCH_OFF" ;
VAL_ 964 VCSEATD_frontSeatTiltDown 3 "SWITCH_SNA" 2 "SWITCH_FAULT" 1 "SWITCH_ON" 0 "SWITCH_OFF" ;
VAL_ 964 VCSEATD_frontSeatTiltUp 3 "SWITCH_SNA" 2 "SWITCH_FAULT" 1 "SWITCH_ON" 0 "SWITCH_OFF" ;
VAL_ 964 VCSEATD_frontSeatLiftDown 3 "SWITCH_SNA" 2 "SWITCH_FAULT" 1 "SWITCH_ON" 0 "SWITCH_OFF" ;
VAL_ 964 VCSEATD_frontSeatLiftUp 3 "SWITCH_SNA" 2 "SWITCH_FAULT" 1 "SWITCH_ON" 0 "SWITCH_OFF" ;
VAL_ 964 VCSEATD_frontSeatBackrestBack 3 "SWITCH_SNA" 2 "SWITCH_FAULT" 1 "SWITCH_ON" 0 "SWITCH_OFF" ;
VAL_ 964 VCSEATD_frontSeatBackrestForward 3 "SWITCH_SNA" 2 "SWITCH_FAULT" 1 "SWITCH_ON" 0 "SWITCH_OFF" ;
VAL_ 964 VCSEATD_frontSeatLumbarDown 3 "SWITCH_SNA" 2 "SWITCH_FAULT" 1 "SWITCH_ON" 0 "SWITCH_OFF" ;
VAL_ 964 VCSEATD_frontSeatLumbarUp 3 "SWITCH_SNA" 2 "SWITCH_FAULT" 1 "SWITCH_ON" 0 "SWITCH_OFF" ;
VAL_ 964 VCSEATD_frontSeatLumbarIn 3 "SWITCH_SNA" 2 "SWITCH_FAULT" 1 "SWITCH_ON" 0 "SWITCH_OFF" ;
VAL_ 964 VCSEATD_frontSeatLumbarOut 3 "SWITCH_SNA" 2 "SWITCH_FAULT" 1 "SWITCH_ON" 0 "SWITCH_OFF" ;
VAL_ 964 VCSEATD_frontBuckleSwitch 3 "SWITCH_SNA" 2 "SWITCH_FAULT" 1 "SWITCH_ON" 0 "SWITCH_OFF" ;
VAL_ 964 VCSEATD_frontOccupancySwitch 3 "SWITCH_SNA" 2 "SWITCH_FAULT" 1 "SWITCH_ON" 0 "SWITCH_OFF" ;
VAL_ 1058 VCSEATD_nmKeepAwakeReason 15 "VCSEAT1_KEEPAWAKE_REASON_MULTIPLE" 14 "VCSEAT1_KEEPAWAKE_REASON_OTHER" 9 "VCSEAT1_KEEPAWAKE_REASON_INTRUSION_SENSOR_TRIGGERED" 8 "VCSEAT1_KEEPAWAKE_REASON_UDS_ACTIVE" 7 "VCSEAT1_KEEPAWAKE_REASON_SEAT" 6 "VCSEAT1_KEEPAWAKE_REASON_HANDLE_PULLED" 5 "VCSEAT1_KEEPAWAKE_REASON_EPB_SUMMON_ACTIVE" 4 "VCSEAT1_KEEPAWAKE_REASON_CLOSURE_LATCH" 3 "VCSEAT1_KEEPAWAKE_REASON_BRAKE_SWITCH" 2 "VCSEAT1_KEEPAWAKE_REASON_EPB_NOT_SECURE" 1 "VCSEAT1_KEEPAWAKE_REASON_EPB_STATE_NOT_SAVED" 0 "VCSEAT1_KEEPAWAKE_REASON_NONE_SNA" ;
VAL_ 1058 VCSEATD_nmWakeUpReason 15 "VCSEAT1_WAKEUP_REASON_UNKNOWN" 8 "VCSEAT1_WAKEUP_REASON_LIN_RX" 7 "VCSEAT1_WAKEUP_REASON_BRAKE_SWITCH" 6 "VCSEAT1_WAKEUP_REASON_EXTERIOR_HANDLE" 5 "VCSEAT1_WAKEUP_REASON_INTERIOR_HANDLE" 4 "VCSEAT1_WAKEUP_REASON_DOOR_LATCH" 3 "VCSEAT1_WAKEUP_REASON_RESET" 2 "VCSEAT1_WAKEUP_REASON_SWITCH_INPUT" 1 "VCSEAT1_WAKEUP_REASON_ECU_SPECIFIC" 0 "VCSEAT1_WAKEUP_REASON_NONE" ;
VAL_ 900 VCSEATP_CPULoadTotal 255 "SNA" ;
VAL_ 900 VCSEATP_CPULoad1msTask 255 "SNA" ;
VAL_ 900 VCSEATP_CPULoad10msTask 255 "SNA" ;
VAL_ 900 VCSEATP_CPULoad100msTask 255 "SNA" ;
VAL_ 900 VCSEATP_CPULoad1000msTask 255 "SNA" ;
VAL_ 579 VCSEATP_lumbarLVState 3 "LV_FAULT" 2 "LV_GOING_DOWN" 1 "LV_ON" 0 "LV_OFF" ;
VAL_ 1315 VCSEATP_alertClearedID 445 "VCSEATD_a445_drv8703SpiFaultDBG" 444 "VCSEATD_a444_drv8703Fault" 415 "VCSEATD_a415_ocsRebaseEgressDBG" 414 "VCSEATD_a414_ocsMissedIngressDBG" 413 "VCSEATD_a413_ocsSBRFaulted" 412 "VCSEATD_a412_ocsRebaselineDBG" 411 "VCSEATD_a411_ocsDataTimeout" 410 "VCSEATD_a410_ocsSlowDrift" 409 "VCSEATD_a409_ocsHeatPadNoConnect" 408 "VCSEATD_a408_ocsSensorDroop" 407 "VCSEATD_a407_ocsManufactureInvld" 406 "VCSEATD_a406_ocsCalibMismatch" 405 "VCSEATD_a405_ocsSensorDisconnect" 404 "VCSEATD_a404_ocsBackDisconnect" 403 "VCSEATD_a403_ocsSensorHigh" 402 "VCSEATD_a402_ocsSensorLow" 401 "VCSEATD_a401_ocsDiagContext" 400 "VCSEATD_a400_ocsCushionMismatch" 399 "VCSEATD_a399_ocsTHMIA" 398 "VCSEATD_a398_ocsTOSMIA" 397 "VCSEATD_a397_ocsTHInvalCalib" 396 "VCSEATD_a396_ocsSpareInvalCalib" 394 "VCSEATD_a394_ocsCushionInvlCalib" 393 "VCSEATD_a393_ocsTHNoCalib" 392 "VCSEATD_a392_ocsSpareNoCalib" 390 "VCSEATD_a390_ocsCushionNoCalib" 389 "VCSEATD_a389_ocsTHInvalid" 388 "VCSEATD_a388_ocsSpareShort" 387 "VCSEATD_a387_ocsSpareLow" 386 "VCSEATD_a386_ocsSpareHigh" 382 "VCSEATD_a382_ocsCushionShort" 381 "VCSEATD_a381_ocsCushionLow" 380 "VCSEATD_a380_ocsCushionHigh" 291 "VCSEATD_a291_buckleFaultedFront" 290 "VCSEATD_a290_occupancyFaultFront" 270 "VCSEATD_a270_seatLiftHCEncStlDbg" 269 "VCSEATD_a269_seatTiltHCEncStlDbg" 268 "VCSEATD_a268_seatBackHCEncStlDbg" 267 "VCSEATD_a267_seatTrackHCEncStl" 266 "VCSEATD_a266_seatLiftStallDebug" 265 "VCSEATD_a265_seatTiltStallDebug" 264 "VCSEATD_a264_seatBackStallDebug" 263 "VCSEATD_a263_seatTrackStallDebug" 254 "VCSEATD_a254_seatUncalLift" 253 "VCSEATD_a253_seatUncalTilt" 252 "VCSEATD_a252_seatUncalBack" 251 "VCSEATD_a251_seatUncalTrack" 242 "VCSEATD_a242_seatHeatTmpFront" 241 "VCSEATD_a241_seatHeatMIAFront" 240 "VCSEATD_a240_seatHeatShortFront" 239 "VCSEATD_a239_seatHeatIFront" 238 "VCSEATD_a238_lumbarValveMIA" 237 "VCSEATD_a237_lumbarOverPresB" 236 "VCSEATD_a236_lumbarOverPresA" 235 "VCSEATD_a235_seatCurrUnderLift" 234 "VCSEATD_a234_seatCurrUnderTilt" 233 "VCSEATD_a233_seatCurrUnderBack" 232 "VCSEATD_a232_seatCurrUnderTrack" 231 "VCSEATD_a231_seatEncOverLift" 230 "VCSEATD_a230_seatEncOverTilt" 229 "VCSEATD_a229_seatEncOverBack" 228 "VCSEATD_a228_seatEncOverTrack" 227 "VCSEATD_a227_seatEncStallLift" 226 "VCSEATD_a226_seatEncStallTilt" 225 "VCSEATD_a225_seatEncStallBack" 224 "VCSEATD_a224_seatEncStallTrack" 223 "VCSEATD_a223_seatCurrStallLift" 222 "VCSEATD_a222_seatCurrStallTilt" 221 "VCSEATD_a221_seatCurrStallBack" 220 "VCSEATD_a220_seatCurrStallTrack" 219 "VCSEATD_a219_motorCurrentDropout" 218 "VCSEATD_a218_motorDriverFault" 201 "VCSEATD_a201_motorDutyEncDisabl" 200 "VCSEATD_a200_motorPhantomEncoder" 64 "VCSEATD_a064_busSleepReqTimeout" 63 "VCSEATD_a063_SwitchFault" 62 "VCSEATD_a062_XCPWasConnected" 61 "VCSEATD_a061_XCPConnected" 60 "VCSEATD_a060_engineeringBuild" 59 "VCSEATD_a059_inputResistanceHigh" 58 "VCSEATD_a058_inputRHighSyncDebug" 46 "VCSEATD_a046_Task1000msError" 45 "VCSEATD_a045_Task100msError" 44 "VCSEATD_a044_Task10msError" 43 "VCSEATD_a043_Task1msError" 42 "VCSEATD_a042_HighStackUsage" 41 "VCSEATD_a041_HighCPULoad" 31 "VCSEATD_a031_UDSActive" 30 "VCSEATD_a030_ECULogUploadRequest" 22 "VCSEATD_a022_TaskInitError" 21 "VCSEATD_a021_TaskSchedulerError" 15 "VCSEATD_a015_NVMMAlert" 13 "VCSEATD_a013_AlertManagerFault" 12 "VCSEATD_a012_CPUReset" 10 "VCSEATD_a010_ExtSupplyVoltError" 5 "VCSEATD_a005_CANTXError" 3 "VCSEATD_a003_SWAssertion" 2 "VCSEATD_a002_PowerLossReset" 1 "VCSEATD_a001_WatchdogReset" 0 "VCSEATD_ALERT_DO_NOT_USE_ZERO" ;
VAL_ 1374 VCSEATP_alertID 445 "VCSEATP_a445_drv8703SpiFaultDBG" 444 "VCSEATP_a444_drv8703Fault" 415 "VCSEATP_a415_ocsRebaseEgressDBG" 414 "VCSEATP_a414_ocsMissedIngressDBG" 413 "VCSEATP_a413_ocsSBRFaulted" 412 "VCSEATP_a412_ocsRebaselineDBG" 411 "VCSEATP_a411_ocsDataTimeout" 410 "VCSEATP_a410_ocsSlowDrift" 409 "VCSEATP_a409_ocsHeatPadNoConnect" 408 "VCSEATP_a408_ocsSensorDroop" 407 "VCSEATP_a407_ocsManufactureInvld" 406 "VCSEATP_a406_ocsCalibMismatch" 405 "VCSEATP_a405_ocsSensorDisconnect" 404 "VCSEATP_a404_ocsBackDisconnect" 403 "VCSEATP_a403_ocsSensorHigh" 402 "VCSEATP_a402_ocsSensorLow" 401 "VCSEATP_a401_ocsDiagContext" 400 "VCSEATP_a400_ocsCushionMismatch" 399 "VCSEATP_a399_ocsTHMIA" 398 "VCSEATP_a398_ocsTOSMIA" 397 "VCSEATP_a397_ocsTHInvalCalib" 396 "VCSEATP_a396_ocsSpareInvalCalib" 394 "VCSEATP_a394_ocsCushionInvlCalib" 393 "VCSEATP_a393_ocsTHNoCalib" 392 "VCSEATP_a392_ocsSpareNoCalib" 390 "VCSEATP_a390_ocsCushionNoCalib" 389 "VCSEATP_a389_ocsTHInvalid" 388 "VCSEATP_a388_ocsSpareShort" 387 "VCSEATP_a387_ocsSpareLow" 386 "VCSEATP_a386_ocsSpareHigh" 382 "VCSEATP_a382_ocsCushionShort" 381 "VCSEATP_a381_ocsCushionLow" 380 "VCSEATP_a380_ocsCushionHigh" 291 "VCSEATP_a291_buckleFaultedFront" 290 "VCSEATP_a290_occupancyFaultFront" 270 "VCSEATP_a270_seatLiftHCEncStlDbg" 269 "VCSEATP_a269_seatTiltHCEncStlDbg" 268 "VCSEATP_a268_seatBackHCEncStlDbg" 267 "VCSEATP_a267_seatTrackHCEncStl" 266 "VCSEATP_a266_seatLiftStallDebug" 265 "VCSEATP_a265_seatTiltStallDebug" 264 "VCSEATP_a264_seatBackStallDebug" 263 "VCSEATP_a263_seatTrackStallDebug" 254 "VCSEATP_a254_seatUncalLift" 253 "VCSEATP_a253_seatUncalTilt" 252 "VCSEATP_a252_seatUncalBack" 251 "VCSEATP_a251_seatUncalTrack" 242 "VCSEATP_a242_seatHeatTmpFront" 241 "VCSEATP_a241_seatHeatMIAFront" 240 "VCSEATP_a240_seatHeatShortFront" 239 "VCSEATP_a239_seatHeatIFront" 238 "VCSEATP_a238_lumbarValveMIA" 237 "VCSEATP_a237_lumbarOverPresB" 236 "VCSEATP_a236_lumbarOverPresA" 235 "VCSEATP_a235_seatCurrUnderLift" 234 "VCSEATP_a234_seatCurrUnderTilt" 233 "VCSEATP_a233_seatCurrUnderBack" 232 "VCSEATP_a232_seatCurrUnderTrack" 231 "VCSEATP_a231_seatEncOverLift" 230 "VCSEATP_a230_seatEncOverTilt" 229 "VCSEATP_a229_seatEncOverBack" 228 "VCSEATP_a228_seatEncOverTrack" 227 "VCSEATP_a227_seatEncStallLift" 226 "VCSEATP_a226_seatEncStallTilt" 225 "VCSEATP_a225_seatEncStallBack" 224 "VCSEATP_a224_seatEncStallTrack" 223 "VCSEATP_a223_seatCurrStallLift" 222 "VCSEATP_a222_seatCurrStallTilt" 221 "VCSEATP_a221_seatCurrStallBack" 220 "VCSEATP_a220_seatCurrStallTrack" 219 "VCSEATP_a219_motorCurrentDropout" 218 "VCSEATP_a218_motorDriverFault" 201 "VCSEATP_a201_motorDutyEncDisabl" 200 "VCSEATP_a200_motorPhantomEncoder" 64 "VCSEATP_a064_busSleepReqTimeout" 63 "VCSEATP_a063_SwitchFault" 62 "VCSEATP_a062_XCPWasConnected" 61 "VCSEATP_a061_XCPConnected" 60 "VCSEATP_a060_engineeringBuild" 59 "VCSEATP_a059_inputResistanceHigh" 58 "VCSEATP_a058_inputRHighSyncDebug" 46 "VCSEATP_a046_Task1000msError" 45 "VCSEATP_a045_Task100msError" 44 "VCSEATP_a044_Task10msError" 43 "VCSEATP_a043_Task1msError" 42 "VCSEATP_a042_HighStackUsage" 41 "VCSEATP_a041_HighCPULoad" 31 "VCSEATP_a031_UDSActive" 30 "VCSEATP_a030_ECULogUploadRequest" 22 "VCSEATP_a022_TaskInitError" 21 "VCSEATP_a021_TaskSchedulerError" 15 "VCSEATP_a015_NVMMAlert" 13 "VCSEATP_a013_AlertManagerFault" 12 "VCSEATP_a012_CPUReset" 10 "VCSEATP_a010_ExtSupplyVoltError" 5 "VCSEATP_a005_CANTXError" 3 "VCSEATP_a003_SWAssertion" 2 "VCSEATP_a002_PowerLossReset" 1 "VCSEATP_a001_WatchdogReset" 0 "VCSEATP_ALERT_DO_NOT_USE_ZERO" ;
VAL_ 1374 VCSEATP_alertType 1 "ALERT_SET" 0 "ALERT_CLEARED" ;
VAL_ 1374 VCSEATP_a058_faultReason 1 "INPUT_POWER_SYNC_FAULT_REASON_DELTA_THRESHOLD" 0 "INPUT_POWER_SYNC_FAULT_REASON_THRESHOLD" ;
VAL_ 1374 VCSEATP_a220_seatMotorState 5 "SEAT_STATE_UNDEFINED" 4 "SEAT_STATE_CALIBRATING" 3 "SEAT_STATE_RECALLING" 2 "SEAT_STATE_MOVING_DOWN" 1 "SEAT_STATE_MOVING_UP" 0 "SEAT_STATE_STOPPED" ;
VAL_ 1374 VCSEATP_a220_seatSwitchBack 3 "SWITCH_SNA" 2 "SWITCH_FAULT" 1 "SWITCH_ON" 0 "SWITCH_OFF" ;
VAL_ 1374 VCSEATP_a220_seatSwitchForward 3 "SWITCH_SNA" 2 "SWITCH_FAULT" 1 "SWITCH_ON" 0 "SWITCH_OFF" ;
VAL_ 1374 VCSEATP_a221_seatMotorState 5 "SEAT_STATE_UNDEFINED" 4 "SEAT_STATE_CALIBRATING" 3 "SEAT_STATE_RECALLING" 2 "SEAT_STATE_MOVING_DOWN" 1 "SEAT_STATE_MOVING_UP" 0 "SEAT_STATE_STOPPED" ;
VAL_ 1374 VCSEATP_a221_seatSwitchBack 3 "SWITCH_SNA" 2 "SWITCH_FAULT" 1 "SWITCH_ON" 0 "SWITCH_OFF" ;
VAL_ 1374 VCSEATP_a221_seatSwitchForward 3 "SWITCH_SNA" 2 "SWITCH_FAULT" 1 "SWITCH_ON" 0 "SWITCH_OFF" ;
VAL_ 1374 VCSEATP_a222_seatMotorState 5 "SEAT_STATE_UNDEFINED" 4 "SEAT_STATE_CALIBRATING" 3 "SEAT_STATE_RECALLING" 2 "SEAT_STATE_MOVING_DOWN" 1 "SEAT_STATE_MOVING_UP" 0 "SEAT_STATE_STOPPED" ;
VAL_ 1374 VCSEATP_a222_seatSwitchBack 3 "SWITCH_SNA" 2 "SWITCH_FAULT" 1 "SWITCH_ON" 0 "SWITCH_OFF" ;
VAL_ 1374 VCSEATP_a222_seatSwitchForward 3 "SWITCH_SNA" 2 "SWITCH_FAULT" 1 "SWITCH_ON" 0 "SWITCH_OFF" ;
VAL_ 1374 VCSEATP_a223_seatMotorState 5 "SEAT_STATE_UNDEFINED" 4 "SEAT_STATE_CALIBRATING" 3 "SEAT_STATE_RECALLING" 2 "SEAT_STATE_MOVING_DOWN" 1 "SEAT_STATE_MOVING_UP" 0 "SEAT_STATE_STOPPED" ;
VAL_ 1374 VCSEATP_a223_seatSwitchBack 3 "SWITCH_SNA" 2 "SWITCH_FAULT" 1 "SWITCH_ON" 0 "SWITCH_OFF" ;
VAL_ 1374 VCSEATP_a223_seatSwitchForward 3 "SWITCH_SNA" 2 "SWITCH_FAULT" 1 "SWITCH_ON" 0 "SWITCH_OFF" ;
VAL_ 1374 VCSEATP_a224_seatMotorState 5 "SEAT_STATE_UNDEFINED" 4 "SEAT_STATE_CALIBRATING" 3 "SEAT_STATE_RECALLING" 2 "SEAT_STATE_MOVING_DOWN" 1 "SEAT_STATE_MOVING_UP" 0 "SEAT_STATE_STOPPED" ;
VAL_ 1374 VCSEATP_a224_seatSwitchBack 3 "SWITCH_SNA" 2 "SWITCH_FAULT" 1 "SWITCH_ON" 0 "SWITCH_OFF" ;
VAL_ 1374 VCSEATP_a224_seatSwitchForward 3 "SWITCH_SNA" 2 "SWITCH_FAULT" 1 "SWITCH_ON" 0 "SWITCH_OFF" ;
VAL_ 1374 VCSEATP_a225_seatMotorState 5 "SEAT_STATE_UNDEFINED" 4 "SEAT_STATE_CALIBRATING" 3 "SEAT_STATE_RECALLING" 2 "SEAT_STATE_MOVING_DOWN" 1 "SEAT_STATE_MOVING_UP" 0 "SEAT_STATE_STOPPED" ;
VAL_ 1374 VCSEATP_a225_seatSwitchBack 3 "SWITCH_SNA" 2 "SWITCH_FAULT" 1 "SWITCH_ON" 0 "SWITCH_OFF" ;
VAL_ 1374 VCSEATP_a225_seatSwitchForward 3 "SWITCH_SNA" 2 "SWITCH_FAULT" 1 "SWITCH_ON" 0 "SWITCH_OFF" ;
VAL_ 1374 VCSEATP_a226_seatMotorState 5 "SEAT_STATE_UNDEFINED" 4 "SEAT_STATE_CALIBRATING" 3 "SEAT_STATE_RECALLING" 2 "SEAT_STATE_MOVING_DOWN" 1 "SEAT_STATE_MOVING_UP" 0 "SEAT_STATE_STOPPED" ;
VAL_ 1374 VCSEATP_a226_seatSwitchBack 3 "SWITCH_SNA" 2 "SWITCH_FAULT" 1 "SWITCH_ON" 0 "SWITCH_OFF" ;
VAL_ 1374 VCSEATP_a226_seatSwitchForward 3 "SWITCH_SNA" 2 "SWITCH_FAULT" 1 "SWITCH_ON" 0 "SWITCH_OFF" ;
VAL_ 1374 VCSEATP_a227_seatMotorState 5 "SEAT_STATE_UNDEFINED" 4 "SEAT_STATE_CALIBRATING" 3 "SEAT_STATE_RECALLING" 2 "SEAT_STATE_MOVING_DOWN" 1 "SEAT_STATE_MOVING_UP" 0 "SEAT_STATE_STOPPED" ;
VAL_ 1374 VCSEATP_a227_seatSwitchBack 3 "SWITCH_SNA" 2 "SWITCH_FAULT" 1 "SWITCH_ON" 0 "SWITCH_OFF" ;
VAL_ 1374 VCSEATP_a227_seatSwitchForward 3 "SWITCH_SNA" 2 "SWITCH_FAULT" 1 "SWITCH_ON" 0 "SWITCH_OFF" ;
VAL_ 1374 VCSEATP_a228_seatMotorState 5 "SEAT_STATE_UNDEFINED" 4 "SEAT_STATE_CALIBRATING" 3 "SEAT_STATE_RECALLING" 2 "SEAT_STATE_MOVING_DOWN" 1 "SEAT_STATE_MOVING_UP" 0 "SEAT_STATE_STOPPED" ;
VAL_ 1374 VCSEATP_a228_seatSwitchBack 3 "SWITCH_SNA" 2 "SWITCH_FAULT" 1 "SWITCH_ON" 0 "SWITCH_OFF" ;
VAL_ 1374 VCSEATP_a228_seatSwitchForward 3 "SWITCH_SNA" 2 "SWITCH_FAULT" 1 "SWITCH_ON" 0 "SWITCH_OFF" ;
VAL_ 1374 VCSEATP_a229_seatMotorState 5 "SEAT_STATE_UNDEFINED" 4 "SEAT_STATE_CALIBRATING" 3 "SEAT_STATE_RECALLING" 2 "SEAT_STATE_MOVING_DOWN" 1 "SEAT_STATE_MOVING_UP" 0 "SEAT_STATE_STOPPED" ;
VAL_ 1374 VCSEATP_a229_seatSwitchBack 3 "SWITCH_SNA" 2 "SWITCH_FAULT" 1 "SWITCH_ON" 0 "SWITCH_OFF" ;
VAL_ 1374 VCSEATP_a229_seatSwitchForward 3 "SWITCH_SNA" 2 "SWITCH_FAULT" 1 "SWITCH_ON" 0 "SWITCH_OFF" ;
VAL_ 1374 VCSEATP_a230_seatMotorState 5 "SEAT_STATE_UNDEFINED" 4 "SEAT_STATE_CALIBRATING" 3 "SEAT_STATE_RECALLING" 2 "SEAT_STATE_MOVING_DOWN" 1 "SEAT_STATE_MOVING_UP" 0 "SEAT_STATE_STOPPED" ;
VAL_ 1374 VCSEATP_a230_seatSwitchBack 3 "SWITCH_SNA" 2 "SWITCH_FAULT" 1 "SWITCH_ON" 0 "SWITCH_OFF" ;
VAL_ 1374 VCSEATP_a230_seatSwitchForward 3 "SWITCH_SNA" 2 "SWITCH_FAULT" 1 "SWITCH_ON" 0 "SWITCH_OFF" ;
VAL_ 1374 VCSEATP_a231_seatMotorState 5 "SEAT_STATE_UNDEFINED" 4 "SEAT_STATE_CALIBRATING" 3 "SEAT_STATE_RECALLING" 2 "SEAT_STATE_MOVING_DOWN" 1 "SEAT_STATE_MOVING_UP" 0 "SEAT_STATE_STOPPED" ;
VAL_ 1374 VCSEATP_a231_seatSwitchBack 3 "SWITCH_SNA" 2 "SWITCH_FAULT" 1 "SWITCH_ON" 0 "SWITCH_OFF" ;
VAL_ 1374 VCSEATP_a231_seatSwitchForward 3 "SWITCH_SNA" 2 "SWITCH_FAULT" 1 "SWITCH_ON" 0 "SWITCH_OFF" ;
VAL_ 1374 VCSEATP_a232_seatMotorState 5 "SEAT_STATE_UNDEFINED" 4 "SEAT_STATE_CALIBRATING" 3 "SEAT_STATE_RECALLING" 2 "SEAT_STATE_MOVING_DOWN" 1 "SEAT_STATE_MOVING_UP" 0 "SEAT_STATE_STOPPED" ;
VAL_ 1374 VCSEATP_a232_seatSwitchBack 3 "SWITCH_SNA" 2 "SWITCH_FAULT" 1 "SWITCH_ON" 0 "SWITCH_OFF" ;
VAL_ 1374 VCSEATP_a232_seatSwitchForward 3 "SWITCH_SNA" 2 "SWITCH_FAULT" 1 "SWITCH_ON" 0 "SWITCH_OFF" ;
VAL_ 1374 VCSEATP_a233_seatMotorState 5 "SEAT_STATE_UNDEFINED" 4 "SEAT_STATE_CALIBRATING" 3 "SEAT_STATE_RECALLING" 2 "SEAT_STATE_MOVING_DOWN" 1 "SEAT_STATE_MOVING_UP" 0 "SEAT_STATE_STOPPED" ;
VAL_ 1374 VCSEATP_a233_seatSwitchBack 3 "SWITCH_SNA" 2 "SWITCH_FAULT" 1 "SWITCH_ON" 0 "SWITCH_OFF" ;
VAL_ 1374 VCSEATP_a233_seatSwitchForward 3 "SWITCH_SNA" 2 "SWITCH_FAULT" 1 "SWITCH_ON" 0 "SWITCH_OFF" ;
VAL_ 1374 VCSEATP_a234_seatMotorState 5 "SEAT_STATE_UNDEFINED" 4 "SEAT_STATE_CALIBRATING" 3 "SEAT_STATE_RECALLING" 2 "SEAT_STATE_MOVING_DOWN" 1 "SEAT_STATE_MOVING_UP" 0 "SEAT_STATE_STOPPED" ;
VAL_ 1374 VCSEATP_a234_seatSwitchBack 3 "SWITCH_SNA" 2 "SWITCH_FAULT" 1 "SWITCH_ON" 0 "SWITCH_OFF" ;
VAL_ 1374 VCSEATP_a234_seatSwitchForward 3 "SWITCH_SNA" 2 "SWITCH_FAULT" 1 "SWITCH_ON" 0 "SWITCH_OFF" ;
VAL_ 1374 VCSEATP_a235_seatMotorState 5 "SEAT_STATE_UNDEFINED" 4 "SEAT_STATE_CALIBRATING" 3 "SEAT_STATE_RECALLING" 2 "SEAT_STATE_MOVING_DOWN" 1 "SEAT_STATE_MOVING_UP" 0 "SEAT_STATE_STOPPED" ;
VAL_ 1374 VCSEATP_a235_seatSwitchBack 3 "SWITCH_SNA" 2 "SWITCH_FAULT" 1 "SWITCH_ON" 0 "SWITCH_OFF" ;
VAL_ 1374 VCSEATP_a235_seatSwitchForward 3 "SWITCH_SNA" 2 "SWITCH_FAULT" 1 "SWITCH_ON" 0 "SWITCH_OFF" ;
VAL_ 1374 VCSEATP_a236_lumbarAState 5 "SEAT_STATE_UNDEFINED" 4 "SEAT_STATE_CALIBRATING" 3 "SEAT_STATE_RECALLING" 2 "SEAT_STATE_MOVING_DOWN" 1 "SEAT_STATE_MOVING_UP" 0 "SEAT_STATE_STOPPED" ;
VAL_ 1374 VCSEATP_a236_lumbarBState 5 "SEAT_STATE_UNDEFINED" 4 "SEAT_STATE_CALIBRATING" 3 "SEAT_STATE_RECALLING" 2 "SEAT_STATE_MOVING_DOWN" 1 "SEAT_STATE_MOVING_UP" 0 "SEAT_STATE_STOPPED" ;
VAL_ 1374 VCSEATP_a237_lumbarAState 5 "SEAT_STATE_UNDEFINED" 4 "SEAT_STATE_CALIBRATING" 3 "SEAT_STATE_RECALLING" 2 "SEAT_STATE_MOVING_DOWN" 1 "SEAT_STATE_MOVING_UP" 0 "SEAT_STATE_STOPPED" ;
VAL_ 1374 VCSEATP_a237_lumbarBState 5 "SEAT_STATE_UNDEFINED" 4 "SEAT_STATE_CALIBRATING" 3 "SEAT_STATE_RECALLING" 2 "SEAT_STATE_MOVING_DOWN" 1 "SEAT_STATE_MOVING_UP" 0 "SEAT_STATE_STOPPED" ;
VAL_ 1374 VCSEATP_a238_lumbarAState 5 "SEAT_STATE_UNDEFINED" 4 "SEAT_STATE_CALIBRATING" 3 "SEAT_STATE_RECALLING" 2 "SEAT_STATE_MOVING_DOWN" 1 "SEAT_STATE_MOVING_UP" 0 "SEAT_STATE_STOPPED" ;
VAL_ 1374 VCSEATP_a238_lumbarBState 5 "SEAT_STATE_UNDEFINED" 4 "SEAT_STATE_CALIBRATING" 3 "SEAT_STATE_RECALLING" 2 "SEAT_STATE_MOVING_DOWN" 1 "SEAT_STATE_MOVING_UP" 0 "SEAT_STATE_STOPPED" ;
VAL_ 1374 VCSEATP_a251_seatMotorState 5 "SEAT_STATE_UNDEFINED" 4 "SEAT_STATE_CALIBRATING" 3 "SEAT_STATE_RECALLING" 2 "SEAT_STATE_MOVING_DOWN" 1 "SEAT_STATE_MOVING_UP" 0 "SEAT_STATE_STOPPED" ;
VAL_ 1374 VCSEATP_a251_seatSwitchBack 3 "SWITCH_SNA" 2 "SWITCH_FAULT" 1 "SWITCH_ON" 0 "SWITCH_OFF" ;
VAL_ 1374 VCSEATP_a251_seatSwitchForward 3 "SWITCH_SNA" 2 "SWITCH_FAULT" 1 "SWITCH_ON" 0 "SWITCH_OFF" ;
VAL_ 1374 VCSEATP_a252_seatMotorState 5 "SEAT_STATE_UNDEFINED" 4 "SEAT_STATE_CALIBRATING" 3 "SEAT_STATE_RECALLING" 2 "SEAT_STATE_MOVING_DOWN" 1 "SEAT_STATE_MOVING_UP" 0 "SEAT_STATE_STOPPED" ;
VAL_ 1374 VCSEATP_a252_seatSwitchBack 3 "SWITCH_SNA" 2 "SWITCH_FAULT" 1 "SWITCH_ON" 0 "SWITCH_OFF" ;
VAL_ 1374 VCSEATP_a252_seatSwitchForward 3 "SWITCH_SNA" 2 "SWITCH_FAULT" 1 "SWITCH_ON" 0 "SWITCH_OFF" ;
VAL_ 1374 VCSEATP_a253_seatMotorState 5 "SEAT_STATE_UNDEFINED" 4 "SEAT_STATE_CALIBRATING" 3 "SEAT_STATE_RECALLING" 2 "SEAT_STATE_MOVING_DOWN" 1 "SEAT_STATE_MOVING_UP" 0 "SEAT_STATE_STOPPED" ;
VAL_ 1374 VCSEATP_a253_seatSwitchBack 3 "SWITCH_SNA" 2 "SWITCH_FAULT" 1 "SWITCH_ON" 0 "SWITCH_OFF" ;
VAL_ 1374 VCSEATP_a253_seatSwitchForward 3 "SWITCH_SNA" 2 "SWITCH_FAULT" 1 "SWITCH_ON" 0 "SWITCH_OFF" ;
VAL_ 1374 VCSEATP_a254_seatMotorState 5 "SEAT_STATE_UNDEFINED" 4 "SEAT_STATE_CALIBRATING" 3 "SEAT_STATE_RECALLING" 2 "SEAT_STATE_MOVING_DOWN" 1 "SEAT_STATE_MOVING_UP" 0 "SEAT_STATE_STOPPED" ;
VAL_ 1374 VCSEATP_a254_seatSwitchBack 3 "SWITCH_SNA" 2 "SWITCH_FAULT" 1 "SWITCH_ON" 0 "SWITCH_OFF" ;
VAL_ 1374 VCSEATP_a254_seatSwitchForward 3 "SWITCH_SNA" 2 "SWITCH_FAULT" 1 "SWITCH_ON" 0 "SWITCH_OFF" ;
VAL_ 1374 VCSEATP_a263_seatMotorState 5 "SEAT_STATE_UNDEFINED" 4 "SEAT_STATE_CALIBRATING" 3 "SEAT_STATE_RECALLING" 2 "SEAT_STATE_MOVING_DOWN" 1 "SEAT_STATE_MOVING_UP" 0 "SEAT_STATE_STOPPED" ;
VAL_ 1374 VCSEATP_a264_seatMotorState 5 "SEAT_STATE_UNDEFINED" 4 "SEAT_STATE_CALIBRATING" 3 "SEAT_STATE_RECALLING" 2 "SEAT_STATE_MOVING_DOWN" 1 "SEAT_STATE_MOVING_UP" 0 "SEAT_STATE_STOPPED" ;
VAL_ 1374 VCSEATP_a265_seatMotorState 5 "SEAT_STATE_UNDEFINED" 4 "SEAT_STATE_CALIBRATING" 3 "SEAT_STATE_RECALLING" 2 "SEAT_STATE_MOVING_DOWN" 1 "SEAT_STATE_MOVING_UP" 0 "SEAT_STATE_STOPPED" ;
VAL_ 1374 VCSEATP_a266_seatMotorState 5 "SEAT_STATE_UNDEFINED" 4 "SEAT_STATE_CALIBRATING" 3 "SEAT_STATE_RECALLING" 2 "SEAT_STATE_MOVING_DOWN" 1 "SEAT_STATE_MOVING_UP" 0 "SEAT_STATE_STOPPED" ;
VAL_ 1374 VCSEATP_a267_seatMotorState 5 "SEAT_STATE_UNDEFINED" 4 "SEAT_STATE_CALIBRATING" 3 "SEAT_STATE_RECALLING" 2 "SEAT_STATE_MOVING_DOWN" 1 "SEAT_STATE_MOVING_UP" 0 "SEAT_STATE_STOPPED" ;
VAL_ 1374 VCSEATP_a268_seatMotorState 5 "SEAT_STATE_UNDEFINED" 4 "SEAT_STATE_CALIBRATING" 3 "SEAT_STATE_RECALLING" 2 "SEAT_STATE_MOVING_DOWN" 1 "SEAT_STATE_MOVING_UP" 0 "SEAT_STATE_STOPPED" ;
VAL_ 1374 VCSEATP_a269_seatMotorState 5 "SEAT_STATE_UNDEFINED" 4 "SEAT_STATE_CALIBRATING" 3 "SEAT_STATE_RECALLING" 2 "SEAT_STATE_MOVING_DOWN" 1 "SEAT_STATE_MOVING_UP" 0 "SEAT_STATE_STOPPED" ;
VAL_ 1374 VCSEATP_a270_seatMotorState 5 "SEAT_STATE_UNDEFINED" 4 "SEAT_STATE_CALIBRATING" 3 "SEAT_STATE_RECALLING" 2 "SEAT_STATE_MOVING_DOWN" 1 "SEAT_STATE_MOVING_UP" 0 "SEAT_STATE_STOPPED" ;
VAL_ 1374 VCSEATP_a401_occupancySwitch 3 "SWITCH_SNA" 2 "SWITCH_FAULT" 1 "SWITCH_ON" 0 "SWITCH_OFF" ;
VAL_ 1374 VCSEATP_a415_occupancyTimeMins 65535 "SNA" ;
VAL_ 999 VCSEATP_matrixIndex 7 "VCSEATP_AlertMatrix7" 6 "VCSEATP_AlertMatrix6" 4 "VCSEATP_AlertMatrix4" 3 "VCSEATP_AlertMatrix3" 1 "VCSEATP_AlertMatrix1" 0 "VCSEATP_AlertMatrix0" ;
VAL_ 867 VCSEATP_crashDetectedType 3 "CRASH_DETECTED_TYPE_SEVERE" 2 "CRASH_DETECTED_TYPE_MINOR_2" 1 "CRASH_DETECTED_TYPE_MINOR_1" 0 "CRASH_DETECTED_TYPE_NONE" ;
VAL_ 867 VCSEATP_crashState 3 "CRASH_STATE_SEVERE" 2 "CRASH_STATE_MINOR_2" 1 "CRASH_STATE_MINOR_1" 0 "CRASH_STATE_IDLE" ;
VAL_ 773 VCSEATP_infoIndex 255 "BC_INFO_END" 33 "BC_INFO_SUBCOMPONENT6" 32 "BC_INFO_SUBCOMPONENT5" 31 "BC_INFO_SUBCOMPONENT4" 24 "BC_INFO_SUBCOMPONENT3" 23 "BC_INFO_SUBCOMPONENT2" 20 "BC_INFO_UDS_PROTOCOL_BOOTCRC" 19 "BC_INFO_VERSION_DEPRECATED" 18 "BC_INFO_BOOTLOADER_GITHASH" 17 "BC_INFO_APP_GITHASH" 16 "BC_INFO_SUBCOMPONENT1" 15 "BC_INFO_BOOTLOADER_CRC" 14 "BC_INFO_BOOTLOADER_SVN" 13 "BC_INFO_APP_CRC" 11 "BC_INFO_PCBAID_ASSYID_USAGEID" 10 "BC_INFO_BUILD_HWID_COMPONENTID" 9 "BC_INFO_DEPRECATED_9" 8 "BC_INFO_DEPRECATED_8" 7 "BC_INFO_DEPRECATED_7" 6 "BC_INFO_DEPRECATED_6" 5 "BC_INFO_DEPRECATED_5" 4 "BC_INFO_DEPRECATED_4" 3 "BC_INFO_DEPRECATED_3" 2 "BC_INFO_DEPRECATED_2" 1 "BC_INFO_DEPRECATED_1" 0 "BC_INFO_DEPRECATED_0" ;
VAL_ 773 VCSEATP_infoBuildType 4 "INFO_MFG_BUILD" 3 "INFO_TRACEABLE_CI_BUILD" 2 "INFO_LOCAL_BUILD" 1 "INFO_PLATFORM_BUILD" 0 "INFO_UNKNOWN_BUILD" ;
VAL_ 773 VCSEATP_infoAssemblyId 255 "ASSEMBLY_SNA" 1 "ASSEMBLY1" ;
VAL_ 1842 VCSEATP_ocsSensorStatusIndex 6 "OCS_SENSOR_STATUS_INDEX_COUNT" 5 "OCS_SENSOR_STATUS_INDEX_DSS1" 4 "OCS_SENSOR_STATUS_INDEX_DSS0" 3 "OCS_SENSOR_STATUS_INDEX_TOS2" 2 "OCS_SENSOR_STATUS_INDEX_TOS1" 1 "OCS_SENSOR_STATUS_INDEX_TEMP" 0 "OCS_SENSOR_STATUS_INDEX_TOS0" ;
VAL_ 1842 VCSEATP_classificationRaw 7 "SEAT_OCCUPANT_CLASSIFICATON_SNA" 5 "SEAT_OCCUPANT_CLASSIFICATON_NOT_CONFIGURED" 4 "SEAT_OCCUPANT_CLASSIFICATON_INIT" 3 "SEAT_OCCUPANT_CLASSIFICATON_LARGE" 2 "SEAT_OCCUPANT_CLASSIFICATON_SMALL" 1 "SEAT_OCCUPANT_CLASSIFICATON_INHIBIT" 0 "SEAT_OCCUPANT_CLASSIFICATON_EMPTY" ;
VAL_ 1844 VCSEATP_ocsSensorStatus2Index 3 "OCS_SENSOR_STATUS2_INDEX_COUNT" 2 "OCS_SENSOR_STATUS2_INDEX_CALIB2" 1 "OCS_SENSOR_STATUS2_INDEX_CALIB1" 0 "OCS_SENSOR_STATUS2_INDEX_CALIB0" ;
VAL_ 1861 VCSEATP_systemRecallStatus 3 "RECALL_INTERRUPTED" 2 "RECALL_COMPLETE" 1 "RECALL_IN_PROGRESS" 0 "RECALL_SNA" ;
VAL_ 1861 VCSEATP_seatRecallStatus 3 "RECALL_INTERRUPTED" 2 "RECALL_COMPLETE" 1 "RECALL_IN_PROGRESS" 0 "RECALL_SNA" ;
VAL_ 779 VCSEATP_occupantClassification 7 "SEAT_OCCUPANT_CLASSIFICATON_SNA" 5 "SEAT_OCCUPANT_CLASSIFICATON_NOT_CONFIGURED" 4 "SEAT_OCCUPANT_CLASSIFICATON_INIT" 3 "SEAT_OCCUPANT_CLASSIFICATON_LARGE" 2 "SEAT_OCCUPANT_CLASSIFICATON_SMALL" 1 "SEAT_OCCUPANT_CLASSIFICATON_INHIBIT" 0 "SEAT_OCCUPANT_CLASSIFICATON_EMPTY" ;
VAL_ 779 VCSEATP_occupantClassificationQF 1 "SEAT_OCCUPANT_CLASSIFICATON_NOT_FAULTED" 0 "SEAT_OCCUPANT_CLASSIFICATON_FAULTED" ;
VAL_ 779 VCSEATP_occupancyStatus 7 "VCSEAT_OCCUPANCY_SNA" 3 "VCSEAT_NOT_CONFIGURED" 2 "VCSEAT_OCCUPANCY_FAULTED" 1 "VCSEAT_OCCUPIED" 0 "VCSEAT_UNOCCUPIED" ;
VAL_ 779 VCSEATP_buckleStatus 3 "VCSEAT_BELT_BUCKLE_STATUS_SNA" 2 "VCSEAT_BELT_BUCKLE_STATUS_FAULTED" 1 "VCSEAT_BELT_BUCKLE_STATUS_LATCHED" 0 "VCSEAT_BELT_BUCKLE_STATUS_UNLATCHED" ;
VAL_ 779 VCSEATP_seatTrackPosition 7 "SEAT_TRACK_POSITION_SNA" 3 "SEAT_TRACK_POSITION_FAULTED" 2 "SEAT_TRACK_POSITION_NOT_CONFIGURED" 1 "SEAT_TRACK_POSITION_REARWARD" 0 "SEAT_TRACK_POSITION_FORWARD" ;
VAL_ 779 VCSEATP_absSeatTrackPosition 255 "ABS_SEAT_TRACK_POSITION_SNA" 254 "ABS_SEAT_TRACK_POSITION_NOT_CONFIGURED" ;
VAL_ 1251 VCSEATP_seatStatusIndex 5 "SEAT_STATUS_INDEX_POSITION" 4 "SEAT_STATUS_INDEX_LUMBAR" 3 "SEAT_STATUS_INDEX_TILT" 2 "SEAT_STATUS_INDEX_LIFT" 1 "SEAT_STATUS_INDEX_BACK" 0 "SEAT_STATUS_INDEX_TRACK" ;
VAL_ 1251 VCSEATP_frontSeatTrackState 5 "SEAT_STATE_UNDEFINED" 4 "SEAT_STATE_CALIBRATING" 3 "SEAT_STATE_RECALLING" 2 "SEAT_STATE_MOVING_DOWN" 1 "SEAT_STATE_MOVING_UP" 0 "SEAT_STATE_STOPPED" ;
VAL_ 1251 VCSEATP_frontSeatBackState 5 "SEAT_STATE_UNDEFINED" 4 "SEAT_STATE_CALIBRATING" 3 "SEAT_STATE_RECALLING" 2 "SEAT_STATE_MOVING_DOWN" 1 "SEAT_STATE_MOVING_UP" 0 "SEAT_STATE_STOPPED" ;
VAL_ 1251 VCSEATP_frontSeatLiftState 5 "SEAT_STATE_UNDEFINED" 4 "SEAT_STATE_CALIBRATING" 3 "SEAT_STATE_RECALLING" 2 "SEAT_STATE_MOVING_DOWN" 1 "SEAT_STATE_MOVING_UP" 0 "SEAT_STATE_STOPPED" ;
VAL_ 1251 VCSEATP_frontSeatTiltState 5 "SEAT_STATE_UNDEFINED" 4 "SEAT_STATE_CALIBRATING" 3 "SEAT_STATE_RECALLING" 2 "SEAT_STATE_MOVING_DOWN" 1 "SEAT_STATE_MOVING_UP" 0 "SEAT_STATE_STOPPED" ;
VAL_ 1251 VCSEATP_lumbarAState 5 "SEAT_STATE_UNDEFINED" 4 "SEAT_STATE_CALIBRATING" 3 "SEAT_STATE_RECALLING" 2 "SEAT_STATE_MOVING_DOWN" 1 "SEAT_STATE_MOVING_UP" 0 "SEAT_STATE_STOPPED" ;
VAL_ 1251 VCSEATP_lumbarBState 5 "SEAT_STATE_UNDEFINED" 4 "SEAT_STATE_CALIBRATING" 3 "SEAT_STATE_RECALLING" 2 "SEAT_STATE_MOVING_DOWN" 1 "SEAT_STATE_MOVING_UP" 0 "SEAT_STATE_STOPPED" ;
VAL_ 1909 VCSEATP_frontSeatTrackState10Hz 5 "SEAT_STATE_UNDEFINED" 4 "SEAT_STATE_CALIBRATING" 3 "SEAT_STATE_RECALLING" 2 "SEAT_STATE_MOVING_DOWN" 1 "SEAT_STATE_MOVING_UP" 0 "SEAT_STATE_STOPPED" ;
VAL_ 1909 VCSEATP_frontSeatBackState10Hz 5 "SEAT_STATE_UNDEFINED" 4 "SEAT_STATE_CALIBRATING" 3 "SEAT_STATE_RECALLING" 2 "SEAT_STATE_MOVING_DOWN" 1 "SEAT_STATE_MOVING_UP" 0 "SEAT_STATE_STOPPED" ;
VAL_ 1909 VCSEATP_frontSeatLiftState10Hz 5 "SEAT_STATE_UNDEFINED" 4 "SEAT_STATE_CALIBRATING" 3 "SEAT_STATE_RECALLING" 2 "SEAT_STATE_MOVING_DOWN" 1 "SEAT_STATE_MOVING_UP" 0 "SEAT_STATE_STOPPED" ;
VAL_ 1909 VCSEATP_frontSeatTiltState10Hz 5 "SEAT_STATE_UNDEFINED" 4 "SEAT_STATE_CALIBRATING" 3 "SEAT_STATE_RECALLING" 2 "SEAT_STATE_MOVING_DOWN" 1 "SEAT_STATE_MOVING_UP" 0 "SEAT_STATE_STOPPED" ;
VAL_ 740 VCSEATP_seatStatus2Index 3 "VCSEAT1_SEAT_STATUS_2_INDEX_COUNT" 2 "VCSEAT1_OCCUPANCY" 1 "VCSEAT1_SEAT_VOLTAGES" 0 "VCSEAT1_SEAT_HEAT_FRONT" ;
VAL_ 932 VCSEATP_statusIndex 1 "MUX1" 0 "MUX0" ;
VAL_ 932 VCSEATP_vehiclePowerStateDBG 3 "VEHICLE_POWER_STATE_DRIVE" 2 "VEHICLE_POWER_STATE_ACCESSORY" 1 "VEHICLE_POWER_STATE_CONDITIONING" 0 "VEHICLE_POWER_STATE_OFF" ;
VAL_ 965 VCSEATP_switchStatusIndex 2 "VCSEAT1_SWITCH_STATUS_INDEX_INVALID" 1 "VCSEAT1_SWITCH_STATUS_INDEX_1" 0 "VCSEAT1_SWITCH_STATUS_INDEX_0" ;
VAL_ 965 VCSEATP_frontSeatTrackBack 3 "SWITCH_SNA" 2 "SWITCH_FAULT" 1 "SWITCH_ON" 0 "SWITCH_OFF" ;
VAL_ 965 VCSEATP_frontSeatTrackForward 3 "SWITCH_SNA" 2 "SWITCH_FAULT" 1 "SWITCH_ON" 0 "SWITCH_OFF" ;
VAL_ 965 VCSEATP_frontSeatTiltDown 3 "SWITCH_SNA" 2 "SWITCH_FAULT" 1 "SWITCH_ON" 0 "SWITCH_OFF" ;
VAL_ 965 VCSEATP_frontSeatTiltUp 3 "SWITCH_SNA" 2 "SWITCH_FAULT" 1 "SWITCH_ON" 0 "SWITCH_OFF" ;
VAL_ 965 VCSEATP_frontSeatLiftDown 3 "SWITCH_SNA" 2 "SWITCH_FAULT" 1 "SWITCH_ON" 0 "SWITCH_OFF" ;
VAL_ 965 VCSEATP_frontSeatLiftUp 3 "SWITCH_SNA" 2 "SWITCH_FAULT" 1 "SWITCH_ON" 0 "SWITCH_OFF" ;
VAL_ 965 VCSEATP_frontSeatBackrestBack 3 "SWITCH_SNA" 2 "SWITCH_FAULT" 1 "SWITCH_ON" 0 "SWITCH_OFF" ;
VAL_ 965 VCSEATP_frontSeatBackrestForward 3 "SWITCH_SNA" 2 "SWITCH_FAULT" 1 "SWITCH_ON" 0 "SWITCH_OFF" ;
VAL_ 965 VCSEATP_frontSeatLumbarDown 3 "SWITCH_SNA" 2 "SWITCH_FAULT" 1 "SWITCH_ON" 0 "SWITCH_OFF" ;
VAL_ 965 VCSEATP_frontSeatLumbarUp 3 "SWITCH_SNA" 2 "SWITCH_FAULT" 1 "SWITCH_ON" 0 "SWITCH_OFF" ;
VAL_ 965 VCSEATP_frontSeatLumbarIn 3 "SWITCH_SNA" 2 "SWITCH_FAULT" 1 "SWITCH_ON" 0 "SWITCH_OFF" ;
VAL_ 965 VCSEATP_frontSeatLumbarOut 3 "SWITCH_SNA" 2 "SWITCH_FAULT" 1 "SWITCH_ON" 0 "SWITCH_OFF" ;
VAL_ 965 VCSEATP_frontBuckleSwitch 3 "SWITCH_SNA" 2 "SWITCH_FAULT" 1 "SWITCH_ON" 0 "SWITCH_OFF" ;
VAL_ 965 VCSEATP_frontOccupancySwitch 3 "SWITCH_SNA" 2 "SWITCH_FAULT" 1 "SWITCH_ON" 0 "SWITCH_OFF" ;
VAL_ 1059 VCSEATP_nmKeepAwakeReason 15 "VCSEAT1_KEEPAWAKE_REASON_MULTIPLE" 14 "VCSEAT1_KEEPAWAKE_REASON_OTHER" 9 "VCSEAT1_KEEPAWAKE_REASON_INTRUSION_SENSOR_TRIGGERED" 8 "VCSEAT1_KEEPAWAKE_REASON_UDS_ACTIVE" 7 "VCSEAT1_KEEPAWAKE_REASON_SEAT" 6 "VCSEAT1_KEEPAWAKE_REASON_HANDLE_PULLED" 5 "VCSEAT1_KEEPAWAKE_REASON_EPB_SUMMON_ACTIVE" 4 "VCSEAT1_KEEPAWAKE_REASON_CLOSURE_LATCH" 3 "VCSEAT1_KEEPAWAKE_REASON_BRAKE_SWITCH" 2 "VCSEAT1_KEEPAWAKE_REASON_EPB_NOT_SECURE" 1 "VCSEAT1_KEEPAWAKE_REASON_EPB_STATE_NOT_SAVED" 0 "VCSEAT1_KEEPAWAKE_REASON_NONE_SNA" ;
VAL_ 1059 VCSEATP_nmWakeUpReason 15 "VCSEAT1_WAKEUP_REASON_UNKNOWN" 8 "VCSEAT1_WAKEUP_REASON_LIN_RX" 7 "VCSEAT1_WAKEUP_REASON_BRAKE_SWITCH" 6 "VCSEAT1_WAKEUP_REASON_EXTERIOR_HANDLE" 5 "VCSEAT1_WAKEUP_REASON_INTERIOR_HANDLE" 4 "VCSEAT1_WAKEUP_REASON_DOOR_LATCH" 3 "VCSEAT1_WAKEUP_REASON_RESET" 2 "VCSEAT1_WAKEUP_REASON_SWITCH_INPUT" 1 "VCSEAT1_WAKEUP_REASON_ECU_SPECIFIC" 0 "VCSEAT1_WAKEUP_REASON_NONE" ;
VAL_ 1816 CH_GTW_vinDataBytesIndex 3 "SNA" 2 "HI" 1 "MID" 0 "LO" ;
